VERSION ""

NS_ :

BS_:

BU_: SGW RFHM MPAD IPC GNMM EVCU2 ESL ECM DTCM DMSM BSM BCM AGSM ADCAM

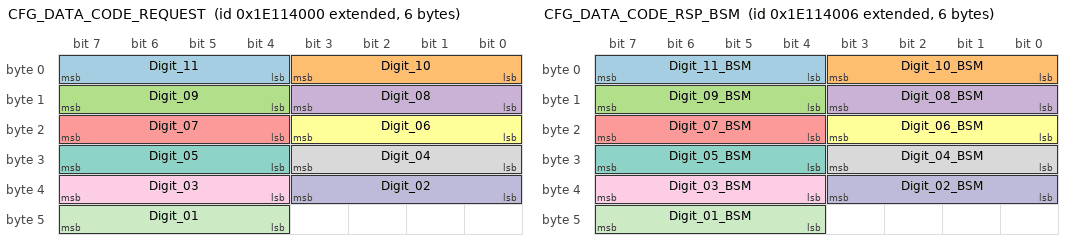
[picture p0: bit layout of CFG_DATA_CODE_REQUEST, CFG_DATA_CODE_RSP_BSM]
BO_ 2651930624 CFG_DATA_CODE_REQUEST: 6 BCM
 SG_ Digit_11 : 7|4@0+ (1,0) [0|15] "" ADCAM,MPAD,EVCU2,DMSM,GNMM,SGW,AGSM,ESL,BSM,IPC,RFHM,ECM,DTCM
 SG_ Digit_10 : 3|4@0+ (1,0) [0|15] "" ADCAM,MPAD,EVCU2,DMSM,GNMM,SGW,AGSM,ESL,BSM,IPC,RFHM,ECM,DTCM
 SG_ Digit_09 : 15|4@0+ (1,0) [0|15] "" ADCAM,MPAD,EVCU2,DMSM,GNMM,SGW,AGSM,ESL,BSM,IPC,RFHM,ECM,DTCM
 SG_ Digit_08 : 11|4@0+ (1,0) [0|15] "" ADCAM,MPAD,EVCU2,DMSM,GNMM,SGW,AGSM,ESL,BSM,IPC,RFHM,ECM,DTCM
 SG_ Digit_07 : 23|4@0+ (1,0) [0|15] "" ADCAM,MPAD,EVCU2,DMSM,GNMM,SGW,AGSM,ESL,BSM,IPC,RFHM,ECM,DTCM
 SG_ Digit_06 : 19|4@0+ (1,0) [0|15] "" ADCAM,MPAD,EVCU2,DMSM,GNMM,SGW,AGSM,ESL,BSM,IPC,RFHM,ECM,DTCM
 SG_ Digit_05 : 31|4@0+ (1,0) [0|15] "" ADCAM,MPAD,EVCU2,DMSM,GNMM,SGW,AGSM,ESL,BSM,IPC,RFHM,ECM,DTCM
 SG_ Digit_04 : 27|4@0+ (1,0) [0|15] "" ADCAM,MPAD,EVCU2,DMSM,GNMM,SGW,AGSM,ESL,BSM,IPC,RFHM,ECM,DTCM
 SG_ Digit_03 : 39|4@0+ (1,0) [0|15] "" ADCAM,MPAD,EVCU2,DMSM,GNMM,SGW,AGSM,ESL,BSM,IPC,RFHM,ECM,DTCM
 SG_ Digit_02 : 35|4@0+ (1,0) [0|15] "" ADCAM,MPAD,EVCU2,DMSM,GNMM,SGW,AGSM,ESL,BSM,IPC,RFHM,ECM,DTCM
 SG_ Digit_01 : 47|4@0+ (1,0) [0|15] "" ADCAM,MPAD,EVCU2,DMSM,GNMM,SGW,AGSM,ESL,BSM,IPC,RFHM,ECM,DTCM

BO_ 2651930630 CFG_DATA_CODE_RSP_BSM: 6 BSM
 SG_ Digit_11_BSM : 7|4@0+ (1,0) [0|15] "-"  BCM
 SG_ Digit_10_BSM : 3|4@0+ (1,0) [0|15] "-"  BCM
 SG_ Digit_09_BSM : 15|4@0+ (1,0) [0|15] "-"  BCM
 SG_ Digit_08_BSM : 11|4@0+ (1,0) [0|15] "-"  BCM
 SG_ Digit_07_BSM : 23|4@0+ (1,0) [0|15] "-"  BCM
 SG_ Digit_06_BSM : 19|4@0+ (1,0) [0|15] "-"  BCM
 SG_ Digit_05_BSM : 31|4@0+ (1,0) [0|15] "-"  BCM
 SG_ Digit_04_BSM : 27|4@0+ (1,0) [0|15] "-"  BCM
 SG_ Digit_03_BSM : 39|4@0+ (1,0) [0|15] "-"  BCM
 SG_ Digit_02_BSM : 35|4@0+ (1,0) [0|15] "-"  BCM
 SG_ Digit_01_BSM : 47|4@0+ (1,0) [0|15] "-"  BCM

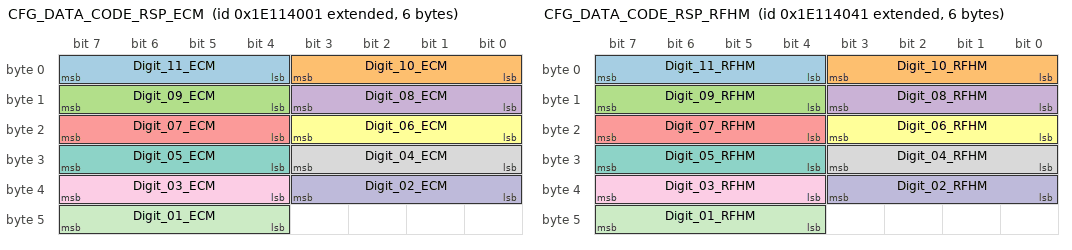
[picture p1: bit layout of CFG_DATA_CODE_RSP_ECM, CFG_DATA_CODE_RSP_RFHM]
BO_ 2651930625 CFG_DATA_CODE_RSP_ECM: 6 ECM
 SG_ Digit_11_ECM : 7|4@0+ (1,0) [0|15] "-"  BCM
 SG_ Digit_10_ECM : 3|4@0+ (1,0) [0|15] "-"  BCM
 SG_ Digit_09_ECM : 15|4@0+ (1,0) [0|15] "-"  BCM
 SG_ Digit_08_ECM : 11|4@0+ (1,0) [0|15] "-"  BCM
 SG_ Digit_07_ECM : 23|4@0+ (1,0) [0|15] "-"  BCM
 SG_ Digit_06_ECM : 19|4@0+ (1,0) [0|15] "-"  BCM
 SG_ Digit_05_ECM : 31|4@0+ (1,0) [0|15] "-"  BCM
 SG_ Digit_04_ECM : 27|4@0+ (1,0) [0|15] "-"  BCM
 SG_ Digit_03_ECM : 39|4@0+ (1,0) [0|15] "-"  BCM
 SG_ Digit_02_ECM : 35|4@0+ (1,0) [0|15] "-"  BCM
 SG_ Digit_01_ECM : 47|4@0+ (1,0) [0|15] "-"  BCM

BO_ 2651930689 CFG_DATA_CODE_RSP_RFHM: 6 RFHM
 SG_ Digit_11_RFHM : 7|4@0+ (1,0) [0|15] "-"  BCM
 SG_ Digit_10_RFHM : 3|4@0+ (1,0) [0|15] "-"  BCM
 SG_ Digit_09_RFHM : 15|4@0+ (1,0) [0|15] "-"  BCM
 SG_ Digit_08_RFHM : 11|4@0+ (1,0) [0|15] "-"  BCM
 SG_ Digit_07_RFHM : 23|4@0+ (1,0) [0|15] "-"  BCM
 SG_ Digit_06_RFHM : 19|4@0+ (1,0) [0|15] "-"  BCM
 SG_ Digit_05_RFHM : 31|4@0+ (1,0) [0|15] "-"  BCM
 SG_ Digit_04_RFHM : 27|4@0+ (1,0) [0|15] "-"  BCM
 SG_ Digit_03_RFHM : 39|4@0+ (1,0) [0|15] "-"  BCM
 SG_ Digit_02_RFHM : 35|4@0+ (1,0) [0|15] "-"  BCM
 SG_ Digit_01_RFHM : 47|4@0+ (1,0) [0|15] "-"  BCM

BO_ 2564440305 DIAGNOSTIC_REQUEST_BCM: 8 SGW
 SG_ N_PDU : 7|64@0+ (1,0) [0|0] "" BCM

BO_ 2564434161 DIAGNOSTIC_REQUEST_BSM: 8 SGW
 SG_ N_PDU : 7|64@0+ (1,0) [0|0] "" BSM

BO_ 2564428017 DIAGNOSTIC_REQUEST_ECM: 8 SGW
 SG_ N_PDU : 7|64@0+ (1,0) [0|0] "" ECM

BO_ 2564554481 DIAGNOSTIC_REQUEST_FUNCTIONAL: 8 SGW
 SG_ N_PDU : 7|64@0+ (1,0) [0|0] "" ADCAM,MPAD,DMSM,GNMM,AGSM,ESL,BCM,BSM,IPC,RFHM,ECM,DTCM

BO_ 2564502513 DIAGNOSTIC_REQUEST_FUNC_OBD: 8 SGW
 SG_ N_PDU : 7|64@0+ (1,0) [0|0] "" Vector__XXX

BO_ 2564448497 DIAGNOSTIC_REQUEST_IPC: 8 SGW
 SG_ N_PDU : 7|64@0+ (1,0) [0|0] "" IPC

BO_ 2564474865 DIAGNOSTIC_REQUEST_RFHM: 8 SGW
 SG_ N_PDU : 7|64@0+ (1,0) [0|0] "" RFHM

BO_ 2564485440 DIAGNOSTIC_RESPONSE_BCM: 8 BCM
 SG_ N_PDU : 7|64@0+ (1,0) [0|0] "" SGW

BO_ 2564485416 DIAGNOSTIC_RESPONSE_BSM: 8 BSM
 SG_ N_PDU : 7|64@0+ (1,0) [0|0] "" SGW

BO_ 2564485392 DIAGNOSTIC_RESPONSE_ECM: 8 ECM
 SG_ N_PDU : 7|64@0+ (1,0) [0|0] "" SGW

BO_ 2564485472 DIAGNOSTIC_RESPONSE_IPC: 8 IPC
 SG_ N_PDU : 7|64@0+ (1,0) [0|0] "" SGW

BO_ 2564485575 DIAGNOSTIC_RESPONSE_RFHM: 8 RFHM
 SG_ N_PDU : 7|64@0+ (1,0) [0|0] "" SGW

BO_ 2564485407 DIAGNOSTIC_RESPONSE_SHIFTER: 8 AGSM
 SG_ N_PDU : 7|64@0+ (1,0) [0|0] "" SGW

BO_ 2564485402 DIAGNOSTIC_RESPONSE_DTCM: 8 DTCM
 SG_ N_PDU : 7|64@0+ (1,0) [0|0] "" SGW

BO_ 2564431857 DIAGNOSTIC_REQUEST_SHIFTER: 8 SGW
 SG_ N_PDU : 7|64@0+ (1,0) [0|0] "" AGSM

BO_ 2564474097 DIAGNOSTIC_REQUEST_ESL: 8 SGW
 SG_ N_PDU : 7|64@0+ (1,0) [0|0] "" ESL

BO_ 2564430577 DIAGNOSTIC_REQUEST_DTCM: 8 SGW
 SG_ N_PDU : 7|64@0+ (1,0) [0|0] "" DTCM

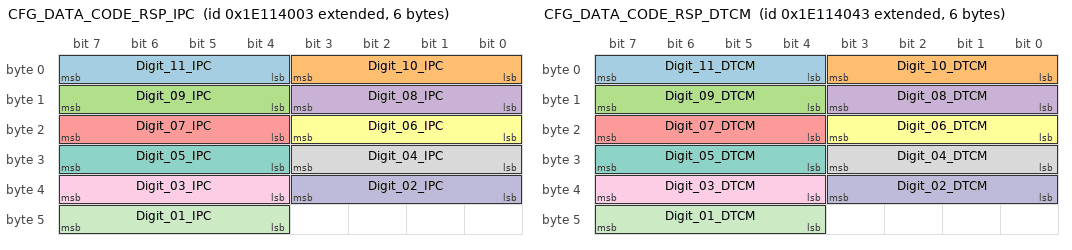
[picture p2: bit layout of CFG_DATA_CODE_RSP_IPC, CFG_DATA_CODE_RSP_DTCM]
BO_ 2651930627 CFG_DATA_CODE_RSP_IPC: 6 IPC
 SG_ Digit_11_IPC : 7|4@0+ (1,0) [0|15] "-"  BCM
 SG_ Digit_10_IPC : 3|4@0+ (1,0) [0|15] "-"  BCM
 SG_ Digit_09_IPC : 15|4@0+ (1,0) [0|15] "-"  BCM
 SG_ Digit_08_IPC : 11|4@0+ (1,0) [0|15] "-"  BCM
 SG_ Digit_07_IPC : 23|4@0+ (1,0) [0|15] "-"  BCM
 SG_ Digit_06_IPC : 19|4@0+ (1,0) [0|15] "-"  BCM
 SG_ Digit_05_IPC : 31|4@0+ (1,0) [0|15] "-"  BCM
 SG_ Digit_04_IPC : 27|4@0+ (1,0) [0|15] "-"  BCM
 SG_ Digit_03_IPC : 39|4@0+ (1,0) [0|15] "-"  BCM
 SG_ Digit_02_IPC : 35|4@0+ (1,0) [0|15] "-"  BCM
 SG_ Digit_01_IPC : 47|4@0+ (1,0) [0|15] "-"  BCM

BO_ 2651930691 CFG_DATA_CODE_RSP_DTCM: 6 DTCM
 SG_ Digit_11_DTCM : 7|4@0+ (1,0) [0|15] "-"  BCM
 SG_ Digit_10_DTCM : 3|4@0+ (1,0) [0|15] "-"  BCM
 SG_ Digit_09_DTCM : 15|4@0+ (1,0) [0|15] "-"  BCM
 SG_ Digit_08_DTCM : 11|4@0+ (1,0) [0|15] "-"  BCM
 SG_ Digit_07_DTCM : 23|4@0+ (1,0) [0|15] "-"  BCM
 SG_ Digit_06_DTCM : 19|4@0+ (1,0) [0|15] "-"  BCM
 SG_ Digit_05_DTCM : 31|4@0+ (1,0) [0|15] "-"  BCM
 SG_ Digit_04_DTCM : 27|4@0+ (1,0) [0|15] "-"  BCM
 SG_ Digit_03_DTCM : 39|4@0+ (1,0) [0|15] "-"  BCM
 SG_ Digit_02_DTCM : 35|4@0+ (1,0) [0|15] "-"  BCM
 SG_ Digit_01_DTCM : 47|4@0+ (1,0) [0|15] "-"  BCM

BO_ 2564485572 DIAGNOSTIC_RESPONSE_ESL: 8 ESL
 SG_ N_PDU : 7|64@0+ (1,0) [0|0] "" SGW

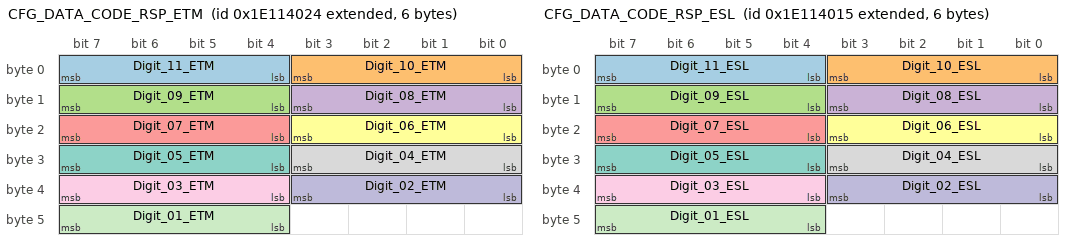
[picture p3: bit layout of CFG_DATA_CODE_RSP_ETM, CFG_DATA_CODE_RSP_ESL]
BO_ 2651930660 CFG_DATA_CODE_RSP_ETM: 6 SGW
 SG_ Digit_11_ETM : 7|4@0+ (1,0) [0|15] "-"  BCM
 SG_ Digit_10_ETM : 3|4@0+ (1,0) [0|15] "-"  BCM
 SG_ Digit_09_ETM : 15|4@0+ (1,0) [0|15] "-"  BCM
 SG_ Digit_08_ETM : 11|4@0+ (1,0) [0|15] "-"  BCM
 SG_ Digit_07_ETM : 23|4@0+ (1,0) [0|15] "-"  BCM
 SG_ Digit_06_ETM : 19|4@0+ (1,0) [0|15] "-"  BCM
 SG_ Digit_05_ETM : 31|4@0+ (1,0) [0|15] "-"  BCM
 SG_ Digit_04_ETM : 27|4@0+ (1,0) [0|15] "-"  BCM
 SG_ Digit_03_ETM : 39|4@0+ (1,0) [0|15] "-"  BCM
 SG_ Digit_02_ETM : 35|4@0+ (1,0) [0|15] "-"  BCM
 SG_ Digit_01_ETM : 47|4@0+ (1,0) [0|15] "-"  BCM

BO_ 2651930645 CFG_DATA_CODE_RSP_ESL: 6 ESL
 SG_ Digit_11_ESL : 7|4@0+ (1,0) [0|15] "-"  BCM
 SG_ Digit_10_ESL : 3|4@0+ (1,0) [0|15] "-"  BCM
 SG_ Digit_09_ESL : 15|4@0+ (1,0) [0|15] "-"  BCM
 SG_ Digit_08_ESL : 11|4@0+ (1,0) [0|15] "-"  BCM
 SG_ Digit_07_ESL : 23|4@0+ (1,0) [0|15] "-"  BCM
 SG_ Digit_06_ESL : 19|4@0+ (1,0) [0|15] "-"  BCM
 SG_ Digit_05_ESL : 31|4@0+ (1,0) [0|15] "-"  BCM
 SG_ Digit_04_ESL : 27|4@0+ (1,0) [0|15] "-"  BCM
 SG_ Digit_03_ESL : 39|4@0+ (1,0) [0|15] "-"  BCM
 SG_ Digit_02_ESL : 35|4@0+ (1,0) [0|15] "-"  BCM
 SG_ Digit_01_ESL : 47|4@0+ (1,0) [0|15] "-"  BCM

BO_ 1053 VIN: 32 BCM
 SG_ VIN_MSG : 75|2@0+ (1,0) [0|3] "" ADCAM,MPAD,EVCU2,DMSM,GNMM,SGW,AGSM,ESL,BSM,IPC,RFHM,ECM,DTCM
 SG_ VIN_DATA : 87|56@0+ (1,0) [0|72057594037927900] "" ADCAM,MPAD,EVCU2,DMSM,GNMM,SGW,AGSM,ESL,BSM,IPC,RFHM,ECM,DTCM

BO_ 254 TRM_MKP_KEY: 32 RFHM
 SG_ TotalFrameNumber : 83|4@0+ (1,0) [0|15] "-"  BCM
 SG_ FrameNumber : 87|4@0+ (1,0) [0|15] "-"  BCM
 SG_ DATA7 : 143|8@0+ (1,0) [0|255] "-"  BCM
 SG_ DATA6 : 135|8@0+ (1,0) [0|255] "-"  BCM
 SG_ DATA5 : 127|8@0+ (1,0) [0|255] "-"  BCM
 SG_ DATA4 : 119|8@0+ (1,0) [0|255] "-"  BCM
 SG_ DATA3 : 111|8@0+ (1,0) [0|255] "-"  BCM
 SG_ DATA2 : 103|8@0+ (1,0) [0|255] "-"  BCM
 SG_ DATA1 : 95|8@0+ (1,0) [0|255] "-"  BCM

BO_ 1059 TRM_CODE_RESPONSE: 32 RFHM
 SG_ TxpFound : 111|1@0+ (1,0) [0|1] "-"  BCM
 SG_ ProgrammedSts_TRM : 110|1@0+ (1,0) [0|1] "-"  BCM
 SG_ MiniCryptGCode_TRM_Rsp : 95|16@0+ (1,0) [0|65535] "-"  BCM
 SG_ ControlEncoding_TRM_Rsp : 87|8@0+ (1,0) [0|255] "-"  BCM
 SG_ CodeCheckSts_TRM : 109|2@0+ (1,0) [0|3] "-"  BCM
 SG_ TxpID3 : 15|7@0+ (1,0) [0|127] "-"  BCM

BO_ 1450 TRANSM_FD_4: 32 EVCU2
 SG_ OilTemperatureSts : 86|1@0+ (1,0) [0|1] "-"  SGW,IPC

BO_ 1428 TELEMATIC_FD_5: 32 SGW
 SG_ HU_CMP : 174|4@0+ (1,0) [0|0] "" BCM
 SG_ NAV_UNITS : 42|3@0+ (1,0) [0|7] "" IPC
 SG_ DIST_TO_TURN : 63|16@0+ (1,0) [0|65534] "" MPAD,IPC
 SG_ TURN_COMP : 33|1@0+ (1,0) [0|1] "" MPAD,IPC
 SG_ T_BY_T_ON : 32|1@0+ (1,0) [0|1] "" MPAD,IPC
 SG_ NAVPrsnt : 43|1@0+ (1,0) [0|1] "" IPC
 SG_ NAV_ARROW : 55|8@0+ (1,0) [1|255] "Arrow"  MPAD,IPC
 SG_ MessageCounter_Telematic5 : 179|4@0+ (1,0) [0|15] "-"  MPAD,BCM,IPC
 SG_ CRC_Telematic5 : 191|8@0+ (1,0) [0|255] "-"  MPAD,BCM,IPC

BO_ 156 TELEMATIC_FD_1: 32 SGW
 SG_ Year4_TLM : 127|4@0+ (1,0) [0|9] "-"  EVCU2,RFHM
 SG_ Year3_TLM : 115|4@0+ (1,0) [0|9] "-"  EVCU2,RFHM
 SG_ Year2_TLM : 119|4@0+ (1,0) [0|9] "-"  EVCU2,RFHM
 SG_ Year1_TLM : 107|4@0+ (1,0) [0|2] "-"  EVCU2,RFHM
 SG_ Month2_TLM : 111|4@0+ (1,0) [0|9] "-"  EVCU2,RFHM
 SG_ Month1_TLM : 99|4@0+ (1,0) [0|1] "-"  EVCU2,RFHM
 SG_ Minute2_TLM : 103|4@0+ (1,0) [0|9] "-"  EVCU2,IPC,RFHM
 SG_ Minute1_TLM : 91|4@0+ (1,0) [0|5] "-"  EVCU2,IPC,RFHM
 SG_ Hour2_TLM : 95|4@0+ (1,0) [0|9] "-"  EVCU2,IPC,RFHM
 SG_ Hour1_TLM : 83|4@0+ (1,0) [0|2] "-"  EVCU2,IPC,RFHM
 SG_ Day2_TLM : 87|4@0+ (1,0) [0|9] "-"  EVCU2,RFHM
 SG_ Day1_TLM : 75|4@0+ (1,0) [0|3] "-"  EVCU2,RFHM
 SG_ GPS_UTC_Second : 151|16@0+ (0.01,0) [0|59.99] "s"  EVCU2,DMSM
 SG_ GPS_UTC_Minute : 47|8@0+ (1,0) [0|59] "min"  EVCU2,DMSM
 SG_ GPS_UTC_Hour : 55|8@0+ (1,0) [0|23] "h"  EVCU2,DMSM
 SG_ GPS_Date_Year : 167|16@0+ (1,0) [0|65534] "Years"  EVCU2,DMSM,RFHM
 SG_ GPS_Date_Month : 71|8@0+ (1,0) [1|12] "Months"  EVCU2,DMSM,RFHM
 SG_ GPS_Date_Day : 63|8@0+ (1,0) [1|31] "Days"  EVCU2,DMSM,RFHM
 SG_ STFARrAlertPress : 15|8@0+ (1,0) [0|254] "psi"  RFHM
 SG_ STFAFtAlertPress : 7|8@0+ (1,0) [0|254] "psi"  RFHM
 SG_ TSI_Offset_Mph_Req : 135|4@0+ (1,0) [0|15] "-"  IPC
 SG_ TSI_Offset_Kph_Req : 131|4@0+ (1,0) [0|15] "-"  IPC
 SG_ ParkSenseSignalView_Req : 34|1@0+ (1,0) [0|1] "" IPC
 SG_ TurnSignalView_Req : 36|2@0+ (1,0) [0|3] "" IPC
 SG_ Fuel_Saver_Display_Req : 25|1@0+ (1,0) [0|1] "" IPC
 SG_ EPB_Service_Mode_Req : 37|1@0+ (1,0) [0|1] "" IPC

BO_ 1378 STEER_LOCK_FD_1: 32 ESL
 SG_ ESLSts : 87|3@0+ (1,0) [0|7] "-"  BCM

BO_ 1876 RFHUB_FD_3: 32 RFHM
 SG_ TyrePressureSystemFailSts : 88|1@0+ (1,0) [0|1] "-"  MPAD,SGW,BCM,IPC
 SG_ TyrePressureSysProgrammedSts : 89|1@0+ (1,0) [0|1] "-"  IPC
 SG_ TPMActivitySts : 87|1@0+ (1,0) [0|1] "-"  BCM,IPC
 SG_ InflationState_RHR_Tyre : 95|3@0+ (1,0) [0|4] "-"  MPAD,SGW,BCM,IPC
 SG_ InflationState_RHF_Tyre : 86|3@0+ (1,0) [0|4] "-"  MPAD,SGW,BCM,IPC
 SG_ InflationState_LHR_Tyre : 92|3@0+ (1,0) [0|4] "-"  MPAD,SGW,BCM,IPC
 SG_ InflationState_LHF_Tyre : 83|3@0+ (1,0) [0|4] "-"  MPAD,SGW,BCM,IPC
 SG_ PressureValue_RHR_Tyre : 127|8@0+ (0.03529,0) [0|8.96366] "bar"  MPAD,SGW,BCM,IPC
 SG_ PressureValue_RHF_Tyre : 111|8@0+ (0.03529,0) [0|8.96366] "bar"  MPAD,SGW,BCM,IPC
 SG_ PressureValue_LHR_Tyre : 135|8@0+ (0.03529,0) [0|8.96366] "bar"  MPAD,SGW,BCM,IPC
 SG_ PressureValue_LHF_Tyre : 119|8@0+ (0.03529,0) [0|8.96366] "bar"  MPAD,SGW,BCM,IPC
 SG_ MessageCounter_RFHUB3 : 179|4@0+ (1,0) [0|15] "-"  MPAD,EVCU2,SGW,IPC
 SG_ CRC_RFHUB3 : 191|8@0+ (1,0) [0|255] "-"  MPAD,EVCU2,SGW,IPC

BO_ 1449 RFHUB_FD_2: 32 RFHM
 SG_ MsgNotInPark : 91|2@0+ (1,0) [0|3] "-"  IPC
 SG_ MsgFOBNotFnd : 93|2@0+ (1,0) [0|2] "-"  IPC
 SG_ MsgFOBLeftVeh : 95|2@0+ (1,0) [0|2] "-"  BCM,IPC
 SG_ KeyProgramSts : 83|4@0+ (1,0) [0|15] "-"  IPC
 SG_ RFMemRq : 96|1@0+ (1,0) [0|1] "-"  BCM
 SG_ FOBSearchActive : 85|1@0+ (1,0) [0|1] "" Vector__XXX
 SG_ MsgPushBtnKey : 2|2@0+ (1,0) [0|2] "-"  IPC
 SG_ TPMHornChirp : 6|2@0+ (1,0) [0|3] "-"  BCM
 SG_ TPMHazardFlash : 7|1@0+ (1,0) [0|1] "-"  BCM,IPC
 SG_ STFASysEnableFault : 3|1@0+ (1,0) [0|1] "-"  BCM
 SG_ RrTrPlacardPress : 31|16@0+ (0.0145,0) [0|950.2575] "psi"  BCM,IPC
 SG_ KeyFob_Present : 4|1@0+ (1,0) [0|1] "-"  BCM
 SG_ FtTrPlacardPress : 15|16@0+ (0.0145,0) [0|950.2575] "psi"  BCM,IPC
 SG_ MsgKeyNotFnd : 63|2@0+ (1,0) [0|3] "-"  IPC
 SG_ MemRq_FobNum3 : 110|7@0+ (1,0) [0|127] "" BCM

BO_ 519 RFHUB_FD_1: 32 RFHM
 SG_ RFReq : 119|3@0+ (1,0) [0|6] "-"  SGW,BCM,IPC
 SG_ IgnPosSts : 85|3@0+ (1,0) [0|6] "-"  SGW,BCM
 SG_ FobSearchResult : 103|8@0+ (1,0) [0|255] "-"  BCM
 SG_ DriverEngineOffRequest : 95|1@0+ (1,0) [0|1] "-"  EVCU2,BCM
 SG_ CustKeyInIgnSts : 87|2@0+ (1,0) [0|2] "-"  SGW,BCM
 SG_ MessageCounter_RFHUB1 : 179|4@0+ (1,0) [0|15] "-"  EVCU2
 SG_ CRC_RFHUB1 : 191|8@0+ (1,0) [0|255] "-"  EVCU2
 SG_ RFFuncReq : 92|5@0+ (1,0) [0|30] "" SGW,BCM,IPC
 SG_ ValetMode_SPAAK : 180|1@0+ (1,0) [0|1] "" SGW
 SG_ RFFobNum3 : 134|7@0+ (1,0) [0|127] "-"  SGW,BCM
 SG_ KeyAuth_Status : 94|2@0+ (1,0) [0|3] "-"  IPC

CM_ "Project_KM_ProjectStandard_FD-CAN3 [CS00155_FD]";
CM_ SG_ 2564440305 N_PDU "This signal is used for diagnostic purposes";
CM_ SG_ 2564434161 N_PDU "This signal is used for diagnostic purposes";
CM_ SG_ 2564428017 N_PDU "This signal is used for diagnostic purposes";
CM_ SG_ 2564554481 N_PDU "This signal is used for diagnostic purposes";
CM_ SG_ 2564502513 N_PDU "This signal is used for diagnostic purposes";
CM_ SG_ 2564448497 N_PDU "This signal is used for diagnostic purposes";
CM_ SG_ 2564474865 N_PDU "This signal is used for diagnostic purposes";
CM_ SG_ 2564485440 N_PDU "This signal is used for diagnostic purposes";
CM_ SG_ 2564485416 N_PDU "This signal is used for diagnostic purposes";
CM_ SG_ 2564485392 N_PDU "This signal is used for diagnostic purposes";
CM_ SG_ 2564485472 N_PDU "This signal is used for diagnostic purposes";
CM_ SG_ 2564485575 N_PDU "This signal is used for diagnostic purposes";
CM_ SG_ 2564485407 N_PDU "This signal is used for diagnostic purposes";
CM_ SG_ 2564485402 N_PDU "This signal is used for diagnostic purposes";
CM_ SG_ 2564431857 N_PDU "This signal is used for diagnostic purposes";
CM_ SG_ 2564474097 N_PDU "This signal is used for diagnostic purposes";
CM_ SG_ 2564430577 N_PDU "This signal is used for diagnostic purposes";
CM_ SG_ 2564485572 N_PDU "This signal is used for diagnostic purposes";
CM_ SG_ 1053 VIN_MSG "VIN Message Information";
CM_ SG_ 1053 VIN_DATA "VIN Digits (8 bit ascii encoded)";
CM_ SG_ 254 DATA1 "-";
CM_ SG_ 254 DATA2 "-";
CM_ SG_ 254 DATA3 "-";
CM_ SG_ 254 DATA4 "-";
CM_ SG_ 254 DATA5 "-";
CM_ SG_ 254 DATA6 "-";
CM_ SG_ 254 DATA7 "-";
CM_ SG_ 254 FrameNumber "-";
CM_ SG_ 254 TotalFrameNumber "-";
CM_ SG_ 1059 ProgrammedSts_TRM "This signal  is used to indicate if the TRM is programmed.";
CM_ SG_ 1059 TxpFound "This signal is used to give information about the presence of a transponder";
CM_ SG_ 1059 MiniCryptGCode_TRM_Rsp "-";
CM_ SG_ 1059 TxpID3 "Key ID's";
CM_ SG_ 1059 ControlEncoding_TRM_Rsp "-";
CM_ SG_ 1059 CodeCheckSts_TRM "This signal is used to indicate the result of the code check.";
CM_ SG_ 1450 OilTemperatureSts "-";
CM_ SG_ 1428 TURN_COMP "Turn complete";
CM_ SG_ 1428 T_BY_T_ON "Turn by turn on";
CM_ SG_ 1428 NAVPrsnt "A navigation system module is present";
CM_ SG_ 1428 NAV_UNITS "Unit of measure";
CM_ SG_ 1428 NAV_ARROW "Navigation arrow type";
CM_ SG_ 1428 HU_CMP "Radio compass direction";
CM_ SG_ 1428 DIST_TO_TURN "Numeric distance to next turn";
CM_ SG_ 1428 MessageCounter_Telematic5 "This signal is a counter used for safety checks strategies. This counter is incremented of 1 (one) unit at each frame transmission.";
CM_ SG_ 1428 CRC_Telematic5 "CRC according to SAE J1850 standard at each frame transmission.";
CM_ SG_ 156 TurnSignalView_Req "Turn Signal Activated Blind Spot Camera View with and without Trailer Options";
CM_ SG_ 156 TSI_Offset_Mph_Req "TSI_Offset_Mph_Req";
CM_ SG_ 156 TSI_Offset_Kph_Req "TSI_Offset_Kph_Req";
CM_ SG_ 156 STFARrAlertPress "Selectable Tire Fill Alert Rear Alert Pressure";
CM_ SG_ 156 STFAFtAlertPress "Selectable Tire Fill Alert Front Alert Pressure";
CM_ SG_ 156 ParkSenseSignalView_Req "ParkSense Based Camera Activation settings";
CM_ SG_ 156 GPS_UTC_Second "GPS UTC second";
CM_ SG_ 156 GPS_UTC_Minute "GPS UTC minute";
CM_ SG_ 156 GPS_UTC_Hour "GPS UTC hour";
CM_ SG_ 156 GPS_Date_Year "GPS date year";
CM_ SG_ 156 GPS_Date_Month "GPS date month";
CM_ SG_ 156 GPS_Date_Day "GPS date day";
CM_ SG_ 156 Fuel_Saver_Display_Req "Fuel saver display indicator status (1=enabled)";
CM_ SG_ 156 EPB_Service_Mode_Req "EPB service mode; Service mode = [1]";
CM_ SG_ 1378 ESLSts "-";
CM_ SG_ 1876 PressureValue_LHF_Tyre "It is the value of indicated tyre wheel [bar]";
CM_ SG_ 1876 MessageCounter_RFHUB3 "This signal is a counter used for safety checks strategies. This counter is incremented of 1 (one) unit at each frame transmission.";
CM_ SG_ 1876 InflationState_RHR_Tyre "It signal indicated the state for the pressure of the wheel identified";
CM_ SG_ 1876 InflationState_RHF_Tyre "It signal indicated the state for the pressure of the wheel identified";
CM_ SG_ 1876 InflationState_LHR_Tyre "It signal indicated the state for the pressure of the wheel identified";
CM_ SG_ 1876 InflationState_LHF_Tyre "It signal indicated the state for the pressure of the wheel identified";
CM_ SG_ 1876 CRC_RFHUB3 "CRC according to SAE J1850 standard at each frame transmission.";
CM_ SG_ 1876 TyrePressureSysProgrammedSts "It indicates the TPMS ECU programming status.";
CM_ SG_ 1876 TPMActivitySts "It indicates whether the TPMS ECU is enabled or disabled.";
CM_ SG_ 1876 TyrePressureSystemFailSts "It indicates that the TPM System is in Fault or not";
CM_ SG_ 1876 PressureValue_RHR_Tyre "It is the value of indicated tyre wheel [bar]";
CM_ SG_ 1876 PressureValue_RHF_Tyre "It is the value of indicated tyre wheel [bar]";
CM_ SG_ 1876 PressureValue_LHR_Tyre "It is the value of indicated tyre wheel [bar]";
CM_ SG_ 1449 MemRq_FobNum3 "FOB/SPAAK device number making the request";
CM_ SG_ 1449 KeyProgramSts "-";
CM_ SG_ 1449 MsgKeyNotFnd "Keyfob or Digital Key Presence Status";
CM_ SG_ 1449 MsgPushBtnKey "MsgPushBtnKey.";
CM_ SG_ 1449 MsgNotInPark "-";
CM_ SG_ 1449 KeyFob_Present "Active entry polling feature reports whether key fob is in detection zone or not.";
CM_ SG_ 1449 FtTrPlacardPress "FtTrPlacardPress";
CM_ SG_ 1449 FOBSearchActive "Signal informing that the RFHM is performing a FOB search.";
CM_ SG_ 1449 MsgFOBNotFnd "FOB Not Detected.";
CM_ SG_ 1449 MsgFOBLeftVeh "FOB left vehicle";
CM_ SG_ 1449 TPMHornChirp "TPM horn chirp";
CM_ SG_ 1449 TPMHazardFlash "TPM hazard flash;  true = [1]";
CM_ SG_ 1449 STFASysEnableFault "STFA system enable fault; Absent = [0], Present = [1]";
CM_ SG_ 1449 RrTrPlacardPress "RrTrPlacardPress";
CM_ SG_ 1449 RFMemRq "RF memory request";
CM_ SG_ 519 ValetMode_SPAAK "Valet Mode Information";
CM_ SG_ 519 RFReq "-";
CM_ SG_ 519 RFFuncReq "-";
CM_ SG_ 519 RFFobNum3 "Key ID information";
CM_ SG_ 519 MessageCounter_RFHUB1 "This signal is a counter used for safety checks strategies. This counter is incremented of 1 (one) unit at each frame transmission.";
CM_ SG_ 519 KeyAuth_Status "Key Authentication Status";
CM_ SG_ 519 IgnPosSts "-";
CM_ SG_ 519 FobSearchResult "FOB search result";
CM_ SG_ 519 DriverEngineOffRequest "The signal is used to inform that an engine shut off is requried by the driver";
CM_ SG_ 519 CustKeyInIgnSts "-";
CM_ SG_ 519 CRC_RFHUB1 "CRC according to SAE J1850 standard at each frame transmission.";
BA_DEF_ BU_ "NwmNodeType" ENUM "+15_NotWakeable","+30_Wakeable","+30_NotWakeable","kMaster","kSlave15","kSlave30","none";
BA_DEF_ BU_ "NmNodeType" ENUM "+15_NotWakeable","+30_Wakeable","+30_NotWakeable","kMaster","kSlave15","kSlave30","none";
BA_DEF_ BU_ "NmAsrCanMsgReducedTime" INT 1 65535;
BA_DEF_ BU_ "NmAsrNodeIdentifier" HEX 0 255;
BA_DEF_ BU_ "NmAsrNode" ENUM "No","Yes";
BA_DEF_ BU_ "NmNode" ENUM "No","Yes";
BA_DEF_ BU_ "NmStationAddress" HEX 0 255;
BA_DEF_ BU_ "Description" STRING ;
BA_DEF_ "VersionYear" INT 0 99;
BA_DEF_ "VersionWeek" INT 0 53;
BA_DEF_ "Version" HEX 0 255;
BA_DEF_ "NmAsrCanMsgCycleTime" INT 1 65535;
BA_DEF_ "NmAsrBaseAddress" HEX 235487232 2147483647;
BA_DEF_ "NmAsrMessageCount" INT 1 256;
BA_DEF_ "NmAsrRepeatMessageTime" INT 1 65535;
BA_DEF_ "NmAsrWaitBusSleepTime" INT 1 65535;
BA_DEF_ "NmAsrTimeoutTime" INT 1 65535;
BA_DEF_ "DBName" STRING ;
BA_DEF_ "Baudrate" INT 0 1000000;
BA_DEF_ "BusType" STRING ;
BA_DEF_ "NmType" STRING ;
BA_DEF_ "Manufacturer" STRING ;
BA_DEF_ BO_ "CANFD_BRS" ENUM "0","1";
BA_DEF_ BO_ "VFrameFormat" ENUM "StandardCAN","ExtendedCAN","reserved","reserved","reserved","reserved","reserved","reserved","reserved","reserved","reserved","reserved","reserved","reserved","StandardCAN_FD","ExtendedCAN_FD";
BA_DEF_ BO_ "DiagConnection" HEX 0 65535;
BA_DEF_ BO_ "DiagState" ENUM "No","Yes";
BA_DEF_ BO_ "NmAsrMessage" ENUM "No","Yes";
BA_DEF_ BO_ "GenMsgDelayTime" INT 0 65535;
BA_DEF_ BO_ "GenMsgCycleTime" INT 0 65535;
BA_DEF_ BO_ "GenMsgCycleTimeFast" INT 0 65535;
BA_DEF_ BO_ "GenMsgStartDelayTime" INT 0 65535;
BA_DEF_ BO_ "GenMsgILSupport" ENUM "No","Yes";
BA_DEF_ BO_ "GenMsgNrOfRepetition" INT 0 255;
BA_DEF_ BO_ "GenMsgSendType" ENUM "Cyclic","NotUsed","NotUsed","NotUsed","NotUsed","NotUsed","NotUsed","NotUsed","NoMsgSendType";
BA_DEF_ BO_ "NmMessage" ENUM "No","Yes";
BA_DEF_ BO_ "DiagResponse" ENUM "No","Yes";
BA_DEF_ BO_ "Type" ENUM "P","C","PE","COC","PE_Cntrl","E","E_Cntrl","OC","S","BAF","DC","EM","MM","ISO-TP","-";
BA_DEF_ BO_ "DiagRequest" ENUM "No","Yes";
BA_DEF_ SG_ "GenSigTimeoutTime_SGW" INT 0 65535;
BA_DEF_ SG_ "GenSigTimeoutTime_RFHM" INT 0 65535;
BA_DEF_ SG_ "GenSigTimeoutTime_MPAD" INT 0 65535;
BA_DEF_ SG_ "GenSigTimeoutTime_IPC" INT 0 65535;
BA_DEF_ SG_ "GenSigTimeoutTime_GNMM" INT 0 65535;
BA_DEF_ SG_ "GenSigTimeoutTime_EVCU2" INT 0 65535;
BA_DEF_ SG_ "GenSigTimeoutTime_ESL" INT 0 65535;
BA_DEF_ SG_ "GenSigTimeoutTime_ECM" INT 0 65535;
BA_DEF_ SG_ "GenSigTimeoutTime_DTCM" INT 0 65535;
BA_DEF_ SG_ "GenSigTimeoutTime_DMSM" INT 0 65535;
BA_DEF_ SG_ "GenSigTimeoutTime_BSM" INT 0 65535;
BA_DEF_ SG_ "GenSigTimeoutTime_BCM" INT 0 65535;
BA_DEF_ SG_ "GenSigTimeoutTime_AGSM" INT 0 65535;
BA_DEF_ SG_ "GenSigTimeoutTime_ADCAM" INT 0 65535;
BA_DEF_ SG_ "SystemSignalLongSymbol" STRING ;
BA_DEF_ SG_ "GenSigSendType" ENUM "NotUsed","OnWrite","OnWriteWithRepetition","OnChange","OnChangeWithRepetition","IfActive","IfActiveWithRepetition","NoSigSendType";
BA_DEF_ SG_ "GenSigInactiveValue" INT 0 2147483647;
BA_DEF_ SG_ "GenSigStartValue" INT 0 2147483647;
BA_DEF_DEF_ "NwmNodeType" "none";
BA_DEF_DEF_ "NmNodeType" "none";
BA_DEF_DEF_ "NmAsrCanMsgReducedTime" 100;
BA_DEF_DEF_ "NmAsrNodeIdentifier" 0;
BA_DEF_DEF_ "NmAsrNode" "Yes";
BA_DEF_DEF_ "NmNode" "Yes";
BA_DEF_DEF_ "NmStationAddress" 0;
BA_DEF_DEF_ "Description" "";
BA_DEF_DEF_ "VersionYear" 23;
BA_DEF_DEF_ "VersionWeek" 46;
BA_DEF_DEF_ "Version" 160;
BA_DEF_DEF_ "NmAsrCanMsgCycleTime" 200;
BA_DEF_DEF_ "NmAsrBaseAddress" 506724352;
BA_DEF_DEF_ "NmAsrMessageCount" 256;
BA_DEF_DEF_ "NmAsrRepeatMessageTime" 800;
BA_DEF_DEF_ "NmAsrWaitBusSleepTime" 750;
BA_DEF_DEF_ "NmAsrTimeoutTime" 1000;
BA_DEF_DEF_ "DBName" "CAN";
BA_DEF_DEF_ "Baudrate" 500000;
BA_DEF_DEF_ "BusType" "CAN";
BA_DEF_DEF_ "NmType" "";
BA_DEF_DEF_ "Manufacturer" "Fiat";
BA_DEF_DEF_ "CANFD_BRS" "0";
BA_DEF_DEF_ "VFrameFormat" "StandardCAN_FD";
BA_DEF_DEF_ "DiagConnection" 0;
BA_DEF_DEF_ "DiagState" "No";
BA_DEF_DEF_ "NmAsrMessage" "No";
BA_DEF_DEF_ "GenMsgDelayTime" 0;
BA_DEF_DEF_ "GenMsgCycleTime" 0;
BA_DEF_DEF_ "GenMsgCycleTimeFast" 0;
BA_DEF_DEF_ "GenMsgStartDelayTime" 0;
BA_DEF_DEF_ "GenMsgILSupport" "No";
BA_DEF_DEF_ "GenMsgNrOfRepetition" 0;
BA_DEF_DEF_ "GenMsgSendType" "NoMsgSendType";
BA_DEF_DEF_ "NmMessage" "No";
BA_DEF_DEF_ "DiagResponse" "No";
BA_DEF_DEF_ "Type" "-";
BA_DEF_DEF_ "DiagRequest" "No";
BA_DEF_DEF_ "GenSigTimeoutTime_SGW" 2500;
BA_DEF_DEF_ "GenSigTimeoutTime_RFHM" 2500;
BA_DEF_DEF_ "GenSigTimeoutTime_MPAD" 2500;
BA_DEF_DEF_ "GenSigTimeoutTime_IPC" 2500;
BA_DEF_DEF_ "GenSigTimeoutTime_GNMM" 2500;
BA_DEF_DEF_ "GenSigTimeoutTime_EVCU2" 2500;
BA_DEF_DEF_ "GenSigTimeoutTime_ESL" 2500;
BA_DEF_DEF_ "GenSigTimeoutTime_ECM" 2500;
BA_DEF_DEF_ "GenSigTimeoutTime_DTCM" 2500;
BA_DEF_DEF_ "GenSigTimeoutTime_DMSM" 2500;
BA_DEF_DEF_ "GenSigTimeoutTime_BSM" 2500;
BA_DEF_DEF_ "GenSigTimeoutTime_BCM" 2500;
BA_DEF_DEF_ "GenSigTimeoutTime_AGSM" 2500;
BA_DEF_DEF_ "GenSigTimeoutTime_ADCAM" 2500;
BA_DEF_DEF_ "SystemSignalLongSymbol" "";
BA_DEF_DEF_ "GenSigSendType" "NoSigSendType";
BA_DEF_DEF_ "GenSigInactiveValue" 0;
BA_DEF_DEF_ "GenSigStartValue" 0;
BA_ "NmAsrCanMsgCycleTime" 1000;
BA_ "NmAsrBaseAddress" 507002880;
BA_ "NmAsrRepeatMessageTime" 5000;
BA_ "NmAsrWaitBusSleepTime" 1000;
BA_ "NmAsrTimeoutTime" 8000;
BA_ "DBName" "FDCAN3";
BA_ "BusType" "CAN FD";
BA_ "NmType" "NmAsr";
BA_ "NwmNodeType" BU_ SGW 1;
BA_ "NmNodeType" BU_ SGW 1;
BA_ "NmAsrCanMsgReducedTime" BU_ SGW 800;
BA_ "NmAsrNodeIdentifier" BU_ SGW 112;
BA_ "NmStationAddress" BU_ SGW 112;
BA_ "Description" BU_ SGW "Security Gateway Module";
BA_ "NwmNodeType" BU_ RFHM 1;
BA_ "NmNodeType" BU_ RFHM 1;
BA_ "NmAsrCanMsgReducedTime" BU_ RFHM 675;
BA_ "NmAsrNodeIdentifier" BU_ RFHM 65;
BA_ "NmStationAddress" BU_ RFHM 65;
BA_ "Description" BU_ RFHM "Radio Frequency Hub Module";
BA_ "NwmNodeType" BU_ MPAD 1;
BA_ "NmNodeType" BU_ MPAD 1;
BA_ "NmAsrCanMsgReducedTime" BU_ MPAD 900;
BA_ "NmAsrNodeIdentifier" BU_ MPAD 173;
BA_ "NmStationAddress" BU_ MPAD 173;
BA_ "Description" BU_ MPAD "Mid Platform Automated Driving";
BA_ "NwmNodeType" BU_ IPC 1;
BA_ "NmNodeType" BU_ IPC 1;
BA_ "NmAsrCanMsgReducedTime" BU_ IPC 650;
BA_ "NmAsrNodeIdentifier" BU_ IPC 3;
BA_ "NmStationAddress" BU_ IPC 3;
BA_ "Description" BU_ IPC "Instrument Panel Cluster";
BA_ "NwmNodeType" BU_ GNMM 1;
BA_ "NmNodeType" BU_ GNMM 1;
BA_ "NmAsrCanMsgReducedTime" BU_ GNMM 850;
BA_ "NmAsrNodeIdentifier" BU_ GNMM 144;
BA_ "NmStationAddress" BU_ GNMM 144;
BA_ "Description" BU_ GNMM "Global Navigation and Motion Module";
BA_ "NwmNodeType" BU_ EVCU2 1;
BA_ "NmNodeType" BU_ EVCU2 1;
BA_ "NmAsrCanMsgReducedTime" BU_ EVCU2 950;
BA_ "NmAsrNodeIdentifier" BU_ EVCU2 64;
BA_ "NmStationAddress" BU_ EVCU2 64;
BA_ "Description" BU_ EVCU2 "Electric Vehicle Control Unit 2";
BA_ "NwmNodeType" BU_ ESL 1;
BA_ "NmNodeType" BU_ ESL 1;
BA_ "NmAsrCanMsgReducedTime" BU_ ESL 625;
BA_ "NmAsrNodeIdentifier" BU_ ESL 21;
BA_ "NmStationAddress" BU_ ESL 21;
BA_ "Description" BU_ ESL "Electric Steering Lock";
BA_ "NwmNodeType" BU_ ECM 1;
BA_ "NmNodeType" BU_ ECM 1;
BA_ "NmAsrCanMsgReducedTime" BU_ ECM 575;
BA_ "NmAsrNodeIdentifier" BU_ ECM 1;
BA_ "NmStationAddress" BU_ ECM 1;
BA_ "Description" BU_ ECM "Engine Control Module";
BA_ "NwmNodeType" BU_ DTCM 2;
BA_ "NmNodeType" BU_ DTCM 2;
BA_ "NmAsrCanMsgReducedTime" BU_ DTCM 550;
BA_ "NmAsrNodeIdentifier" BU_ DTCM 67;
BA_ "NmStationAddress" BU_ DTCM 67;
BA_ "Description" BU_ DTCM "Drive Train Control Module";
BA_ "NwmNodeType" BU_ DMSM 0;
BA_ "NmNodeType" BU_ DMSM 0;
BA_ "NmAsrNodeIdentifier" BU_ DMSM 153;
BA_ "NmAsrNode" BU_ DMSM 0;
BA_ "NmNode" BU_ DMSM 0;
BA_ "NmStationAddress" BU_ DMSM 153;
BA_ "Description" BU_ DMSM "Driver Monitoring System Module";
BA_ "NwmNodeType" BU_ BSM 1;
BA_ "NmNodeType" BU_ BSM 1;
BA_ "NmAsrCanMsgReducedTime" BU_ BSM 525;
BA_ "NmAsrNodeIdentifier" BU_ BSM 6;
BA_ "NmStationAddress" BU_ BSM 6;
BA_ "Description" BU_ BSM "Braking System Module";
BA_ "NwmNodeType" BU_ BCM 1;
BA_ "NmNodeType" BU_ BCM 1;
BA_ "NmAsrCanMsgReducedTime" BU_ BCM 500;
BA_ "Description" BU_ BCM "Body Control Module";
BA_ "NwmNodeType" BU_ AGSM 1;
BA_ "NmNodeType" BU_ AGSM 1;
BA_ "NmAsrCanMsgReducedTime" BU_ AGSM 700;
BA_ "NmAsrNodeIdentifier" BU_ AGSM 22;
BA_ "NmStationAddress" BU_ AGSM 22;
BA_ "Description" BU_ AGSM "Automatic Gearbox Shifter Module";
BA_ "NwmNodeType" BU_ ADCAM 1;
BA_ "NmNodeType" BU_ ADCAM 1;
BA_ "NmAsrCanMsgReducedTime" BU_ ADCAM 875;
BA_ "NmAsrNodeIdentifier" BU_ ADCAM 161;
BA_ "NmStationAddress" BU_ ADCAM 161;
BA_ "Description" BU_ ADCAM "ADas CAmera Module";
BA_ "CANFD_BRS" BO_ 2651930624 1;
BA_ "VFrameFormat" BO_ 2651930624 15;
BA_ "GenMsgDelayTime" BO_ 2651930624 10;
BA_ "GenMsgILSupport" BO_ 2651930624 1;
BA_ "Type" BO_ 2651930624 8;
BA_ "CANFD_BRS" BO_ 2651930630 1;
BA_ "VFrameFormat" BO_ 2651930630 15;
BA_ "GenMsgILSupport" BO_ 2651930630 1;
BA_ "Type" BO_ 2651930630 11;
BA_ "CANFD_BRS" BO_ 2651930625 1;
BA_ "VFrameFormat" BO_ 2651930625 15;
BA_ "GenMsgILSupport" BO_ 2651930625 1;
BA_ "Type" BO_ 2651930625 11;
BA_ "CANFD_BRS" BO_ 2651930689 1;
BA_ "VFrameFormat" BO_ 2651930689 15;
BA_ "GenMsgILSupport" BO_ 2651930689 1;
BA_ "Type" BO_ 2651930689 11;
BA_ "VFrameFormat" BO_ 2564440305 1;
BA_ "DiagConnection" BO_ 2564440305 61760;
BA_ "Type" BO_ 2564440305 8;
BA_ "DiagRequest" BO_ 2564440305 1;
BA_ "VFrameFormat" BO_ 2564434161 1;
BA_ "DiagConnection" BO_ 2564434161 61736;
BA_ "Type" BO_ 2564434161 8;
BA_ "DiagRequest" BO_ 2564434161 1;
BA_ "VFrameFormat" BO_ 2564428017 1;
BA_ "DiagConnection" BO_ 2564428017 61712;
BA_ "Type" BO_ 2564428017 8;
BA_ "DiagRequest" BO_ 2564428017 1;
BA_ "VFrameFormat" BO_ 2564554481 1;
BA_ "DiagConnection" BO_ 2564554481 61950;
BA_ "DiagState" BO_ 2564554481 1;
BA_ "Type" BO_ 2564554481 8;
BA_ "VFrameFormat" BO_ 2564502513 1;
BA_ "DiagConnection" BO_ 2564502513 61747;
BA_ "DiagState" BO_ 2564502513 1;
BA_ "Type" BO_ 2564502513 8;
BA_ "VFrameFormat" BO_ 2564448497 1;
BA_ "DiagConnection" BO_ 2564448497 61792;
BA_ "Type" BO_ 2564448497 8;
BA_ "DiagRequest" BO_ 2564448497 1;
BA_ "VFrameFormat" BO_ 2564474865 1;
BA_ "DiagConnection" BO_ 2564474865 61895;
BA_ "Type" BO_ 2564474865 8;
BA_ "DiagRequest" BO_ 2564474865 1;
BA_ "VFrameFormat" BO_ 2564485440 1;
BA_ "DiagConnection" BO_ 2564485440 61760;
BA_ "DiagResponse" BO_ 2564485440 1;
BA_ "Type" BO_ 2564485440 8;
BA_ "VFrameFormat" BO_ 2564485416 1;
BA_ "DiagConnection" BO_ 2564485416 61736;
BA_ "DiagResponse" BO_ 2564485416 1;
BA_ "Type" BO_ 2564485416 8;
BA_ "VFrameFormat" BO_ 2564485392 1;
BA_ "DiagConnection" BO_ 2564485392 61712;
BA_ "DiagResponse" BO_ 2564485392 1;
BA_ "Type" BO_ 2564485392 8;
BA_ "VFrameFormat" BO_ 2564485472 1;
BA_ "DiagConnection" BO_ 2564485472 61792;
BA_ "DiagResponse" BO_ 2564485472 1;
BA_ "Type" BO_ 2564485472 8;
BA_ "VFrameFormat" BO_ 2564485575 1;
BA_ "DiagConnection" BO_ 2564485575 61895;
BA_ "DiagResponse" BO_ 2564485575 1;
BA_ "Type" BO_ 2564485575 8;
BA_ "VFrameFormat" BO_ 2564485407 1;
BA_ "DiagConnection" BO_ 2564485407 61727;
BA_ "DiagResponse" BO_ 2564485407 1;
BA_ "Type" BO_ 2564485407 8;
BA_ "VFrameFormat" BO_ 2564485402 1;
BA_ "DiagConnection" BO_ 2564485402 61722;
BA_ "DiagResponse" BO_ 2564485402 1;
BA_ "Type" BO_ 2564485402 8;
BA_ "VFrameFormat" BO_ 2564431857 1;
BA_ "DiagConnection" BO_ 2564431857 61727;
BA_ "Type" BO_ 2564431857 8;
BA_ "DiagRequest" BO_ 2564431857 1;
BA_ "VFrameFormat" BO_ 2564474097 1;
BA_ "DiagConnection" BO_ 2564474097 61892;
BA_ "Type" BO_ 2564474097 8;
BA_ "DiagRequest" BO_ 2564474097 1;
BA_ "VFrameFormat" BO_ 2564430577 1;
BA_ "DiagConnection" BO_ 2564430577 61722;
BA_ "Type" BO_ 2564430577 8;
BA_ "DiagRequest" BO_ 2564430577 1;
BA_ "CANFD_BRS" BO_ 2651930627 1;
BA_ "VFrameFormat" BO_ 2651930627 15;
BA_ "GenMsgILSupport" BO_ 2651930627 1;
BA_ "Type" BO_ 2651930627 11;
BA_ "CANFD_BRS" BO_ 2651930691 1;
BA_ "VFrameFormat" BO_ 2651930691 15;
BA_ "GenMsgILSupport" BO_ 2651930691 1;
BA_ "Type" BO_ 2651930691 11;
BA_ "VFrameFormat" BO_ 2564485572 1;
BA_ "DiagConnection" BO_ 2564485572 61892;
BA_ "DiagResponse" BO_ 2564485572 1;
BA_ "Type" BO_ 2564485572 8;
BA_ "GenMsgILSupport" BO_ 2651930660 1;
BA_ "Type" BO_ 2651930660 11;
BA_ "CANFD_BRS" BO_ 2651930660 1;
BA_ "VFrameFormat" BO_ 2651930660 15;
BA_ "CANFD_BRS" BO_ 2651930645 1;
BA_ "VFrameFormat" BO_ 2651930645 15;
BA_ "GenMsgILSupport" BO_ 2651930645 1;
BA_ "Type" BO_ 2651930645 11;
BA_ "CANFD_BRS" BO_ 1053 1;
BA_ "GenMsgCycleTime" BO_ 1053 100;
BA_ "GenMsgStartDelayTime" BO_ 1053 95;
BA_ "GenMsgILSupport" BO_ 1053 1;
BA_ "GenMsgSendType" BO_ 1053 0;
BA_ "Type" BO_ 1053 1;
BA_ "CANFD_BRS" BO_ 254 1;
BA_ "GenMsgILSupport" BO_ 254 1;
BA_ "Type" BO_ 254 12;
BA_ "CANFD_BRS" BO_ 1059 1;
BA_ "GenMsgILSupport" BO_ 1059 1;
BA_ "Type" BO_ 1059 8;
BA_ "CANFD_BRS" BO_ 1450 1;
BA_ "GenMsgDelayTime" BO_ 1450 20;
BA_ "GenMsgCycleTime" BO_ 1450 1000;
BA_ "GenMsgCycleTimeFast" BO_ 1450 20;
BA_ "GenMsgILSupport" BO_ 1450 1;
BA_ "GenMsgNrOfRepetition" BO_ 1450 2;
BA_ "GenMsgSendType" BO_ 1450 0;
BA_ "Type" BO_ 1450 3;
BA_ "CANFD_BRS" BO_ 1428 1;
BA_ "GenMsgDelayTime" BO_ 1428 20;
BA_ "GenMsgCycleTime" BO_ 1428 1000;
BA_ "GenMsgCycleTimeFast" BO_ 1428 20;
BA_ "GenMsgILSupport" BO_ 1428 1;
BA_ "GenMsgNrOfRepetition" BO_ 1428 2;
BA_ "GenMsgSendType" BO_ 1428 0;
BA_ "Type" BO_ 1428 3;
BA_ "CANFD_BRS" BO_ 156 1;
BA_ "GenMsgILSupport" BO_ 156 1;
BA_ "Type" BO_ 156 8;
BA_ "CANFD_BRS" BO_ 1378 1;
BA_ "GenMsgCycleTime" BO_ 1378 250;
BA_ "GenMsgILSupport" BO_ 1378 1;
BA_ "GenMsgSendType" BO_ 1378 0;
BA_ "Type" BO_ 1378 1;
BA_ "CANFD_BRS" BO_ 1876 1;
BA_ "GenMsgDelayTime" BO_ 1876 20;
BA_ "GenMsgCycleTime" BO_ 1876 2000;
BA_ "GenMsgCycleTimeFast" BO_ 1876 20;
BA_ "GenMsgILSupport" BO_ 1876 1;
BA_ "GenMsgNrOfRepetition" BO_ 1876 2;
BA_ "GenMsgSendType" BO_ 1876 0;
BA_ "Type" BO_ 1876 3;
BA_ "Type" BO_ 1449 3;
BA_ "CANFD_BRS" BO_ 1449 1;
BA_ "GenMsgDelayTime" BO_ 1449 20;
BA_ "GenMsgCycleTime" BO_ 1449 1000;
BA_ "GenMsgCycleTimeFast" BO_ 1449 20;
BA_ "GenMsgILSupport" BO_ 1449 1;
BA_ "GenMsgNrOfRepetition" BO_ 1449 2;
BA_ "GenMsgSendType" BO_ 1449 0;
BA_ "CANFD_BRS" BO_ 519 1;
BA_ "GenMsgCycleTime" BO_ 519 20;
BA_ "GenMsgILSupport" BO_ 519 1;
BA_ "GenMsgSendType" BO_ 519 0;
BA_ "Type" BO_ 519 1;
BA_ "GenSigTimeoutTime_SGW" SG_ 2564485575 N_PDU 0;
BA_ "GenSigTimeoutTime_RFHM" SG_ 2564485575 N_PDU 0;
BA_ "GenSigTimeoutTime_MPAD" SG_ 2564485575 N_PDU 0;
BA_ "GenSigTimeoutTime_IPC" SG_ 2564485575 N_PDU 0;
BA_ "GenSigTimeoutTime_GNMM" SG_ 2564485575 N_PDU 0;
BA_ "GenSigTimeoutTime_EVCU2" SG_ 2564485575 N_PDU 0;
BA_ "GenSigTimeoutTime_ESL" SG_ 2564485575 N_PDU 0;
BA_ "GenSigTimeoutTime_ECM" SG_ 2564485575 N_PDU 0;
BA_ "GenSigTimeoutTime_DTCM" SG_ 2564485575 N_PDU 0;
BA_ "GenSigTimeoutTime_DMSM" SG_ 2564485575 N_PDU 0;
BA_ "GenSigTimeoutTime_BSM" SG_ 2564485575 N_PDU 0;
BA_ "GenSigTimeoutTime_BCM" SG_ 2564485575 N_PDU 0;
BA_ "GenSigTimeoutTime_AGSM" SG_ 2564485575 N_PDU 0;
BA_ "GenSigTimeoutTime_ADCAM" SG_ 2564485575 N_PDU 0;
BA_ "GenSigTimeoutTime_SGW" SG_ 2564485407 N_PDU 0;
BA_ "GenSigTimeoutTime_RFHM" SG_ 2564485407 N_PDU 0;
BA_ "GenSigTimeoutTime_MPAD" SG_ 2564485407 N_PDU 0;
BA_ "GenSigTimeoutTime_IPC" SG_ 2564485407 N_PDU 0;
BA_ "GenSigTimeoutTime_GNMM" SG_ 2564485407 N_PDU 0;
BA_ "GenSigTimeoutTime_EVCU2" SG_ 2564485407 N_PDU 0;
BA_ "GenSigTimeoutTime_ESL" SG_ 2564485407 N_PDU 0;
BA_ "GenSigTimeoutTime_ECM" SG_ 2564485407 N_PDU 0;
BA_ "GenSigTimeoutTime_DTCM" SG_ 2564485407 N_PDU 0;
BA_ "GenSigTimeoutTime_DMSM" SG_ 2564485407 N_PDU 0;
BA_ "GenSigTimeoutTime_BSM" SG_ 2564485407 N_PDU 0;
BA_ "GenSigTimeoutTime_BCM" SG_ 2564485407 N_PDU 0;
BA_ "GenSigTimeoutTime_AGSM" SG_ 2564485407 N_PDU 0;
BA_ "GenSigTimeoutTime_ADCAM" SG_ 2564485407 N_PDU 0;
BA_ "GenSigTimeoutTime_SGW" SG_ 2564485472 N_PDU 0;
BA_ "GenSigTimeoutTime_RFHM" SG_ 2564485472 N_PDU 0;
BA_ "GenSigTimeoutTime_MPAD" SG_ 2564485472 N_PDU 0;
BA_ "GenSigTimeoutTime_IPC" SG_ 2564485472 N_PDU 0;
BA_ "GenSigTimeoutTime_GNMM" SG_ 2564485472 N_PDU 0;
BA_ "GenSigTimeoutTime_EVCU2" SG_ 2564485472 N_PDU 0;
BA_ "GenSigTimeoutTime_ESL" SG_ 2564485472 N_PDU 0;
BA_ "GenSigTimeoutTime_ECM" SG_ 2564485472 N_PDU 0;
BA_ "GenSigTimeoutTime_DTCM" SG_ 2564485472 N_PDU 0;
BA_ "GenSigTimeoutTime_DMSM" SG_ 2564485472 N_PDU 0;
BA_ "GenSigTimeoutTime_BSM" SG_ 2564485472 N_PDU 0;
BA_ "GenSigTimeoutTime_BCM" SG_ 2564485472 N_PDU 0;
BA_ "GenSigTimeoutTime_AGSM" SG_ 2564485472 N_PDU 0;
BA_ "GenSigTimeoutTime_ADCAM" SG_ 2564485472 N_PDU 0;
BA_ "GenSigTimeoutTime_SGW" SG_ 2564485416 N_PDU 0;
BA_ "GenSigTimeoutTime_RFHM" SG_ 2564485416 N_PDU 0;
BA_ "GenSigTimeoutTime_MPAD" SG_ 2564485416 N_PDU 0;
BA_ "GenSigTimeoutTime_IPC" SG_ 2564485416 N_PDU 0;
BA_ "GenSigTimeoutTime_GNMM" SG_ 2564485416 N_PDU 0;
BA_ "GenSigTimeoutTime_EVCU2" SG_ 2564485416 N_PDU 0;
BA_ "GenSigTimeoutTime_ESL" SG_ 2564485416 N_PDU 0;
BA_ "GenSigTimeoutTime_ECM" SG_ 2564485416 N_PDU 0;
BA_ "GenSigTimeoutTime_DTCM" SG_ 2564485416 N_PDU 0;
BA_ "GenSigTimeoutTime_DMSM" SG_ 2564485416 N_PDU 0;
BA_ "GenSigTimeoutTime_BSM" SG_ 2564485416 N_PDU 0;
BA_ "GenSigTimeoutTime_BCM" SG_ 2564485416 N_PDU 0;
BA_ "GenSigTimeoutTime_AGSM" SG_ 2564485416 N_PDU 0;
BA_ "GenSigTimeoutTime_ADCAM" SG_ 2564485416 N_PDU 0;
BA_ "GenSigTimeoutTime_SGW" SG_ 2564485440 N_PDU 0;
BA_ "GenSigTimeoutTime_RFHM" SG_ 2564485440 N_PDU 0;
BA_ "GenSigTimeoutTime_MPAD" SG_ 2564485440 N_PDU 0;
BA_ "GenSigTimeoutTime_IPC" SG_ 2564485440 N_PDU 0;
BA_ "GenSigTimeoutTime_GNMM" SG_ 2564485440 N_PDU 0;
BA_ "GenSigTimeoutTime_EVCU2" SG_ 2564485440 N_PDU 0;
BA_ "GenSigTimeoutTime_ESL" SG_ 2564485440 N_PDU 0;
BA_ "GenSigTimeoutTime_ECM" SG_ 2564485440 N_PDU 0;
BA_ "GenSigTimeoutTime_DTCM" SG_ 2564485440 N_PDU 0;
BA_ "GenSigTimeoutTime_DMSM" SG_ 2564485440 N_PDU 0;
BA_ "GenSigTimeoutTime_BSM" SG_ 2564485440 N_PDU 0;
BA_ "GenSigTimeoutTime_BCM" SG_ 2564485440 N_PDU 0;
BA_ "GenSigTimeoutTime_AGSM" SG_ 2564485440 N_PDU 0;
BA_ "GenSigTimeoutTime_ADCAM" SG_ 2564485440 N_PDU 0;
BA_ "GenSigTimeoutTime_SGW" SG_ 2564554481 N_PDU 0;
BA_ "GenSigTimeoutTime_RFHM" SG_ 2564554481 N_PDU 0;
BA_ "GenSigTimeoutTime_MPAD" SG_ 2564554481 N_PDU 0;
BA_ "GenSigTimeoutTime_IPC" SG_ 2564554481 N_PDU 0;
BA_ "GenSigTimeoutTime_GNMM" SG_ 2564554481 N_PDU 0;
BA_ "GenSigTimeoutTime_EVCU2" SG_ 2564554481 N_PDU 0;
BA_ "GenSigTimeoutTime_ESL" SG_ 2564554481 N_PDU 0;
BA_ "GenSigTimeoutTime_ECM" SG_ 2564554481 N_PDU 0;
BA_ "GenSigTimeoutTime_DTCM" SG_ 2564554481 N_PDU 0;
BA_ "GenSigTimeoutTime_DMSM" SG_ 2564554481 N_PDU 0;
BA_ "GenSigTimeoutTime_BSM" SG_ 2564554481 N_PDU 0;
BA_ "GenSigTimeoutTime_BCM" SG_ 2564554481 N_PDU 0;
BA_ "GenSigTimeoutTime_AGSM" SG_ 2564554481 N_PDU 0;
BA_ "GenSigTimeoutTime_ADCAM" SG_ 2564554481 N_PDU 0;
BA_ "GenSigTimeoutTime_SGW" SG_ 2564502513 N_PDU 0;
BA_ "GenSigTimeoutTime_RFHM" SG_ 2564502513 N_PDU 0;
BA_ "GenSigTimeoutTime_MPAD" SG_ 2564502513 N_PDU 0;
BA_ "GenSigTimeoutTime_IPC" SG_ 2564502513 N_PDU 0;
BA_ "GenSigTimeoutTime_GNMM" SG_ 2564502513 N_PDU 0;
BA_ "GenSigTimeoutTime_EVCU2" SG_ 2564502513 N_PDU 0;
BA_ "GenSigTimeoutTime_ESL" SG_ 2564502513 N_PDU 0;
BA_ "GenSigTimeoutTime_ECM" SG_ 2564502513 N_PDU 0;
BA_ "GenSigTimeoutTime_DTCM" SG_ 2564502513 N_PDU 0;
BA_ "GenSigTimeoutTime_DMSM" SG_ 2564502513 N_PDU 0;
BA_ "GenSigTimeoutTime_BSM" SG_ 2564502513 N_PDU 0;
BA_ "GenSigTimeoutTime_BCM" SG_ 2564502513 N_PDU 0;
BA_ "GenSigTimeoutTime_AGSM" SG_ 2564502513 N_PDU 0;
BA_ "GenSigTimeoutTime_ADCAM" SG_ 2564502513 N_PDU 0;
BA_ "GenSigTimeoutTime_SGW" SG_ 2564431857 N_PDU 0;
BA_ "GenSigTimeoutTime_RFHM" SG_ 2564431857 N_PDU 0;
BA_ "GenSigTimeoutTime_MPAD" SG_ 2564431857 N_PDU 0;
BA_ "GenSigTimeoutTime_IPC" SG_ 2564431857 N_PDU 0;
BA_ "GenSigTimeoutTime_GNMM" SG_ 2564431857 N_PDU 0;
BA_ "GenSigTimeoutTime_EVCU2" SG_ 2564431857 N_PDU 0;
BA_ "GenSigTimeoutTime_ESL" SG_ 2564431857 N_PDU 0;
BA_ "GenSigTimeoutTime_ECM" SG_ 2564431857 N_PDU 0;
BA_ "GenSigTimeoutTime_DTCM" SG_ 2564431857 N_PDU 0;
BA_ "GenSigTimeoutTime_DMSM" SG_ 2564431857 N_PDU 0;
BA_ "GenSigTimeoutTime_BSM" SG_ 2564431857 N_PDU 0;
BA_ "GenSigTimeoutTime_BCM" SG_ 2564431857 N_PDU 0;
BA_ "GenSigTimeoutTime_AGSM" SG_ 2564431857 N_PDU 0;
BA_ "GenSigTimeoutTime_ADCAM" SG_ 2564431857 N_PDU 0;
BA_ "GenSigTimeoutTime_SGW" SG_ 2564474865 N_PDU 0;
BA_ "GenSigTimeoutTime_RFHM" SG_ 2564474865 N_PDU 0;
BA_ "GenSigTimeoutTime_MPAD" SG_ 2564474865 N_PDU 0;
BA_ "GenSigTimeoutTime_IPC" SG_ 2564474865 N_PDU 0;
BA_ "GenSigTimeoutTime_GNMM" SG_ 2564474865 N_PDU 0;
BA_ "GenSigTimeoutTime_EVCU2" SG_ 2564474865 N_PDU 0;
BA_ "GenSigTimeoutTime_ESL" SG_ 2564474865 N_PDU 0;
BA_ "GenSigTimeoutTime_ECM" SG_ 2564474865 N_PDU 0;
BA_ "GenSigTimeoutTime_DTCM" SG_ 2564474865 N_PDU 0;
BA_ "GenSigTimeoutTime_DMSM" SG_ 2564474865 N_PDU 0;
BA_ "GenSigTimeoutTime_BSM" SG_ 2564474865 N_PDU 0;
BA_ "GenSigTimeoutTime_BCM" SG_ 2564474865 N_PDU 0;
BA_ "GenSigTimeoutTime_AGSM" SG_ 2564474865 N_PDU 0;
BA_ "GenSigTimeoutTime_ADCAM" SG_ 2564474865 N_PDU 0;
BA_ "GenSigTimeoutTime_SGW" SG_ 2564448497 N_PDU 0;
BA_ "GenSigTimeoutTime_RFHM" SG_ 2564448497 N_PDU 0;
BA_ "GenSigTimeoutTime_MPAD" SG_ 2564448497 N_PDU 0;
BA_ "GenSigTimeoutTime_IPC" SG_ 2564448497 N_PDU 0;
BA_ "GenSigTimeoutTime_GNMM" SG_ 2564448497 N_PDU 0;
BA_ "GenSigTimeoutTime_EVCU2" SG_ 2564448497 N_PDU 0;
BA_ "GenSigTimeoutTime_ESL" SG_ 2564448497 N_PDU 0;
BA_ "GenSigTimeoutTime_ECM" SG_ 2564448497 N_PDU 0;
BA_ "GenSigTimeoutTime_DTCM" SG_ 2564448497 N_PDU 0;
BA_ "GenSigTimeoutTime_DMSM" SG_ 2564448497 N_PDU 0;
BA_ "GenSigTimeoutTime_BSM" SG_ 2564448497 N_PDU 0;
BA_ "GenSigTimeoutTime_BCM" SG_ 2564448497 N_PDU 0;
BA_ "GenSigTimeoutTime_AGSM" SG_ 2564448497 N_PDU 0;
BA_ "GenSigTimeoutTime_ADCAM" SG_ 2564448497 N_PDU 0;
BA_ "GenSigTimeoutTime_GNMM" SG_ 2651930689 Digit_01_RFHM 0;
BA_ "GenSigTimeoutTime_EVCU2" SG_ 2651930689 Digit_01_RFHM 0;
BA_ "GenSigTimeoutTime_ESL" SG_ 2651930689 Digit_01_RFHM 0;
BA_ "GenSigTimeoutTime_ECM" SG_ 2651930689 Digit_01_RFHM 0;
BA_ "GenSigTimeoutTime_DTCM" SG_ 2651930689 Digit_01_RFHM 0;
BA_ "GenSigTimeoutTime_DMSM" SG_ 2651930689 Digit_01_RFHM 0;
BA_ "GenSigTimeoutTime_BSM" SG_ 2651930689 Digit_01_RFHM 0;
BA_ "GenSigTimeoutTime_AGSM" SG_ 2651930689 Digit_01_RFHM 0;
BA_ "GenSigTimeoutTime_ADCAM" SG_ 2651930689 Digit_01_RFHM 0;
BA_ "GenSigSendType" SG_ 2651930689 Digit_01_RFHM 1;
BA_ "GenSigTimeoutTime_SGW" SG_ 2651930691 Digit_01_DTCM 0;
BA_ "GenSigTimeoutTime_RFHM" SG_ 2651930691 Digit_01_DTCM 0;
BA_ "GenSigTimeoutTime_MPAD" SG_ 2651930691 Digit_01_DTCM 0;
BA_ "GenSigTimeoutTime_IPC" SG_ 2651930691 Digit_01_DTCM 0;
BA_ "GenSigTimeoutTime_GNMM" SG_ 2651930691 Digit_01_DTCM 0;
BA_ "GenSigTimeoutTime_EVCU2" SG_ 2651930691 Digit_01_DTCM 0;
BA_ "GenSigTimeoutTime_ESL" SG_ 2651930691 Digit_01_DTCM 0;
BA_ "GenSigTimeoutTime_ECM" SG_ 2651930691 Digit_01_DTCM 0;
BA_ "GenSigTimeoutTime_DTCM" SG_ 2651930691 Digit_01_DTCM 0;
BA_ "GenSigTimeoutTime_DMSM" SG_ 2651930691 Digit_01_DTCM 0;
BA_ "GenSigTimeoutTime_BSM" SG_ 2651930691 Digit_01_DTCM 0;
BA_ "GenSigTimeoutTime_AGSM" SG_ 2651930691 Digit_01_DTCM 0;
BA_ "GenSigTimeoutTime_ADCAM" SG_ 2651930691 Digit_01_DTCM 0;
BA_ "GenSigSendType" SG_ 2651930691 Digit_01_DTCM 1;
BA_ "GenSigTimeoutTime_SGW" SG_ 2651930691 Digit_02_DTCM 0;
BA_ "GenSigTimeoutTime_RFHM" SG_ 2651930691 Digit_02_DTCM 0;
BA_ "GenSigTimeoutTime_MPAD" SG_ 2651930691 Digit_02_DTCM 0;
BA_ "GenSigTimeoutTime_IPC" SG_ 2651930691 Digit_02_DTCM 0;
BA_ "GenSigTimeoutTime_GNMM" SG_ 2651930691 Digit_02_DTCM 0;
BA_ "GenSigTimeoutTime_EVCU2" SG_ 2651930691 Digit_02_DTCM 0;
BA_ "GenSigTimeoutTime_ESL" SG_ 2651930691 Digit_02_DTCM 0;
BA_ "GenSigTimeoutTime_ECM" SG_ 2651930691 Digit_02_DTCM 0;
BA_ "GenSigTimeoutTime_DTCM" SG_ 2651930691 Digit_02_DTCM 0;
BA_ "GenSigTimeoutTime_DMSM" SG_ 2651930691 Digit_02_DTCM 0;
BA_ "GenSigTimeoutTime_BSM" SG_ 2651930691 Digit_02_DTCM 0;
BA_ "GenSigTimeoutTime_AGSM" SG_ 2651930691 Digit_02_DTCM 0;
BA_ "GenSigTimeoutTime_ADCAM" SG_ 2651930691 Digit_02_DTCM 0;
BA_ "GenSigTimeoutTime_SGW" SG_ 2651930691 Digit_03_DTCM 0;
BA_ "GenSigTimeoutTime_RFHM" SG_ 2651930691 Digit_03_DTCM 0;
BA_ "GenSigTimeoutTime_MPAD" SG_ 2651930691 Digit_03_DTCM 0;
BA_ "GenSigTimeoutTime_IPC" SG_ 2651930691 Digit_03_DTCM 0;
BA_ "GenSigTimeoutTime_GNMM" SG_ 2651930691 Digit_03_DTCM 0;
BA_ "GenSigTimeoutTime_EVCU2" SG_ 2651930691 Digit_03_DTCM 0;
BA_ "GenSigTimeoutTime_ESL" SG_ 2651930691 Digit_03_DTCM 0;
BA_ "GenSigTimeoutTime_SGW" SG_ 156 Month2_TLM 0;
BA_ "GenSigTimeoutTime_MPAD" SG_ 156 Month2_TLM 0;
BA_ "GenSigTimeoutTime_IPC" SG_ 156 Month2_TLM 0;
BA_ "GenSigTimeoutTime_GNMM" SG_ 156 Month2_TLM 0;
BA_ "GenSigTimeoutTime_ESL" SG_ 156 Month2_TLM 0;
BA_ "GenSigTimeoutTime_ECM" SG_ 156 Month2_TLM 0;
BA_ "GenSigTimeoutTime_DTCM" SG_ 156 Month2_TLM 0;
BA_ "GenSigTimeoutTime_DMSM" SG_ 156 Month2_TLM 0;
BA_ "GenSigTimeoutTime_BSM" SG_ 156 Month2_TLM 0;
BA_ "GenSigTimeoutTime_BCM" SG_ 156 Month2_TLM 0;
BA_ "GenSigTimeoutTime_AGSM" SG_ 156 Month2_TLM 0;
BA_ "GenSigTimeoutTime_ADCAM" SG_ 156 Month2_TLM 0;
BA_ "GenSigTimeoutTime_SGW" SG_ 156 Hour1_TLM 0;
BA_ "GenSigTimeoutTime_MPAD" SG_ 156 Hour1_TLM 0;
BA_ "GenSigTimeoutTime_GNMM" SG_ 156 Hour1_TLM 0;
BA_ "GenSigTimeoutTime_ESL" SG_ 1876 TyrePressureSysProgrammedSts 0;
BA_ "GenSigTimeoutTime_SGW" SG_ 1449 RFMemRq 0;
BA_ "GenSigTimeoutTime_RFHM" SG_ 1449 RFMemRq 0;
BA_ "GenSigTimeoutTime_MPAD" SG_ 1449 RFMemRq 0;
BA_ "GenSigTimeoutTime_IPC" SG_ 1449 RFMemRq 0;
BA_ "GenSigTimeoutTime_GNMM" SG_ 1449 RFMemRq 0;
BA_ "GenSigTimeoutTime_EVCU2" SG_ 1449 RFMemRq 0;
BA_ "GenSigTimeoutTime_ESL" SG_ 1449 RFMemRq 0;
BA_ "GenSigTimeoutTime_ECM" SG_ 1449 RFMemRq 0;
BA_ "GenSigTimeoutTime_DTCM" SG_ 1449 RFMemRq 0;
BA_ "GenSigTimeoutTime_DMSM" SG_ 1449 RFMemRq 0;
BA_ "GenSigTimeoutTime_BSM" SG_ 1449 RFMemRq 0;
BA_ "GenSigTimeoutTime_AGSM" SG_ 1449 RFMemRq 0;
BA_ "GenSigTimeoutTime_ADCAM" SG_ 1449 RFMemRq 0;
BA_ "GenSigSendType" SG_ 1449 RFMemRq 3;
BA_ "GenSigTimeoutTime_ECM" SG_ 1876 TyrePressureSysProgrammedSts 0;
BA_ "GenSigTimeoutTime_DTCM" SG_ 1876 TyrePressureSysProgrammedSts 0;
BA_ "GenSigTimeoutTime_DMSM" SG_ 1876 TyrePressureSysProgrammedSts 0;
BA_ "GenSigTimeoutTime_BSM" SG_ 1876 TyrePressureSysProgrammedSts 0;
BA_ "GenSigTimeoutTime_BCM" SG_ 1876 TyrePressureSysProgrammedSts 0;
BA_ "GenSigTimeoutTime_AGSM" SG_ 1876 TyrePressureSysProgrammedSts 0;
BA_ "GenSigTimeoutTime_ADCAM" SG_ 1876 TyrePressureSysProgrammedSts 0;
BA_ "GenSigSendType" SG_ 1876 TyrePressureSysProgrammedSts 4;
BA_ "GenSigTimeoutTime_SGW" SG_ 1876 TPMActivitySts 0;
BA_ "GenSigTimeoutTime_RFHM" SG_ 1876 TPMActivitySts 0;
BA_ "GenSigTimeoutTime_MPAD" SG_ 1876 TPMActivitySts 0;
BA_ "GenSigTimeoutTime_GNMM" SG_ 1876 TPMActivitySts 0;
BA_ "GenSigTimeoutTime_EVCU2" SG_ 1876 TPMActivitySts 0;
BA_ "GenSigTimeoutTime_ESL" SG_ 1876 TPMActivitySts 0;
BA_ "GenSigTimeoutTime_ECM" SG_ 1876 TPMActivitySts 0;
BA_ "GenSigTimeoutTime_DTCM" SG_ 1876 TPMActivitySts 0;
BA_ "GenSigTimeoutTime_DMSM" SG_ 1876 TPMActivitySts 0;
BA_ "GenSigTimeoutTime_BSM" SG_ 1876 TPMActivitySts 0;
BA_ "GenSigTimeoutTime_AGSM" SG_ 1876 TPMActivitySts 0;
BA_ "GenSigTimeoutTime_ADCAM" SG_ 1876 TPMActivitySts 0;
BA_ "GenSigTimeoutTime_RFHM" SG_ 1876 InflationState_LHF_Tyre 0;
BA_ "GenSigTimeoutTime_GNMM" SG_ 1876 InflationState_LHF_Tyre 0;
BA_ "GenSigTimeoutTime_EVCU2" SG_ 1876 InflationState_LHF_Tyre 0;
BA_ "GenSigTimeoutTime_ESL" SG_ 1876 InflationState_LHF_Tyre 0;
BA_ "GenSigTimeoutTime_ECM" SG_ 1876 InflationState_LHF_Tyre 0;
BA_ "GenSigTimeoutTime_DTCM" SG_ 1876 InflationState_LHF_Tyre 0;
BA_ "GenSigTimeoutTime_DMSM" SG_ 1876 InflationState_LHF_Tyre 0;
BA_ "GenSigTimeoutTime_BSM" SG_ 1876 InflationState_LHF_Tyre 0;
BA_ "GenSigTimeoutTime_AGSM" SG_ 1876 InflationState_LHF_Tyre 0;
BA_ "GenSigTimeoutTime_ADCAM" SG_ 1876 InflationState_LHF_Tyre 0;
BA_ "GenSigSendType" SG_ 1876 InflationState_LHF_Tyre 4;
BA_ "GenSigTimeoutTime_RFHM" SG_ 1876 InflationState_LHR_Tyre 0;
BA_ "GenSigTimeoutTime_GNMM" SG_ 1876 InflationState_LHR_Tyre 0;
BA_ "GenSigTimeoutTime_EVCU2" SG_ 1876 InflationState_LHR_Tyre 0;
BA_ "GenSigTimeoutTime_ESL" SG_ 1876 InflationState_LHR_Tyre 0;
BA_ "GenSigTimeoutTime_ECM" SG_ 1876 InflationState_LHR_Tyre 0;
BA_ "GenSigTimeoutTime_DTCM" SG_ 1876 InflationState_LHR_Tyre 0;
BA_ "GenSigTimeoutTime_DMSM" SG_ 1876 InflationState_LHR_Tyre 0;
BA_ "GenSigTimeoutTime_BSM" SG_ 1876 InflationState_LHR_Tyre 0;
BA_ "GenSigTimeoutTime_AGSM" SG_ 1876 InflationState_LHR_Tyre 0;
BA_ "GenSigTimeoutTime_ADCAM" SG_ 1876 InflationState_LHR_Tyre 0;
BA_ "GenSigSendType" SG_ 1876 InflationState_LHR_Tyre 4;
BA_ "GenSigTimeoutTime_RFHM" SG_ 1876 InflationState_RHF_Tyre 0;
BA_ "GenSigTimeoutTime_GNMM" SG_ 1876 InflationState_RHF_Tyre 0;
BA_ "GenSigTimeoutTime_EVCU2" SG_ 1876 InflationState_RHF_Tyre 0;
BA_ "GenSigTimeoutTime_ESL" SG_ 1876 InflationState_RHF_Tyre 0;
BA_ "GenSigTimeoutTime_ECM" SG_ 1876 InflationState_RHF_Tyre 0;
BA_ "GenSigTimeoutTime_DTCM" SG_ 1876 InflationState_RHF_Tyre 0;
BA_ "GenSigTimeoutTime_DMSM" SG_ 1876 InflationState_RHF_Tyre 0;
BA_ "GenSigTimeoutTime_BSM" SG_ 1876 InflationState_RHF_Tyre 0;
BA_ "GenSigTimeoutTime_AGSM" SG_ 1876 InflationState_RHF_Tyre 0;
BA_ "GenSigTimeoutTime_ADCAM" SG_ 1876 InflationState_RHF_Tyre 0;
BA_ "GenSigSendType" SG_ 1876 InflationState_RHF_Tyre 4;
BA_ "GenSigTimeoutTime_RFHM" SG_ 1876 InflationState_RHR_Tyre 0;
BA_ "GenSigTimeoutTime_GNMM" SG_ 1876 InflationState_RHR_Tyre 0;
BA_ "GenSigTimeoutTime_EVCU2" SG_ 1876 InflationState_RHR_Tyre 0;
BA_ "GenSigTimeoutTime_ESL" SG_ 1876 InflationState_RHR_Tyre 0;
BA_ "GenSigTimeoutTime_ECM" SG_ 1876 InflationState_RHR_Tyre 0;
BA_ "GenSigTimeoutTime_DTCM" SG_ 1876 InflationState_RHR_Tyre 0;
BA_ "GenSigTimeoutTime_DMSM" SG_ 1876 InflationState_RHR_Tyre 0;
BA_ "GenSigTimeoutTime_BSM" SG_ 1876 InflationState_RHR_Tyre 0;
BA_ "GenSigTimeoutTime_AGSM" SG_ 1876 InflationState_RHR_Tyre 0;
BA_ "GenSigTimeoutTime_ADCAM" SG_ 1876 InflationState_RHR_Tyre 0;
BA_ "GenSigSendType" SG_ 1876 InflationState_RHR_Tyre 4;
BA_ "GenSigTimeoutTime_DTCM" SG_ 1449 MsgNotInPark 0;
BA_ "GenSigTimeoutTime_DMSM" SG_ 1449 MsgNotInPark 0;
BA_ "GenSigTimeoutTime_BSM" SG_ 1449 MsgNotInPark 0;
BA_ "GenSigTimeoutTime_BCM" SG_ 1449 MsgNotInPark 0;
BA_ "GenSigTimeoutTime_AGSM" SG_ 1449 MsgNotInPark 0;
BA_ "GenSigTimeoutTime_ADCAM" SG_ 1449 MsgNotInPark 0;
BA_ "GenSigSendType" SG_ 1449 MsgNotInPark 3;
BA_ "GenSigTimeoutTime_SGW" SG_ 1449 MsgNotInPark 0;
BA_ "GenSigTimeoutTime_RFHM" SG_ 1449 MsgNotInPark 0;
BA_ "GenSigTimeoutTime_MPAD" SG_ 1449 MsgNotInPark 0;
BA_ "GenSigTimeoutTime_GNMM" SG_ 1449 MsgNotInPark 0;
BA_ "GenSigTimeoutTime_EVCU2" SG_ 1449 MsgNotInPark 0;
BA_ "GenSigTimeoutTime_ESL" SG_ 1449 MsgNotInPark 0;
BA_ "GenSigTimeoutTime_ECM" SG_ 1449 MsgNotInPark 0;
BA_ "GenSigTimeoutTime_SGW" SG_ 1449 MsgFOBNotFnd 0;
BA_ "GenSigTimeoutTime_RFHM" SG_ 1449 MsgFOBNotFnd 0;
BA_ "GenSigTimeoutTime_MPAD" SG_ 1449 MsgFOBNotFnd 0;
BA_ "GenSigTimeoutTime_GNMM" SG_ 1449 MsgFOBNotFnd 0;
BA_ "GenSigTimeoutTime_EVCU2" SG_ 1449 MsgFOBNotFnd 0;
BA_ "GenSigTimeoutTime_ESL" SG_ 1449 MsgFOBNotFnd 0;
BA_ "GenSigTimeoutTime_ECM" SG_ 1449 MsgFOBNotFnd 0;
BA_ "GenSigTimeoutTime_DTCM" SG_ 1449 MsgFOBNotFnd 0;
BA_ "GenSigTimeoutTime_DMSM" SG_ 1449 MsgFOBNotFnd 0;
BA_ "GenSigTimeoutTime_BSM" SG_ 1449 MsgFOBNotFnd 0;
BA_ "GenSigTimeoutTime_BCM" SG_ 1449 MsgFOBNotFnd 0;
BA_ "GenSigTimeoutTime_AGSM" SG_ 1449 MsgFOBNotFnd 0;
BA_ "GenSigTimeoutTime_ADCAM" SG_ 1449 MsgFOBNotFnd 0;
BA_ "GenSigSendType" SG_ 1449 MsgFOBNotFnd 3;
BA_ "GenSigTimeoutTime_SGW" SG_ 519 KeyAuth_Status 0;
BA_ "GenSigTimeoutTime_RFHM" SG_ 519 KeyAuth_Status 0;
BA_ "GenSigTimeoutTime_MPAD" SG_ 519 KeyAuth_Status 0;
BA_ "GenSigTimeoutTime_GNMM" SG_ 519 KeyAuth_Status 0;
BA_ "GenSigTimeoutTime_EVCU2" SG_ 519 KeyAuth_Status 0;
BA_ "GenSigTimeoutTime_ESL" SG_ 519 KeyAuth_Status 0;
BA_ "GenSigTimeoutTime_ECM" SG_ 519 KeyAuth_Status 0;
BA_ "GenSigTimeoutTime_DTCM" SG_ 519 KeyAuth_Status 0;
BA_ "GenSigTimeoutTime_DMSM" SG_ 519 KeyAuth_Status 0;
BA_ "GenSigTimeoutTime_BSM" SG_ 519 KeyAuth_Status 0;
BA_ "GenSigTimeoutTime_BCM" SG_ 519 KeyAuth_Status 0;
BA_ "GenSigTimeoutTime_AGSM" SG_ 519 KeyAuth_Status 0;
BA_ "GenSigTimeoutTime_ADCAM" SG_ 519 KeyAuth_Status 0;
BA_ "GenSigTimeoutTime_RFHM" SG_ 519 RFFobNum3 0;
BA_ "GenSigTimeoutTime_MPAD" SG_ 519 RFFobNum3 0;
BA_ "GenSigTimeoutTime_IPC" SG_ 519 RFFobNum3 0;
BA_ "GenSigTimeoutTime_GNMM" SG_ 519 RFFobNum3 0;
BA_ "GenSigTimeoutTime_EVCU2" SG_ 519 RFFobNum3 0;
BA_ "GenSigTimeoutTime_ESL" SG_ 519 RFFobNum3 0;
BA_ "GenSigTimeoutTime_ECM" SG_ 519 RFFobNum3 0;
BA_ "GenSigTimeoutTime_DTCM" SG_ 519 RFFobNum3 0;
BA_ "GenSigTimeoutTime_DMSM" SG_ 519 RFFobNum3 0;
BA_ "GenSigTimeoutTime_BSM" SG_ 519 RFFobNum3 0;
BA_ "GenSigTimeoutTime_AGSM" SG_ 519 RFFobNum3 0;
BA_ "GenSigTimeoutTime_ADCAM" SG_ 519 RFFobNum3 0;
BA_ "GenSigTimeoutTime_RFHM" SG_ 519 ValetMode_SPAAK 0;
BA_ "GenSigTimeoutTime_MPAD" SG_ 519 ValetMode_SPAAK 0;
BA_ "GenSigTimeoutTime_IPC" SG_ 519 ValetMode_SPAAK 0;
BA_ "GenSigTimeoutTime_GNMM" SG_ 519 ValetMode_SPAAK 0;
BA_ "GenSigTimeoutTime_EVCU2" SG_ 519 ValetMode_SPAAK 0;
BA_ "GenSigTimeoutTime_ESL" SG_ 519 ValetMode_SPAAK 0;
BA_ "GenSigTimeoutTime_ECM" SG_ 519 ValetMode_SPAAK 0;
BA_ "GenSigTimeoutTime_DTCM" SG_ 519 ValetMode_SPAAK 0;
BA_ "GenSigTimeoutTime_DMSM" SG_ 519 ValetMode_SPAAK 0;
BA_ "GenSigTimeoutTime_BSM" SG_ 519 ValetMode_SPAAK 0;
BA_ "GenSigTimeoutTime_BCM" SG_ 519 ValetMode_SPAAK 0;
BA_ "GenSigTimeoutTime_AGSM" SG_ 519 ValetMode_SPAAK 0;
BA_ "GenSigTimeoutTime_ADCAM" SG_ 519 ValetMode_SPAAK 0;
BA_ "GenSigTimeoutTime_SGW" SG_ 1449 MemRq_FobNum3 0;
BA_ "GenSigTimeoutTime_RFHM" SG_ 1449 MemRq_FobNum3 0;
BA_ "GenSigTimeoutTime_MPAD" SG_ 1449 MemRq_FobNum3 0;
BA_ "GenSigTimeoutTime_IPC" SG_ 1449 MemRq_FobNum3 0;
BA_ "GenSigTimeoutTime_GNMM" SG_ 1449 MemRq_FobNum3 0;
BA_ "GenSigTimeoutTime_EVCU2" SG_ 1449 MemRq_FobNum3 0;
BA_ "GenSigTimeoutTime_ESL" SG_ 1449 MemRq_FobNum3 0;
BA_ "GenSigTimeoutTime_ECM" SG_ 1449 MemRq_FobNum3 0;
BA_ "GenSigTimeoutTime_DTCM" SG_ 1449 MemRq_FobNum3 0;
BA_ "GenSigTimeoutTime_DMSM" SG_ 1449 MemRq_FobNum3 0;
BA_ "GenSigTimeoutTime_BSM" SG_ 1449 MemRq_FobNum3 0;
BA_ "GenSigTimeoutTime_AGSM" SG_ 1449 MemRq_FobNum3 0;
BA_ "GenSigTimeoutTime_ADCAM" SG_ 1449 MemRq_FobNum3 0;
BA_ "GenSigSendType" SG_ 1449 MemRq_FobNum3 3;
BA_ "GenSigTimeoutTime_SGW" SG_ 1449 KeyFob_Present 0;
BA_ "GenSigTimeoutTime_RFHM" SG_ 1449 KeyFob_Present 0;
BA_ "GenSigTimeoutTime_MPAD" SG_ 1449 KeyFob_Present 0;
BA_ "GenSigTimeoutTime_IPC" SG_ 1449 KeyFob_Present 0;
BA_ "GenSigTimeoutTime_GNMM" SG_ 1449 KeyFob_Present 0;
BA_ "GenSigTimeoutTime_EVCU2" SG_ 1449 KeyFob_Present 0;
BA_ "GenSigTimeoutTime_ESL" SG_ 1449 KeyFob_Present 0;
BA_ "GenSigTimeoutTime_ECM" SG_ 1449 KeyFob_Present 0;
BA_ "GenSigTimeoutTime_DTCM" SG_ 1449 KeyFob_Present 0;
BA_ "GenSigTimeoutTime_DMSM" SG_ 1449 KeyFob_Present 0;
BA_ "GenSigTimeoutTime_BSM" SG_ 1449 KeyFob_Present 0;
BA_ "GenSigTimeoutTime_AGSM" SG_ 1449 KeyFob_Present 0;
BA_ "GenSigTimeoutTime_ADCAM" SG_ 1449 KeyFob_Present 0;
BA_ "GenSigSendType" SG_ 1449 KeyFob_Present 3;
BA_ "GenSigTimeoutTime_SGW" SG_ 1449 FtTrPlacardPress 0;
BA_ "GenSigTimeoutTime_RFHM" SG_ 1449 FtTrPlacardPress 0;
BA_ "GenSigTimeoutTime_MPAD" SG_ 1449 FtTrPlacardPress 0;
BA_ "GenSigTimeoutTime_GNMM" SG_ 1449 FtTrPlacardPress 0;
BA_ "GenSigTimeoutTime_EVCU2" SG_ 1449 FtTrPlacardPress 0;
BA_ "GenSigTimeoutTime_ESL" SG_ 1449 FtTrPlacardPress 0;
BA_ "GenSigTimeoutTime_ECM" SG_ 1449 FtTrPlacardPress 0;
BA_ "GenSigTimeoutTime_DTCM" SG_ 1449 FtTrPlacardPress 0;
BA_ "GenSigTimeoutTime_DMSM" SG_ 1449 FtTrPlacardPress 0;
BA_ "GenSigTimeoutTime_BSM" SG_ 1449 FtTrPlacardPress 0;
BA_ "GenSigTimeoutTime_AGSM" SG_ 1449 FtTrPlacardPress 0;
BA_ "GenSigTimeoutTime_ADCAM" SG_ 1449 FtTrPlacardPress 0;
BA_ "GenSigSendType" SG_ 1449 FtTrPlacardPress 3;
BA_ "GenSigTimeoutTime_RFHM" SG_ 519 RFFuncReq 0;
BA_ "GenSigTimeoutTime_MPAD" SG_ 519 RFFuncReq 0;
BA_ "GenSigTimeoutTime_GNMM" SG_ 519 RFFuncReq 0;
BA_ "GenSigTimeoutTime_EVCU2" SG_ 519 RFFuncReq 0;
BA_ "GenSigTimeoutTime_ESL" SG_ 519 RFFuncReq 0;
BA_ "GenSigTimeoutTime_ECM" SG_ 519 RFFuncReq 0;
BA_ "GenSigTimeoutTime_DTCM" SG_ 519 RFFuncReq 0;
BA_ "GenSigTimeoutTime_DMSM" SG_ 519 RFFuncReq 0;
BA_ "GenSigTimeoutTime_BSM" SG_ 519 RFFuncReq 0;
BA_ "GenSigTimeoutTime_AGSM" SG_ 519 RFFuncReq 0;
BA_ "GenSigTimeoutTime_ADCAM" SG_ 519 RFFuncReq 0;
BA_ "GenSigSendType" SG_ 156 TSI_Offset_Kph_Req 1;
BA_ "GenSigTimeoutTime_MPAD" SG_ 1449 MsgFOBLeftVeh 0;
BA_ "GenSigTimeoutTime_GNMM" SG_ 1449 MsgFOBLeftVeh 0;
BA_ "GenSigTimeoutTime_EVCU2" SG_ 1449 MsgFOBLeftVeh 0;
BA_ "GenSigTimeoutTime_SGW" SG_ 2564430577 N_PDU 0;
BA_ "GenSigTimeoutTime_RFHM" SG_ 2564430577 N_PDU 0;
BA_ "GenSigTimeoutTime_MPAD" SG_ 2564430577 N_PDU 0;
BA_ "GenSigTimeoutTime_IPC" SG_ 2564430577 N_PDU 0;
BA_ "GenSigTimeoutTime_GNMM" SG_ 2564430577 N_PDU 0;
BA_ "GenSigTimeoutTime_EVCU2" SG_ 2564430577 N_PDU 0;
BA_ "GenSigTimeoutTime_ESL" SG_ 2564430577 N_PDU 0;
BA_ "GenSigTimeoutTime_ECM" SG_ 2564430577 N_PDU 0;
BA_ "GenSigTimeoutTime_DTCM" SG_ 2564430577 N_PDU 0;
BA_ "GenSigTimeoutTime_DMSM" SG_ 2564430577 N_PDU 0;
BA_ "GenSigTimeoutTime_BSM" SG_ 2564430577 N_PDU 0;
BA_ "GenSigTimeoutTime_BCM" SG_ 2564430577 N_PDU 0;
BA_ "GenSigTimeoutTime_AGSM" SG_ 2564430577 N_PDU 0;
BA_ "GenSigTimeoutTime_ADCAM" SG_ 2564430577 N_PDU 0;
BA_ "GenSigTimeoutTime_SGW" SG_ 2564434161 N_PDU 0;
BA_ "GenSigTimeoutTime_RFHM" SG_ 2564434161 N_PDU 0;
BA_ "GenSigTimeoutTime_MPAD" SG_ 2564434161 N_PDU 0;
BA_ "GenSigTimeoutTime_IPC" SG_ 2564434161 N_PDU 0;
BA_ "GenSigTimeoutTime_GNMM" SG_ 2564434161 N_PDU 0;
BA_ "GenSigTimeoutTime_EVCU2" SG_ 2564434161 N_PDU 0;
BA_ "GenSigTimeoutTime_ESL" SG_ 2564434161 N_PDU 0;
BA_ "GenSigTimeoutTime_ECM" SG_ 2564434161 N_PDU 0;
BA_ "GenSigTimeoutTime_DTCM" SG_ 2564434161 N_PDU 0;
BA_ "GenSigTimeoutTime_DMSM" SG_ 2564434161 N_PDU 0;
BA_ "GenSigTimeoutTime_BSM" SG_ 2564434161 N_PDU 0;
BA_ "GenSigTimeoutTime_BCM" SG_ 2564434161 N_PDU 0;
BA_ "GenSigTimeoutTime_AGSM" SG_ 2564434161 N_PDU 0;
BA_ "GenSigTimeoutTime_ADCAM" SG_ 2564434161 N_PDU 0;
BA_ "GenSigTimeoutTime_SGW" SG_ 2564440305 N_PDU 0;
BA_ "GenSigTimeoutTime_RFHM" SG_ 2564440305 N_PDU 0;
BA_ "GenSigTimeoutTime_MPAD" SG_ 2564440305 N_PDU 0;
BA_ "GenSigTimeoutTime_IPC" SG_ 2564440305 N_PDU 0;
BA_ "GenSigTimeoutTime_GNMM" SG_ 2564440305 N_PDU 0;
BA_ "GenSigTimeoutTime_EVCU2" SG_ 2564440305 N_PDU 0;
BA_ "GenSigTimeoutTime_ESL" SG_ 2564440305 N_PDU 0;
BA_ "GenSigTimeoutTime_ECM" SG_ 2564440305 N_PDU 0;
BA_ "GenSigTimeoutTime_DTCM" SG_ 2564440305 N_PDU 0;
BA_ "GenSigTimeoutTime_DMSM" SG_ 2564440305 N_PDU 0;
BA_ "GenSigTimeoutTime_BSM" SG_ 2564440305 N_PDU 0;
BA_ "GenSigTimeoutTime_BCM" SG_ 2564440305 N_PDU 0;
BA_ "GenSigTimeoutTime_AGSM" SG_ 2564440305 N_PDU 0;
BA_ "GenSigTimeoutTime_ADCAM" SG_ 2564440305 N_PDU 0;
BA_ "GenSigTimeoutTime_SGW" SG_ 2564474097 N_PDU 0;
BA_ "GenSigTimeoutTime_RFHM" SG_ 2564474097 N_PDU 0;
BA_ "GenSigTimeoutTime_MPAD" SG_ 2564474097 N_PDU 0;
BA_ "GenSigTimeoutTime_IPC" SG_ 2564474097 N_PDU 0;
BA_ "GenSigTimeoutTime_GNMM" SG_ 2564474097 N_PDU 0;
BA_ "GenSigTimeoutTime_EVCU2" SG_ 2564474097 N_PDU 0;
BA_ "GenSigTimeoutTime_ESL" SG_ 2564474097 N_PDU 0;
BA_ "GenSigTimeoutTime_ECM" SG_ 2564474097 N_PDU 0;
BA_ "GenSigTimeoutTime_DTCM" SG_ 2564474097 N_PDU 0;
BA_ "GenSigTimeoutTime_DMSM" SG_ 2564474097 N_PDU 0;
BA_ "GenSigTimeoutTime_BSM" SG_ 2564474097 N_PDU 0;
BA_ "GenSigTimeoutTime_BCM" SG_ 2564474097 N_PDU 0;
BA_ "GenSigTimeoutTime_AGSM" SG_ 2564474097 N_PDU 0;
BA_ "GenSigTimeoutTime_ADCAM" SG_ 2564474097 N_PDU 0;
BA_ "GenSigTimeoutTime_SGW" SG_ 2564428017 N_PDU 0;
BA_ "GenSigTimeoutTime_RFHM" SG_ 2564428017 N_PDU 0;
BA_ "GenSigTimeoutTime_MPAD" SG_ 2564428017 N_PDU 0;
BA_ "GenSigTimeoutTime_IPC" SG_ 2564428017 N_PDU 0;
BA_ "GenSigTimeoutTime_GNMM" SG_ 2564428017 N_PDU 0;
BA_ "GenSigTimeoutTime_EVCU2" SG_ 2564428017 N_PDU 0;
BA_ "GenSigTimeoutTime_ESL" SG_ 2564428017 N_PDU 0;
BA_ "GenSigTimeoutTime_ECM" SG_ 2564428017 N_PDU 0;
BA_ "GenSigTimeoutTime_DTCM" SG_ 2564428017 N_PDU 0;
BA_ "GenSigTimeoutTime_DMSM" SG_ 2564428017 N_PDU 0;
BA_ "GenSigTimeoutTime_BSM" SG_ 2564428017 N_PDU 0;
BA_ "GenSigTimeoutTime_BCM" SG_ 2564428017 N_PDU 0;
BA_ "GenSigTimeoutTime_AGSM" SG_ 2564428017 N_PDU 0;
BA_ "GenSigTimeoutTime_ADCAM" SG_ 2564428017 N_PDU 0;
BA_ "GenSigTimeoutTime_BCM" SG_ 1053 VIN_DATA 0;
BA_ "GenSigTimeoutTime_SGW" SG_ 156 TSI_Offset_Kph_Req 0;
BA_ "GenSigTimeoutTime_RFHM" SG_ 156 TSI_Offset_Kph_Req 0;
BA_ "GenSigTimeoutTime_MPAD" SG_ 156 TSI_Offset_Kph_Req 0;
BA_ "GenSigTimeoutTime_GNMM" SG_ 156 TSI_Offset_Kph_Req 0;
BA_ "GenSigTimeoutTime_EVCU2" SG_ 156 TSI_Offset_Kph_Req 0;
BA_ "GenSigTimeoutTime_ESL" SG_ 156 TSI_Offset_Kph_Req 0;
BA_ "GenSigTimeoutTime_ECM" SG_ 156 TSI_Offset_Kph_Req 0;
BA_ "GenSigTimeoutTime_DTCM" SG_ 156 TSI_Offset_Kph_Req 0;
BA_ "GenSigTimeoutTime_DMSM" SG_ 156 TSI_Offset_Kph_Req 0;
BA_ "GenSigTimeoutTime_BSM" SG_ 156 TSI_Offset_Kph_Req 0;
BA_ "GenSigTimeoutTime_BCM" SG_ 156 TSI_Offset_Kph_Req 0;
BA_ "GenSigTimeoutTime_AGSM" SG_ 156 TSI_Offset_Kph_Req 0;
BA_ "GenSigTimeoutTime_ADCAM" SG_ 156 TSI_Offset_Kph_Req 0;
BA_ "GenSigTimeoutTime_SGW" SG_ 156 TSI_Offset_Mph_Req 0;
BA_ "GenSigTimeoutTime_RFHM" SG_ 156 TSI_Offset_Mph_Req 0;
BA_ "GenSigTimeoutTime_MPAD" SG_ 156 TSI_Offset_Mph_Req 0;
BA_ "GenSigTimeoutTime_GNMM" SG_ 156 TSI_Offset_Mph_Req 0;
BA_ "GenSigTimeoutTime_EVCU2" SG_ 156 TSI_Offset_Mph_Req 0;
BA_ "GenSigTimeoutTime_ESL" SG_ 156 TSI_Offset_Mph_Req 0;
BA_ "GenSigTimeoutTime_ECM" SG_ 156 TSI_Offset_Mph_Req 0;
BA_ "GenSigTimeoutTime_DTCM" SG_ 156 TSI_Offset_Mph_Req 0;
BA_ "GenSigTimeoutTime_DMSM" SG_ 156 TSI_Offset_Mph_Req 0;
BA_ "GenSigTimeoutTime_BSM" SG_ 156 TSI_Offset_Mph_Req 0;
BA_ "GenSigTimeoutTime_BCM" SG_ 156 TSI_Offset_Mph_Req 0;
BA_ "GenSigTimeoutTime_AGSM" SG_ 156 TSI_Offset_Mph_Req 0;
BA_ "GenSigTimeoutTime_ADCAM" SG_ 156 TSI_Offset_Mph_Req 0;
BA_ "GenSigSendType" SG_ 156 TSI_Offset_Mph_Req 1;
BA_ "GenSigTimeoutTime_ESL" SG_ 156 TurnSignalView_Req 0;
BA_ "GenSigTimeoutTime_ECM" SG_ 156 TurnSignalView_Req 0;
BA_ "GenSigTimeoutTime_DTCM" SG_ 156 TurnSignalView_Req 0;
BA_ "GenSigTimeoutTime_DMSM" SG_ 156 TurnSignalView_Req 0;
BA_ "GenSigTimeoutTime_BSM" SG_ 156 TurnSignalView_Req 0;
BA_ "GenSigTimeoutTime_BCM" SG_ 156 TurnSignalView_Req 0;
BA_ "GenSigTimeoutTime_AGSM" SG_ 156 TurnSignalView_Req 0;
BA_ "GenSigTimeoutTime_ADCAM" SG_ 156 TurnSignalView_Req 0;
BA_ "GenSigSendType" SG_ 156 TurnSignalView_Req 4;
BA_ "GenSigTimeoutTime_SGW" SG_ 156 TurnSignalView_Req 0;
BA_ "GenSigTimeoutTime_RFHM" SG_ 156 TurnSignalView_Req 0;
BA_ "GenSigTimeoutTime_MPAD" SG_ 156 TurnSignalView_Req 0;
BA_ "GenSigTimeoutTime_GNMM" SG_ 156 TurnSignalView_Req 0;
BA_ "GenSigTimeoutTime_EVCU2" SG_ 156 TurnSignalView_Req 0;
BA_ "GenSigTimeoutTime_ESL" SG_ 156 Hour1_TLM 0;
BA_ "GenSigTimeoutTime_ECM" SG_ 156 Hour1_TLM 0;
BA_ "GenSigTimeoutTime_DTCM" SG_ 156 Hour1_TLM 0;
BA_ "GenSigTimeoutTime_DMSM" SG_ 156 Hour1_TLM 0;
BA_ "GenSigTimeoutTime_BSM" SG_ 156 Hour1_TLM 0;
BA_ "GenSigTimeoutTime_BCM" SG_ 156 Hour1_TLM 0;
BA_ "GenSigTimeoutTime_AGSM" SG_ 156 Hour1_TLM 0;
BA_ "GenSigTimeoutTime_ADCAM" SG_ 156 Hour1_TLM 0;
BA_ "GenSigTimeoutTime_SGW" SG_ 156 Hour2_TLM 0;
BA_ "GenSigTimeoutTime_MPAD" SG_ 156 Hour2_TLM 0;
BA_ "GenSigTimeoutTime_GNMM" SG_ 156 Hour2_TLM 0;
BA_ "GenSigTimeoutTime_ESL" SG_ 156 Hour2_TLM 0;
BA_ "GenSigTimeoutTime_ECM" SG_ 156 Hour2_TLM 0;
BA_ "GenSigTimeoutTime_DTCM" SG_ 156 Hour2_TLM 0;
BA_ "GenSigTimeoutTime_DMSM" SG_ 156 Hour2_TLM 0;
BA_ "GenSigTimeoutTime_BSM" SG_ 156 Hour2_TLM 0;
BA_ "GenSigTimeoutTime_BCM" SG_ 156 Hour2_TLM 0;
BA_ "GenSigTimeoutTime_AGSM" SG_ 156 Hour2_TLM 0;
BA_ "GenSigTimeoutTime_ADCAM" SG_ 156 Hour2_TLM 0;
BA_ "GenSigTimeoutTime_SGW" SG_ 156 Minute1_TLM 0;
BA_ "GenSigTimeoutTime_MPAD" SG_ 156 Minute1_TLM 0;
BA_ "GenSigTimeoutTime_GNMM" SG_ 156 Minute1_TLM 0;
BA_ "GenSigTimeoutTime_ESL" SG_ 156 Minute1_TLM 0;
BA_ "GenSigTimeoutTime_ECM" SG_ 156 Minute1_TLM 0;
BA_ "GenSigTimeoutTime_DTCM" SG_ 156 Minute1_TLM 0;
BA_ "GenSigTimeoutTime_DMSM" SG_ 156 Minute1_TLM 0;
BA_ "GenSigTimeoutTime_BSM" SG_ 156 Minute1_TLM 0;
BA_ "GenSigTimeoutTime_BCM" SG_ 156 Minute1_TLM 0;
BA_ "GenSigTimeoutTime_AGSM" SG_ 156 Minute1_TLM 0;
BA_ "GenSigTimeoutTime_ADCAM" SG_ 156 Minute1_TLM 0;
BA_ "GenSigTimeoutTime_SGW" SG_ 156 Minute2_TLM 0;
BA_ "GenSigTimeoutTime_MPAD" SG_ 156 Minute2_TLM 0;
BA_ "GenSigTimeoutTime_GNMM" SG_ 156 Minute2_TLM 0;
BA_ "GenSigTimeoutTime_ESL" SG_ 156 Minute2_TLM 0;
BA_ "GenSigTimeoutTime_ECM" SG_ 156 Minute2_TLM 0;
BA_ "GenSigTimeoutTime_DTCM" SG_ 156 Minute2_TLM 0;
BA_ "GenSigTimeoutTime_DMSM" SG_ 156 Minute2_TLM 0;
BA_ "GenSigTimeoutTime_BSM" SG_ 156 Minute2_TLM 0;
BA_ "GenSigTimeoutTime_BCM" SG_ 156 Minute2_TLM 0;
BA_ "GenSigTimeoutTime_AGSM" SG_ 156 Minute2_TLM 0;
BA_ "GenSigTimeoutTime_ADCAM" SG_ 156 Minute2_TLM 0;
BA_ "GenSigTimeoutTime_SGW" SG_ 156 Month1_TLM 0;
BA_ "GenSigTimeoutTime_MPAD" SG_ 156 Month1_TLM 0;
BA_ "GenSigTimeoutTime_IPC" SG_ 156 Month1_TLM 0;
BA_ "GenSigTimeoutTime_GNMM" SG_ 156 Month1_TLM 0;
BA_ "GenSigTimeoutTime_ESL" SG_ 156 Month1_TLM 0;
BA_ "GenSigTimeoutTime_ECM" SG_ 156 Month1_TLM 0;
BA_ "GenSigTimeoutTime_DTCM" SG_ 156 Month1_TLM 0;
BA_ "GenSigTimeoutTime_DMSM" SG_ 156 Month1_TLM 0;
BA_ "GenSigTimeoutTime_BSM" SG_ 156 Month1_TLM 0;
BA_ "GenSigTimeoutTime_BCM" SG_ 156 Month1_TLM 0;
BA_ "GenSigTimeoutTime_AGSM" SG_ 156 Month1_TLM 0;
BA_ "GenSigTimeoutTime_ADCAM" SG_ 156 Month1_TLM 0;
BA_ "GenSigTimeoutTime_SGW" SG_ 156 Day2_TLM 0;
BA_ "GenSigTimeoutTime_MPAD" SG_ 156 Day2_TLM 0;
BA_ "GenSigTimeoutTime_IPC" SG_ 156 Day2_TLM 0;
BA_ "GenSigTimeoutTime_GNMM" SG_ 156 Day2_TLM 0;
BA_ "GenSigTimeoutTime_ESL" SG_ 156 Day2_TLM 0;
BA_ "GenSigTimeoutTime_ECM" SG_ 156 Day2_TLM 0;
BA_ "GenSigTimeoutTime_DTCM" SG_ 156 Day2_TLM 0;
BA_ "GenSigTimeoutTime_DMSM" SG_ 156 Day2_TLM 0;
BA_ "GenSigTimeoutTime_BSM" SG_ 156 Day2_TLM 0;
BA_ "GenSigTimeoutTime_BCM" SG_ 156 Day2_TLM 0;
BA_ "GenSigTimeoutTime_AGSM" SG_ 156 Day2_TLM 0;
BA_ "GenSigTimeoutTime_ADCAM" SG_ 156 Day2_TLM 0;
BA_ "GenSigTimeoutTime_SGW" SG_ 156 Day1_TLM 0;
BA_ "GenSigTimeoutTime_MPAD" SG_ 156 Day1_TLM 0;
BA_ "GenSigTimeoutTime_IPC" SG_ 156 Day1_TLM 0;
BA_ "GenSigTimeoutTime_GNMM" SG_ 156 Day1_TLM 0;
BA_ "GenSigTimeoutTime_ESL" SG_ 156 Day1_TLM 0;
BA_ "GenSigTimeoutTime_ECM" SG_ 156 Day1_TLM 0;
BA_ "GenSigTimeoutTime_DTCM" SG_ 156 Day1_TLM 0;
BA_ "GenSigTimeoutTime_DMSM" SG_ 156 Day1_TLM 0;
BA_ "GenSigTimeoutTime_BSM" SG_ 156 Day1_TLM 0;
BA_ "GenSigTimeoutTime_BCM" SG_ 156 Day1_TLM 0;
BA_ "GenSigTimeoutTime_AGSM" SG_ 156 Day1_TLM 0;
BA_ "GenSigTimeoutTime_ADCAM" SG_ 156 Day1_TLM 0;
BA_ "GenSigSendType" SG_ 156 Day1_TLM 1;
BA_ "GenSigTimeoutTime_ECM" SG_ 2651930691 Digit_03_DTCM 0;
BA_ "GenSigTimeoutTime_DTCM" SG_ 2651930691 Digit_03_DTCM 0;
BA_ "GenSigTimeoutTime_DMSM" SG_ 2651930691 Digit_03_DTCM 0;
BA_ "GenSigTimeoutTime_BSM" SG_ 2651930691 Digit_03_DTCM 0;
BA_ "GenSigTimeoutTime_AGSM" SG_ 2651930691 Digit_03_DTCM 0;
BA_ "GenSigTimeoutTime_ADCAM" SG_ 2651930691 Digit_03_DTCM 0;
BA_ "GenSigTimeoutTime_SGW" SG_ 2651930691 Digit_04_DTCM 0;
BA_ "GenSigTimeoutTime_RFHM" SG_ 2651930691 Digit_04_DTCM 0;
BA_ "GenSigTimeoutTime_MPAD" SG_ 2651930691 Digit_04_DTCM 0;
BA_ "GenSigTimeoutTime_IPC" SG_ 2651930691 Digit_04_DTCM 0;
BA_ "GenSigTimeoutTime_GNMM" SG_ 2651930691 Digit_04_DTCM 0;
BA_ "GenSigTimeoutTime_EVCU2" SG_ 2651930691 Digit_04_DTCM 0;
BA_ "GenSigTimeoutTime_ESL" SG_ 2651930691 Digit_04_DTCM 0;
BA_ "GenSigTimeoutTime_ECM" SG_ 2651930691 Digit_04_DTCM 0;
BA_ "GenSigTimeoutTime_DTCM" SG_ 2651930691 Digit_04_DTCM 0;
BA_ "GenSigTimeoutTime_DMSM" SG_ 2651930691 Digit_04_DTCM 0;
BA_ "GenSigTimeoutTime_BSM" SG_ 2651930691 Digit_04_DTCM 0;
BA_ "GenSigTimeoutTime_AGSM" SG_ 2651930691 Digit_04_DTCM 0;
BA_ "GenSigTimeoutTime_ADCAM" SG_ 2651930691 Digit_04_DTCM 0;
BA_ "GenSigTimeoutTime_SGW" SG_ 2651930691 Digit_05_DTCM 0;
BA_ "GenSigTimeoutTime_RFHM" SG_ 2651930691 Digit_05_DTCM 0;
BA_ "GenSigTimeoutTime_MPAD" SG_ 2651930691 Digit_05_DTCM 0;
BA_ "GenSigTimeoutTime_IPC" SG_ 2651930691 Digit_05_DTCM 0;
BA_ "GenSigTimeoutTime_GNMM" SG_ 2651930691 Digit_05_DTCM 0;
BA_ "GenSigTimeoutTime_EVCU2" SG_ 2651930691 Digit_05_DTCM 0;
BA_ "GenSigTimeoutTime_ESL" SG_ 2651930691 Digit_05_DTCM 0;
BA_ "GenSigTimeoutTime_ECM" SG_ 2651930691 Digit_05_DTCM 0;
BA_ "GenSigTimeoutTime_DTCM" SG_ 2651930691 Digit_05_DTCM 0;
BA_ "GenSigTimeoutTime_DMSM" SG_ 2651930691 Digit_05_DTCM 0;
BA_ "GenSigTimeoutTime_BSM" SG_ 2651930691 Digit_05_DTCM 0;
BA_ "GenSigTimeoutTime_AGSM" SG_ 2651930691 Digit_05_DTCM 0;
BA_ "GenSigTimeoutTime_ADCAM" SG_ 2651930691 Digit_05_DTCM 0;
BA_ "GenSigTimeoutTime_SGW" SG_ 2651930691 Digit_06_DTCM 0;
BA_ "GenSigTimeoutTime_RFHM" SG_ 2651930691 Digit_06_DTCM 0;
BA_ "GenSigTimeoutTime_MPAD" SG_ 2651930691 Digit_06_DTCM 0;
BA_ "GenSigTimeoutTime_IPC" SG_ 2651930691 Digit_06_DTCM 0;
BA_ "GenSigTimeoutTime_GNMM" SG_ 2651930691 Digit_06_DTCM 0;
BA_ "GenSigTimeoutTime_EVCU2" SG_ 2651930691 Digit_06_DTCM 0;
BA_ "GenSigTimeoutTime_ESL" SG_ 2651930691 Digit_06_DTCM 0;
BA_ "GenSigTimeoutTime_ECM" SG_ 2651930691 Digit_06_DTCM 0;
BA_ "GenSigTimeoutTime_DTCM" SG_ 2651930691 Digit_06_DTCM 0;
BA_ "GenSigTimeoutTime_DMSM" SG_ 2651930691 Digit_06_DTCM 0;
BA_ "GenSigTimeoutTime_BSM" SG_ 2651930691 Digit_06_DTCM 0;
BA_ "GenSigTimeoutTime_AGSM" SG_ 2651930691 Digit_06_DTCM 0;
BA_ "GenSigTimeoutTime_ADCAM" SG_ 2651930691 Digit_06_DTCM 0;
BA_ "GenSigTimeoutTime_GNMM" SG_ 2651930691 Digit_07_DTCM 0;
BA_ "GenSigTimeoutTime_EVCU2" SG_ 2651930691 Digit_07_DTCM 0;
BA_ "GenSigTimeoutTime_ESL" SG_ 2651930691 Digit_07_DTCM 0;
BA_ "GenSigTimeoutTime_ECM" SG_ 2651930691 Digit_07_DTCM 0;
BA_ "GenSigTimeoutTime_DTCM" SG_ 2651930691 Digit_07_DTCM 0;
BA_ "GenSigTimeoutTime_DMSM" SG_ 2651930691 Digit_07_DTCM 0;
BA_ "GenSigTimeoutTime_BSM" SG_ 2651930691 Digit_07_DTCM 0;
BA_ "GenSigTimeoutTime_AGSM" SG_ 2651930691 Digit_07_DTCM 0;
BA_ "GenSigTimeoutTime_ADCAM" SG_ 2651930691 Digit_07_DTCM 0;
BA_ "GenSigTimeoutTime_SGW" SG_ 2651930630 Digit_01_BSM 0;
BA_ "GenSigTimeoutTime_RFHM" SG_ 2651930630 Digit_01_BSM 0;
BA_ "GenSigTimeoutTime_MPAD" SG_ 2651930630 Digit_01_BSM 0;
BA_ "GenSigTimeoutTime_IPC" SG_ 2651930630 Digit_01_BSM 0;
BA_ "GenSigTimeoutTime_GNMM" SG_ 2651930630 Digit_01_BSM 0;
BA_ "GenSigTimeoutTime_EVCU2" SG_ 2651930630 Digit_01_BSM 0;
BA_ "GenSigTimeoutTime_ESL" SG_ 2651930630 Digit_01_BSM 0;
BA_ "GenSigTimeoutTime_ECM" SG_ 2651930630 Digit_01_BSM 0;
BA_ "GenSigTimeoutTime_DTCM" SG_ 2651930630 Digit_01_BSM 0;
BA_ "GenSigTimeoutTime_DMSM" SG_ 2651930630 Digit_01_BSM 0;
BA_ "GenSigTimeoutTime_BSM" SG_ 2651930630 Digit_01_BSM 0;
BA_ "GenSigTimeoutTime_AGSM" SG_ 2651930630 Digit_01_BSM 0;
BA_ "GenSigTimeoutTime_ADCAM" SG_ 2651930630 Digit_01_BSM 0;
BA_ "GenSigSendType" SG_ 2651930630 Digit_01_BSM 1;
BA_ "GenSigTimeoutTime_SGW" SG_ 2651930630 Digit_02_BSM 0;
BA_ "GenSigTimeoutTime_RFHM" SG_ 2651930630 Digit_02_BSM 0;
BA_ "GenSigTimeoutTime_MPAD" SG_ 2651930630 Digit_02_BSM 0;
BA_ "GenSigTimeoutTime_IPC" SG_ 2651930630 Digit_02_BSM 0;
BA_ "GenSigTimeoutTime_GNMM" SG_ 2651930630 Digit_02_BSM 0;
BA_ "GenSigTimeoutTime_EVCU2" SG_ 2651930630 Digit_02_BSM 0;
BA_ "GenSigTimeoutTime_ESL" SG_ 2651930630 Digit_02_BSM 0;
BA_ "GenSigTimeoutTime_ECM" SG_ 2651930630 Digit_02_BSM 0;
BA_ "GenSigTimeoutTime_DTCM" SG_ 2651930630 Digit_02_BSM 0;
BA_ "GenSigTimeoutTime_DMSM" SG_ 2651930630 Digit_02_BSM 0;
BA_ "GenSigTimeoutTime_BSM" SG_ 2651930630 Digit_02_BSM 0;
BA_ "GenSigTimeoutTime_AGSM" SG_ 2651930630 Digit_02_BSM 0;
BA_ "GenSigTimeoutTime_ADCAM" SG_ 2651930630 Digit_02_BSM 0;
BA_ "GenSigTimeoutTime_GNMM" SG_ 2651930630 Digit_03_BSM 0;
BA_ "GenSigTimeoutTime_EVCU2" SG_ 2651930630 Digit_03_BSM 0;
BA_ "GenSigTimeoutTime_ESL" SG_ 2651930630 Digit_03_BSM 0;
BA_ "GenSigTimeoutTime_ECM" SG_ 2651930630 Digit_03_BSM 0;
BA_ "GenSigTimeoutTime_DTCM" SG_ 2651930630 Digit_03_BSM 0;
BA_ "GenSigTimeoutTime_DMSM" SG_ 2651930630 Digit_03_BSM 0;
BA_ "GenSigTimeoutTime_BSM" SG_ 2651930630 Digit_03_BSM 0;
BA_ "GenSigTimeoutTime_AGSM" SG_ 2651930630 Digit_03_BSM 0;
BA_ "GenSigTimeoutTime_ADCAM" SG_ 2651930630 Digit_03_BSM 0;
BA_ "GenSigTimeoutTime_BCM" SG_ 1053 VIN_MSG 0;
BA_ "GenSigStartValue" SG_ 1053 VIN_MSG 3;
BA_ "GenSigTimeoutTime_RFHM" SG_ 1428 HU_CMP 0;
BA_ "GenSigTimeoutTime_MPAD" SG_ 1428 HU_CMP 0;
BA_ "GenSigTimeoutTime_IPC" SG_ 1428 HU_CMP 0;
BA_ "GenSigTimeoutTime_GNMM" SG_ 1428 HU_CMP 0;
BA_ "GenSigTimeoutTime_EVCU2" SG_ 1428 HU_CMP 0;
BA_ "GenSigTimeoutTime_ESL" SG_ 1428 HU_CMP 0;
BA_ "GenSigTimeoutTime_ECM" SG_ 1428 HU_CMP 0;
BA_ "GenSigTimeoutTime_DTCM" SG_ 1428 HU_CMP 0;
BA_ "GenSigTimeoutTime_DMSM" SG_ 1428 HU_CMP 0;
BA_ "GenSigTimeoutTime_BSM" SG_ 1428 HU_CMP 0;
BA_ "GenSigTimeoutTime_AGSM" SG_ 1428 HU_CMP 0;
BA_ "GenSigTimeoutTime_ADCAM" SG_ 1428 HU_CMP 0;
BA_ "GenSigSendType" SG_ 1428 HU_CMP 3;
BA_ "GenSigStartValue" SG_ 1428 HU_CMP 15;
BA_ "GenSigTimeoutTime_SGW" SG_ 1428 HU_CMP 0;
BA_ "GenSigTimeoutTime_SGW" SG_ 1428 NAV_ARROW 0;
BA_ "GenSigTimeoutTime_RFHM" SG_ 1428 NAV_ARROW 0;
BA_ "GenSigTimeoutTime_GNMM" SG_ 1428 NAV_ARROW 0;
BA_ "GenSigTimeoutTime_EVCU2" SG_ 1428 NAV_ARROW 0;
BA_ "GenSigTimeoutTime_ESL" SG_ 1428 NAV_ARROW 0;
BA_ "GenSigTimeoutTime_ECM" SG_ 1428 NAV_ARROW 0;
BA_ "GenSigTimeoutTime_DTCM" SG_ 1428 NAV_ARROW 0;
BA_ "GenSigTimeoutTime_DMSM" SG_ 1428 NAV_ARROW 0;
BA_ "GenSigTimeoutTime_BSM" SG_ 1428 NAV_ARROW 0;
BA_ "GenSigTimeoutTime_BCM" SG_ 1428 NAV_ARROW 0;
BA_ "GenSigTimeoutTime_AGSM" SG_ 1428 NAV_ARROW 0;
BA_ "GenSigTimeoutTime_ADCAM" SG_ 1428 NAV_ARROW 0;
BA_ "GenSigSendType" SG_ 1428 NAV_ARROW 3;
BA_ "GenSigTimeoutTime_SGW" SG_ 1428 NAVPrsnt 0;
BA_ "GenSigTimeoutTime_RFHM" SG_ 1428 NAVPrsnt 0;
BA_ "GenSigTimeoutTime_MPAD" SG_ 1428 NAVPrsnt 0;
BA_ "GenSigTimeoutTime_GNMM" SG_ 1428 NAVPrsnt 0;
BA_ "GenSigTimeoutTime_EVCU2" SG_ 1428 NAVPrsnt 0;
BA_ "GenSigTimeoutTime_ESL" SG_ 1428 NAVPrsnt 0;
BA_ "GenSigTimeoutTime_ECM" SG_ 1428 NAVPrsnt 0;
BA_ "GenSigTimeoutTime_DTCM" SG_ 1428 NAVPrsnt 0;
BA_ "GenSigTimeoutTime_DMSM" SG_ 1428 NAVPrsnt 0;
BA_ "GenSigTimeoutTime_BSM" SG_ 1428 NAVPrsnt 0;
BA_ "GenSigTimeoutTime_BCM" SG_ 1428 NAVPrsnt 0;
BA_ "GenSigTimeoutTime_AGSM" SG_ 1428 NAVPrsnt 0;
BA_ "GenSigTimeoutTime_ADCAM" SG_ 1428 NAVPrsnt 0;
BA_ "GenSigSendType" SG_ 1428 NAVPrsnt 3;
BA_ "GenSigTimeoutTime_SGW" SG_ 1428 T_BY_T_ON 0;
BA_ "GenSigTimeoutTime_RFHM" SG_ 1428 T_BY_T_ON 0;
BA_ "GenSigTimeoutTime_GNMM" SG_ 1428 T_BY_T_ON 0;
BA_ "GenSigTimeoutTime_EVCU2" SG_ 1428 T_BY_T_ON 0;
BA_ "GenSigTimeoutTime_ESL" SG_ 1428 T_BY_T_ON 0;
BA_ "GenSigTimeoutTime_ECM" SG_ 1428 T_BY_T_ON 0;
BA_ "GenSigTimeoutTime_DTCM" SG_ 1428 T_BY_T_ON 0;
BA_ "GenSigTimeoutTime_DMSM" SG_ 1428 T_BY_T_ON 0;
BA_ "GenSigTimeoutTime_BSM" SG_ 1428 T_BY_T_ON 0;
BA_ "GenSigTimeoutTime_BCM" SG_ 1428 T_BY_T_ON 0;
BA_ "GenSigTimeoutTime_AGSM" SG_ 1428 T_BY_T_ON 0;
BA_ "GenSigTimeoutTime_ADCAM" SG_ 1428 T_BY_T_ON 0;
BA_ "GenSigSendType" SG_ 1428 T_BY_T_ON 3;
BA_ "GenSigTimeoutTime_SGW" SG_ 1428 TURN_COMP 0;
BA_ "GenSigTimeoutTime_RFHM" SG_ 1428 TURN_COMP 0;
BA_ "GenSigTimeoutTime_GNMM" SG_ 1428 TURN_COMP 0;
BA_ "GenSigTimeoutTime_EVCU2" SG_ 1428 TURN_COMP 0;
BA_ "GenSigTimeoutTime_ESL" SG_ 1428 TURN_COMP 0;
BA_ "GenSigTimeoutTime_ECM" SG_ 1428 TURN_COMP 0;
BA_ "GenSigTimeoutTime_DTCM" SG_ 1428 TURN_COMP 0;
BA_ "GenSigTimeoutTime_DMSM" SG_ 1428 TURN_COMP 0;
BA_ "GenSigTimeoutTime_BSM" SG_ 1428 TURN_COMP 0;
BA_ "GenSigTimeoutTime_BCM" SG_ 1428 TURN_COMP 0;
BA_ "GenSigTimeoutTime_AGSM" SG_ 1428 TURN_COMP 0;
BA_ "GenSigTimeoutTime_ADCAM" SG_ 1428 TURN_COMP 0;
BA_ "GenSigSendType" SG_ 1428 TURN_COMP 3;
BA_ "GenSigTimeoutTime_SGW" SG_ 1428 NAV_UNITS 0;
BA_ "GenSigTimeoutTime_RFHM" SG_ 1428 NAV_UNITS 0;
BA_ "GenSigTimeoutTime_MPAD" SG_ 1428 NAV_UNITS 0;
BA_ "GenSigTimeoutTime_GNMM" SG_ 1428 NAV_UNITS 0;
BA_ "GenSigTimeoutTime_EVCU2" SG_ 1428 NAV_UNITS 0;
BA_ "GenSigTimeoutTime_ESL" SG_ 1428 NAV_UNITS 0;
BA_ "GenSigTimeoutTime_ECM" SG_ 1428 NAV_UNITS 0;
BA_ "GenSigTimeoutTime_DTCM" SG_ 1428 NAV_UNITS 0;
BA_ "GenSigTimeoutTime_DMSM" SG_ 1428 NAV_UNITS 0;
BA_ "GenSigTimeoutTime_BSM" SG_ 1428 NAV_UNITS 0;
BA_ "GenSigTimeoutTime_BCM" SG_ 1428 NAV_UNITS 0;
BA_ "GenSigTimeoutTime_AGSM" SG_ 1428 NAV_UNITS 0;
BA_ "GenSigTimeoutTime_ADCAM" SG_ 1428 NAV_UNITS 0;
BA_ "GenSigSendType" SG_ 1428 NAV_UNITS 3;
BA_ "GenSigTimeoutTime_SGW" SG_ 1428 DIST_TO_TURN 0;
BA_ "GenSigTimeoutTime_RFHM" SG_ 1428 DIST_TO_TURN 0;
BA_ "GenSigTimeoutTime_GNMM" SG_ 1428 DIST_TO_TURN 0;
BA_ "GenSigTimeoutTime_EVCU2" SG_ 1428 DIST_TO_TURN 0;
BA_ "GenSigTimeoutTime_ESL" SG_ 1428 DIST_TO_TURN 0;
BA_ "GenSigTimeoutTime_ECM" SG_ 1428 DIST_TO_TURN 0;
BA_ "GenSigTimeoutTime_DTCM" SG_ 1428 DIST_TO_TURN 0;
BA_ "GenSigTimeoutTime_DMSM" SG_ 1428 DIST_TO_TURN 0;
BA_ "GenSigTimeoutTime_BSM" SG_ 1428 DIST_TO_TURN 0;
BA_ "GenSigTimeoutTime_BCM" SG_ 1428 DIST_TO_TURN 0;
BA_ "GenSigTimeoutTime_AGSM" SG_ 1428 DIST_TO_TURN 0;
BA_ "GenSigTimeoutTime_ADCAM" SG_ 1428 DIST_TO_TURN 0;
BA_ "GenSigSendType" SG_ 1428 DIST_TO_TURN 3;
BA_ "GenSigTimeoutTime_SGW" SG_ 1378 ESLSts 0;
BA_ "GenSigTimeoutTime_RFHM" SG_ 1378 ESLSts 0;
BA_ "GenSigTimeoutTime_MPAD" SG_ 1378 ESLSts 0;
BA_ "GenSigTimeoutTime_IPC" SG_ 1378 ESLSts 0;
BA_ "GenSigTimeoutTime_GNMM" SG_ 1378 ESLSts 0;
BA_ "GenSigTimeoutTime_EVCU2" SG_ 1378 ESLSts 0;
BA_ "GenSigTimeoutTime_ESL" SG_ 1378 ESLSts 0;
BA_ "GenSigTimeoutTime_ECM" SG_ 1378 ESLSts 0;
BA_ "GenSigTimeoutTime_DTCM" SG_ 1378 ESLSts 0;
BA_ "GenSigTimeoutTime_DMSM" SG_ 1378 ESLSts 0;
BA_ "GenSigTimeoutTime_BSM" SG_ 1378 ESLSts 0;
BA_ "GenSigTimeoutTime_AGSM" SG_ 1378 ESLSts 0;
BA_ "GenSigTimeoutTime_ADCAM" SG_ 1378 ESLSts 0;
BA_ "GenSigStartValue" SG_ 1378 ESLSts 6;
BA_ "GenSigTimeoutTime_SGW" SG_ 1449 MsgFOBLeftVeh 0;
BA_ "GenSigTimeoutTime_RFHM" SG_ 1449 MsgFOBLeftVeh 0;
BA_ "GenSigTimeoutTime_ADCAM" SG_ 1428 CRC_Telematic5 0;
BA_ "GenSigTimeoutTime_SGW" SG_ 2564485402 N_PDU 0;
BA_ "GenSigTimeoutTime_RFHM" SG_ 2564485402 N_PDU 0;
BA_ "GenSigTimeoutTime_MPAD" SG_ 2564485402 N_PDU 0;
BA_ "GenSigTimeoutTime_IPC" SG_ 2564485402 N_PDU 0;
BA_ "GenSigTimeoutTime_GNMM" SG_ 2564485402 N_PDU 0;
BA_ "GenSigTimeoutTime_EVCU2" SG_ 2564485402 N_PDU 0;
BA_ "GenSigTimeoutTime_ESL" SG_ 2564485402 N_PDU 0;
BA_ "GenSigTimeoutTime_ECM" SG_ 2564485402 N_PDU 0;
BA_ "GenSigTimeoutTime_DTCM" SG_ 2564485402 N_PDU 0;
BA_ "GenSigTimeoutTime_DMSM" SG_ 2564485402 N_PDU 0;
BA_ "GenSigTimeoutTime_BSM" SG_ 2564485402 N_PDU 0;
BA_ "GenSigTimeoutTime_BCM" SG_ 2564485402 N_PDU 0;
BA_ "GenSigTimeoutTime_AGSM" SG_ 2564485402 N_PDU 0;
BA_ "GenSigTimeoutTime_ADCAM" SG_ 2564485402 N_PDU 0;
BA_ "GenSigTimeoutTime_EVCU2" SG_ 2564485392 N_PDU 0;
BA_ "GenSigTimeoutTime_ESL" SG_ 2564485392 N_PDU 0;
BA_ "GenSigTimeoutTime_ECM" SG_ 2564485392 N_PDU 0;
BA_ "GenSigTimeoutTime_DTCM" SG_ 2564485392 N_PDU 0;
BA_ "GenSigTimeoutTime_DMSM" SG_ 2564485392 N_PDU 0;
BA_ "GenSigTimeoutTime_BSM" SG_ 2564485392 N_PDU 0;
BA_ "GenSigTimeoutTime_BCM" SG_ 2564485392 N_PDU 0;
BA_ "GenSigTimeoutTime_AGSM" SG_ 2564485392 N_PDU 0;
BA_ "GenSigTimeoutTime_ADCAM" SG_ 2564485392 N_PDU 0;
BA_ "GenSigTimeoutTime_SGW" SG_ 2564485392 N_PDU 0;
BA_ "GenSigTimeoutTime_RFHM" SG_ 2564485392 N_PDU 0;
BA_ "GenSigTimeoutTime_MPAD" SG_ 2564485392 N_PDU 0;
BA_ "GenSigTimeoutTime_IPC" SG_ 2564485392 N_PDU 0;
BA_ "GenSigTimeoutTime_GNMM" SG_ 2564485392 N_PDU 0;
BA_ "GenSigTimeoutTime_SGW" SG_ 2564485572 N_PDU 0;
BA_ "GenSigTimeoutTime_RFHM" SG_ 2564485572 N_PDU 0;
BA_ "GenSigTimeoutTime_MPAD" SG_ 2564485572 N_PDU 0;
BA_ "GenSigTimeoutTime_IPC" SG_ 2564485572 N_PDU 0;
BA_ "GenSigTimeoutTime_GNMM" SG_ 2564485572 N_PDU 0;
BA_ "GenSigTimeoutTime_EVCU2" SG_ 2564485572 N_PDU 0;
BA_ "GenSigTimeoutTime_ESL" SG_ 2564485572 N_PDU 0;
BA_ "GenSigTimeoutTime_ECM" SG_ 2564485572 N_PDU 0;
BA_ "GenSigTimeoutTime_DTCM" SG_ 2564485572 N_PDU 0;
BA_ "GenSigTimeoutTime_DMSM" SG_ 2564485572 N_PDU 0;
BA_ "GenSigTimeoutTime_BSM" SG_ 2564485572 N_PDU 0;
BA_ "GenSigTimeoutTime_BCM" SG_ 2564485572 N_PDU 0;
BA_ "GenSigTimeoutTime_AGSM" SG_ 2564485572 N_PDU 0;
BA_ "GenSigTimeoutTime_ADCAM" SG_ 2564485572 N_PDU 0;
BA_ "GenSigTimeoutTime_SGW" SG_ 156 STFARrAlertPress 0;
BA_ "GenSigTimeoutTime_MPAD" SG_ 156 STFARrAlertPress 0;
BA_ "GenSigTimeoutTime_IPC" SG_ 156 STFARrAlertPress 0;
BA_ "GenSigTimeoutTime_GNMM" SG_ 156 STFARrAlertPress 0;
BA_ "GenSigTimeoutTime_EVCU2" SG_ 156 STFARrAlertPress 0;
BA_ "GenSigTimeoutTime_ESL" SG_ 156 STFARrAlertPress 0;
BA_ "GenSigTimeoutTime_ECM" SG_ 156 STFARrAlertPress 0;
BA_ "GenSigTimeoutTime_DTCM" SG_ 156 STFARrAlertPress 0;
BA_ "GenSigTimeoutTime_DMSM" SG_ 156 STFARrAlertPress 0;
BA_ "GenSigTimeoutTime_BSM" SG_ 156 STFARrAlertPress 0;
BA_ "GenSigTimeoutTime_BCM" SG_ 156 STFARrAlertPress 0;
BA_ "GenSigTimeoutTime_AGSM" SG_ 156 STFARrAlertPress 0;
BA_ "GenSigTimeoutTime_ADCAM" SG_ 156 STFARrAlertPress 0;
BA_ "GenSigSendType" SG_ 156 STFARrAlertPress 3;
BA_ "GenSigTimeoutTime_SGW" SG_ 156 STFAFtAlertPress 0;
BA_ "GenSigTimeoutTime_MPAD" SG_ 156 STFAFtAlertPress 0;
BA_ "GenSigTimeoutTime_IPC" SG_ 156 STFAFtAlertPress 0;
BA_ "GenSigTimeoutTime_GNMM" SG_ 156 STFAFtAlertPress 0;
BA_ "GenSigTimeoutTime_EVCU2" SG_ 156 STFAFtAlertPress 0;
BA_ "GenSigTimeoutTime_ESL" SG_ 156 STFAFtAlertPress 0;
BA_ "GenSigTimeoutTime_ECM" SG_ 156 STFAFtAlertPress 0;
BA_ "GenSigTimeoutTime_DTCM" SG_ 156 STFAFtAlertPress 0;
BA_ "GenSigTimeoutTime_DMSM" SG_ 156 STFAFtAlertPress 0;
BA_ "GenSigTimeoutTime_BSM" SG_ 156 STFAFtAlertPress 0;
BA_ "GenSigTimeoutTime_BCM" SG_ 156 STFAFtAlertPress 0;
BA_ "GenSigTimeoutTime_AGSM" SG_ 156 STFAFtAlertPress 0;
BA_ "GenSigTimeoutTime_ADCAM" SG_ 156 STFAFtAlertPress 0;
BA_ "GenSigSendType" SG_ 156 STFAFtAlertPress 3;
BA_ "GenSigTimeoutTime_SGW" SG_ 156 ParkSenseSignalView_Req 0;
BA_ "GenSigTimeoutTime_RFHM" SG_ 156 ParkSenseSignalView_Req 0;
BA_ "GenSigTimeoutTime_MPAD" SG_ 156 ParkSenseSignalView_Req 0;
BA_ "GenSigTimeoutTime_GNMM" SG_ 156 ParkSenseSignalView_Req 0;
BA_ "GenSigTimeoutTime_EVCU2" SG_ 156 ParkSenseSignalView_Req 0;
BA_ "GenSigTimeoutTime_ESL" SG_ 156 ParkSenseSignalView_Req 0;
BA_ "GenSigTimeoutTime_ECM" SG_ 156 ParkSenseSignalView_Req 0;
BA_ "GenSigTimeoutTime_DTCM" SG_ 156 ParkSenseSignalView_Req 0;
BA_ "GenSigTimeoutTime_DMSM" SG_ 156 ParkSenseSignalView_Req 0;
BA_ "GenSigTimeoutTime_BSM" SG_ 156 ParkSenseSignalView_Req 0;
BA_ "GenSigTimeoutTime_BCM" SG_ 156 ParkSenseSignalView_Req 0;
BA_ "GenSigTimeoutTime_AGSM" SG_ 156 ParkSenseSignalView_Req 0;
BA_ "GenSigTimeoutTime_ADCAM" SG_ 156 ParkSenseSignalView_Req 0;
BA_ "GenSigSendType" SG_ 156 ParkSenseSignalView_Req 4;
BA_ "GenSigTimeoutTime_SGW" SG_ 156 GPS_UTC_Second 0;
BA_ "GenSigTimeoutTime_RFHM" SG_ 156 GPS_UTC_Second 0;
BA_ "GenSigTimeoutTime_MPAD" SG_ 156 GPS_UTC_Second 0;
BA_ "GenSigTimeoutTime_IPC" SG_ 156 GPS_UTC_Second 0;
BA_ "GenSigTimeoutTime_GNMM" SG_ 156 GPS_UTC_Second 0;
BA_ "GenSigTimeoutTime_ESL" SG_ 156 GPS_UTC_Second 0;
BA_ "GenSigTimeoutTime_ECM" SG_ 156 GPS_UTC_Second 0;
BA_ "GenSigTimeoutTime_DTCM" SG_ 156 GPS_UTC_Second 0;
BA_ "GenSigTimeoutTime_BSM" SG_ 156 GPS_UTC_Second 0;
BA_ "GenSigTimeoutTime_BCM" SG_ 156 GPS_UTC_Second 0;
BA_ "GenSigTimeoutTime_AGSM" SG_ 156 GPS_UTC_Second 0;
BA_ "GenSigTimeoutTime_ADCAM" SG_ 156 GPS_UTC_Second 0;
BA_ "GenSigStartValue" SG_ 156 GPS_UTC_Second 65535;
BA_ "GenSigTimeoutTime_SGW" SG_ 156 GPS_UTC_Hour 0;
BA_ "GenSigTimeoutTime_RFHM" SG_ 156 GPS_UTC_Hour 0;
BA_ "GenSigTimeoutTime_MPAD" SG_ 156 GPS_UTC_Hour 0;
BA_ "GenSigTimeoutTime_IPC" SG_ 156 GPS_UTC_Hour 0;
BA_ "GenSigTimeoutTime_GNMM" SG_ 156 GPS_UTC_Hour 0;
BA_ "GenSigTimeoutTime_ESL" SG_ 156 GPS_UTC_Hour 0;
BA_ "GenSigTimeoutTime_ECM" SG_ 156 GPS_UTC_Hour 0;
BA_ "GenSigTimeoutTime_DTCM" SG_ 156 GPS_UTC_Hour 0;
BA_ "GenSigTimeoutTime_BSM" SG_ 156 GPS_UTC_Hour 0;
BA_ "GenSigTimeoutTime_BCM" SG_ 156 GPS_UTC_Hour 0;
BA_ "GenSigTimeoutTime_AGSM" SG_ 156 GPS_UTC_Hour 0;
BA_ "GenSigTimeoutTime_ADCAM" SG_ 156 GPS_UTC_Hour 0;
BA_ "GenSigStartValue" SG_ 156 GPS_UTC_Hour 255;
BA_ "GenSigTimeoutTime_SGW" SG_ 156 GPS_UTC_Minute 0;
BA_ "GenSigTimeoutTime_RFHM" SG_ 156 GPS_UTC_Minute 0;
BA_ "GenSigTimeoutTime_MPAD" SG_ 156 GPS_UTC_Minute 0;
BA_ "GenSigTimeoutTime_IPC" SG_ 156 GPS_UTC_Minute 0;
BA_ "GenSigTimeoutTime_GNMM" SG_ 156 GPS_UTC_Minute 0;
BA_ "GenSigTimeoutTime_ESL" SG_ 156 GPS_UTC_Minute 0;
BA_ "GenSigTimeoutTime_ECM" SG_ 156 GPS_UTC_Minute 0;
BA_ "GenSigTimeoutTime_DTCM" SG_ 156 GPS_UTC_Minute 0;
BA_ "GenSigTimeoutTime_BSM" SG_ 156 GPS_UTC_Minute 0;
BA_ "GenSigTimeoutTime_BCM" SG_ 156 GPS_UTC_Minute 0;
BA_ "GenSigTimeoutTime_AGSM" SG_ 156 GPS_UTC_Minute 0;
BA_ "GenSigTimeoutTime_ADCAM" SG_ 156 GPS_UTC_Minute 0;
BA_ "GenSigStartValue" SG_ 156 GPS_UTC_Minute 255;
BA_ "GenSigTimeoutTime_SGW" SG_ 156 GPS_Date_Month 0;
BA_ "GenSigTimeoutTime_MPAD" SG_ 156 GPS_Date_Month 0;
BA_ "GenSigTimeoutTime_IPC" SG_ 156 GPS_Date_Month 0;
BA_ "GenSigTimeoutTime_GNMM" SG_ 156 GPS_Date_Month 0;
BA_ "GenSigTimeoutTime_ESL" SG_ 156 GPS_Date_Month 0;
BA_ "GenSigTimeoutTime_ECM" SG_ 156 GPS_Date_Month 0;
BA_ "GenSigTimeoutTime_DTCM" SG_ 156 GPS_Date_Month 0;
BA_ "GenSigTimeoutTime_BSM" SG_ 156 GPS_Date_Month 0;
BA_ "GenSigTimeoutTime_BCM" SG_ 156 GPS_Date_Month 0;
BA_ "GenSigTimeoutTime_AGSM" SG_ 156 GPS_Date_Month 0;
BA_ "GenSigTimeoutTime_ADCAM" SG_ 156 GPS_Date_Month 0;
BA_ "GenSigStartValue" SG_ 156 GPS_Date_Month 255;
BA_ "GenSigTimeoutTime_BSM" SG_ 156 GPS_Date_Year 0;
BA_ "GenSigTimeoutTime_BCM" SG_ 156 GPS_Date_Year 0;
BA_ "GenSigTimeoutTime_AGSM" SG_ 156 GPS_Date_Year 0;
BA_ "GenSigTimeoutTime_ADCAM" SG_ 156 GPS_Date_Year 0;
BA_ "GenSigStartValue" SG_ 156 GPS_Date_Year 65535;
BA_ "GenSigTimeoutTime_SGW" SG_ 156 GPS_Date_Year 0;
BA_ "GenSigTimeoutTime_MPAD" SG_ 156 GPS_Date_Year 0;
BA_ "GenSigTimeoutTime_IPC" SG_ 156 GPS_Date_Year 0;
BA_ "GenSigTimeoutTime_GNMM" SG_ 156 GPS_Date_Year 0;
BA_ "GenSigTimeoutTime_ESL" SG_ 156 GPS_Date_Year 0;
BA_ "GenSigTimeoutTime_ECM" SG_ 156 GPS_Date_Year 0;
BA_ "GenSigTimeoutTime_DTCM" SG_ 156 GPS_Date_Year 0;
BA_ "GenSigTimeoutTime_SGW" SG_ 156 GPS_Date_Day 0;
BA_ "GenSigTimeoutTime_MPAD" SG_ 156 GPS_Date_Day 0;
BA_ "GenSigTimeoutTime_IPC" SG_ 156 GPS_Date_Day 0;
BA_ "GenSigTimeoutTime_GNMM" SG_ 156 GPS_Date_Day 0;
BA_ "GenSigTimeoutTime_ESL" SG_ 156 GPS_Date_Day 0;
BA_ "GenSigTimeoutTime_ECM" SG_ 156 GPS_Date_Day 0;
BA_ "GenSigTimeoutTime_DTCM" SG_ 156 GPS_Date_Day 0;
BA_ "GenSigTimeoutTime_BSM" SG_ 156 GPS_Date_Day 0;
BA_ "GenSigTimeoutTime_BCM" SG_ 156 GPS_Date_Day 0;
BA_ "GenSigTimeoutTime_AGSM" SG_ 156 GPS_Date_Day 0;
BA_ "GenSigTimeoutTime_ADCAM" SG_ 156 GPS_Date_Day 0;
BA_ "GenSigStartValue" SG_ 156 GPS_Date_Day 255;
BA_ "GenSigTimeoutTime_SGW" SG_ 156 EPB_Service_Mode_Req 0;
BA_ "GenSigTimeoutTime_RFHM" SG_ 156 EPB_Service_Mode_Req 0;
BA_ "GenSigTimeoutTime_MPAD" SG_ 156 EPB_Service_Mode_Req 0;
BA_ "GenSigTimeoutTime_GNMM" SG_ 156 EPB_Service_Mode_Req 0;
BA_ "GenSigTimeoutTime_EVCU2" SG_ 156 EPB_Service_Mode_Req 0;
BA_ "GenSigTimeoutTime_ESL" SG_ 156 EPB_Service_Mode_Req 0;
BA_ "GenSigTimeoutTime_ECM" SG_ 156 EPB_Service_Mode_Req 0;
BA_ "GenSigTimeoutTime_DTCM" SG_ 156 EPB_Service_Mode_Req 0;
BA_ "GenSigTimeoutTime_DMSM" SG_ 156 EPB_Service_Mode_Req 0;
BA_ "GenSigTimeoutTime_BSM" SG_ 156 EPB_Service_Mode_Req 0;
BA_ "GenSigTimeoutTime_BCM" SG_ 156 EPB_Service_Mode_Req 0;
BA_ "GenSigTimeoutTime_AGSM" SG_ 156 EPB_Service_Mode_Req 0;
BA_ "GenSigTimeoutTime_ADCAM" SG_ 156 EPB_Service_Mode_Req 0;
BA_ "GenSigSendType" SG_ 156 EPB_Service_Mode_Req 4;
BA_ "GenSigTimeoutTime_SGW" SG_ 156 Fuel_Saver_Display_Req 0;
BA_ "GenSigTimeoutTime_RFHM" SG_ 156 Fuel_Saver_Display_Req 0;
BA_ "GenSigTimeoutTime_MPAD" SG_ 156 Fuel_Saver_Display_Req 0;
BA_ "GenSigTimeoutTime_GNMM" SG_ 156 Fuel_Saver_Display_Req 0;
BA_ "GenSigTimeoutTime_EVCU2" SG_ 156 Fuel_Saver_Display_Req 0;
BA_ "GenSigTimeoutTime_ESL" SG_ 156 Fuel_Saver_Display_Req 0;
BA_ "GenSigTimeoutTime_ECM" SG_ 156 Fuel_Saver_Display_Req 0;
BA_ "GenSigTimeoutTime_DTCM" SG_ 156 Fuel_Saver_Display_Req 0;
BA_ "GenSigTimeoutTime_DMSM" SG_ 156 Fuel_Saver_Display_Req 0;
BA_ "GenSigTimeoutTime_BSM" SG_ 156 Fuel_Saver_Display_Req 0;
BA_ "GenSigTimeoutTime_BCM" SG_ 156 Fuel_Saver_Display_Req 0;
BA_ "GenSigTimeoutTime_AGSM" SG_ 156 Fuel_Saver_Display_Req 0;
BA_ "GenSigTimeoutTime_ADCAM" SG_ 156 Fuel_Saver_Display_Req 0;
BA_ "GenSigSendType" SG_ 156 Fuel_Saver_Display_Req 4;
BA_ "GenSigTimeoutTime_SGW" SG_ 2651930689 Digit_01_RFHM 0;
BA_ "GenSigTimeoutTime_RFHM" SG_ 2651930689 Digit_01_RFHM 0;
BA_ "GenSigTimeoutTime_MPAD" SG_ 2651930689 Digit_01_RFHM 0;
BA_ "GenSigTimeoutTime_IPC" SG_ 2651930689 Digit_01_RFHM 0;
BA_ "GenSigTimeoutTime_SGW" SG_ 2651930689 Digit_02_RFHM 0;
BA_ "GenSigTimeoutTime_RFHM" SG_ 2651930689 Digit_02_RFHM 0;
BA_ "GenSigTimeoutTime_MPAD" SG_ 2651930689 Digit_02_RFHM 0;
BA_ "GenSigTimeoutTime_IPC" SG_ 2651930689 Digit_02_RFHM 0;
BA_ "GenSigTimeoutTime_GNMM" SG_ 2651930689 Digit_02_RFHM 0;
BA_ "GenSigTimeoutTime_EVCU2" SG_ 2651930689 Digit_02_RFHM 0;
BA_ "GenSigTimeoutTime_ESL" SG_ 2651930689 Digit_02_RFHM 0;
BA_ "GenSigTimeoutTime_ECM" SG_ 2651930689 Digit_02_RFHM 0;
BA_ "GenSigTimeoutTime_DTCM" SG_ 2651930689 Digit_02_RFHM 0;
BA_ "GenSigTimeoutTime_DMSM" SG_ 2651930689 Digit_02_RFHM 0;
BA_ "GenSigTimeoutTime_BSM" SG_ 2651930689 Digit_02_RFHM 0;
BA_ "GenSigTimeoutTime_AGSM" SG_ 2651930689 Digit_02_RFHM 0;
BA_ "GenSigTimeoutTime_ADCAM" SG_ 2651930689 Digit_02_RFHM 0;
BA_ "GenSigTimeoutTime_SGW" SG_ 2651930689 Digit_03_RFHM 0;
BA_ "GenSigTimeoutTime_RFHM" SG_ 2651930689 Digit_03_RFHM 0;
BA_ "GenSigTimeoutTime_MPAD" SG_ 2651930689 Digit_03_RFHM 0;
BA_ "GenSigTimeoutTime_IPC" SG_ 2651930689 Digit_03_RFHM 0;
BA_ "GenSigTimeoutTime_GNMM" SG_ 2651930689 Digit_03_RFHM 0;
BA_ "GenSigTimeoutTime_EVCU2" SG_ 2651930689 Digit_03_RFHM 0;
BA_ "GenSigTimeoutTime_ESL" SG_ 2651930689 Digit_03_RFHM 0;
BA_ "GenSigTimeoutTime_ECM" SG_ 2651930689 Digit_03_RFHM 0;
BA_ "GenSigTimeoutTime_DTCM" SG_ 2651930689 Digit_03_RFHM 0;
BA_ "GenSigTimeoutTime_DMSM" SG_ 2651930689 Digit_03_RFHM 0;
BA_ "GenSigTimeoutTime_BSM" SG_ 2651930689 Digit_03_RFHM 0;
BA_ "GenSigTimeoutTime_AGSM" SG_ 2651930689 Digit_03_RFHM 0;
BA_ "GenSigTimeoutTime_ADCAM" SG_ 2651930689 Digit_03_RFHM 0;
BA_ "GenSigTimeoutTime_ADCAM" SG_ 2651930689 Digit_04_RFHM 0;
BA_ "GenSigTimeoutTime_SGW" SG_ 2651930689 Digit_04_RFHM 0;
BA_ "GenSigTimeoutTime_RFHM" SG_ 2651930689 Digit_04_RFHM 0;
BA_ "GenSigTimeoutTime_MPAD" SG_ 2651930689 Digit_04_RFHM 0;
BA_ "GenSigTimeoutTime_IPC" SG_ 2651930689 Digit_04_RFHM 0;
BA_ "GenSigTimeoutTime_GNMM" SG_ 2651930689 Digit_04_RFHM 0;
BA_ "GenSigTimeoutTime_EVCU2" SG_ 2651930689 Digit_04_RFHM 0;
BA_ "GenSigTimeoutTime_ESL" SG_ 2651930689 Digit_04_RFHM 0;
BA_ "GenSigTimeoutTime_ECM" SG_ 2651930689 Digit_04_RFHM 0;
BA_ "GenSigTimeoutTime_DTCM" SG_ 2651930689 Digit_04_RFHM 0;
BA_ "GenSigTimeoutTime_DMSM" SG_ 2651930689 Digit_04_RFHM 0;
BA_ "GenSigTimeoutTime_BSM" SG_ 2651930689 Digit_04_RFHM 0;
BA_ "GenSigTimeoutTime_AGSM" SG_ 2651930689 Digit_04_RFHM 0;
BA_ "GenSigTimeoutTime_SGW" SG_ 2651930689 Digit_05_RFHM 0;
BA_ "GenSigTimeoutTime_RFHM" SG_ 2651930689 Digit_05_RFHM 0;
BA_ "GenSigTimeoutTime_MPAD" SG_ 2651930689 Digit_05_RFHM 0;
BA_ "GenSigTimeoutTime_IPC" SG_ 2651930689 Digit_05_RFHM 0;
BA_ "GenSigTimeoutTime_GNMM" SG_ 2651930689 Digit_05_RFHM 0;
BA_ "GenSigTimeoutTime_EVCU2" SG_ 2651930689 Digit_05_RFHM 0;
BA_ "GenSigTimeoutTime_ESL" SG_ 2651930689 Digit_05_RFHM 0;
BA_ "GenSigTimeoutTime_ECM" SG_ 2651930689 Digit_05_RFHM 0;
BA_ "GenSigTimeoutTime_DTCM" SG_ 2651930689 Digit_05_RFHM 0;
BA_ "GenSigTimeoutTime_DMSM" SG_ 2651930689 Digit_05_RFHM 0;
BA_ "GenSigTimeoutTime_BSM" SG_ 2651930689 Digit_05_RFHM 0;
BA_ "GenSigTimeoutTime_AGSM" SG_ 2651930689 Digit_05_RFHM 0;
BA_ "GenSigTimeoutTime_ADCAM" SG_ 2651930689 Digit_05_RFHM 0;
BA_ "GenSigTimeoutTime_SGW" SG_ 2651930689 Digit_06_RFHM 0;
BA_ "GenSigTimeoutTime_RFHM" SG_ 2651930689 Digit_06_RFHM 0;
BA_ "GenSigTimeoutTime_MPAD" SG_ 2651930689 Digit_06_RFHM 0;
BA_ "GenSigTimeoutTime_IPC" SG_ 2651930689 Digit_06_RFHM 0;
BA_ "GenSigTimeoutTime_GNMM" SG_ 2651930689 Digit_06_RFHM 0;
BA_ "GenSigTimeoutTime_EVCU2" SG_ 2651930689 Digit_06_RFHM 0;
BA_ "GenSigTimeoutTime_ESL" SG_ 2651930689 Digit_06_RFHM 0;
BA_ "GenSigTimeoutTime_ECM" SG_ 2651930689 Digit_06_RFHM 0;
BA_ "GenSigTimeoutTime_DTCM" SG_ 2651930689 Digit_06_RFHM 0;
BA_ "GenSigTimeoutTime_DMSM" SG_ 2651930689 Digit_06_RFHM 0;
BA_ "GenSigTimeoutTime_BSM" SG_ 2651930689 Digit_06_RFHM 0;
BA_ "GenSigTimeoutTime_AGSM" SG_ 2651930689 Digit_06_RFHM 0;
BA_ "GenSigTimeoutTime_ADCAM" SG_ 2651930689 Digit_06_RFHM 0;
BA_ "GenSigTimeoutTime_SGW" SG_ 2651930689 Digit_07_RFHM 0;
BA_ "GenSigTimeoutTime_RFHM" SG_ 2651930689 Digit_07_RFHM 0;
BA_ "GenSigTimeoutTime_MPAD" SG_ 2651930689 Digit_07_RFHM 0;
BA_ "GenSigTimeoutTime_IPC" SG_ 2651930689 Digit_07_RFHM 0;
BA_ "GenSigTimeoutTime_GNMM" SG_ 2651930689 Digit_07_RFHM 0;
BA_ "GenSigTimeoutTime_EVCU2" SG_ 2651930689 Digit_07_RFHM 0;
BA_ "GenSigTimeoutTime_ESL" SG_ 2651930689 Digit_07_RFHM 0;
BA_ "GenSigTimeoutTime_ECM" SG_ 2651930689 Digit_07_RFHM 0;
BA_ "GenSigTimeoutTime_DTCM" SG_ 2651930689 Digit_07_RFHM 0;
BA_ "GenSigTimeoutTime_DMSM" SG_ 2651930689 Digit_07_RFHM 0;
BA_ "GenSigTimeoutTime_BSM" SG_ 2651930689 Digit_07_RFHM 0;
BA_ "GenSigTimeoutTime_AGSM" SG_ 2651930689 Digit_07_RFHM 0;
BA_ "GenSigTimeoutTime_ADCAM" SG_ 2651930689 Digit_07_RFHM 0;
BA_ "GenSigTimeoutTime_SGW" SG_ 2651930689 Digit_08_RFHM 0;
BA_ "GenSigTimeoutTime_RFHM" SG_ 2651930689 Digit_08_RFHM 0;
BA_ "GenSigTimeoutTime_MPAD" SG_ 2651930689 Digit_08_RFHM 0;
BA_ "GenSigTimeoutTime_IPC" SG_ 2651930689 Digit_08_RFHM 0;
BA_ "GenSigTimeoutTime_GNMM" SG_ 2651930689 Digit_08_RFHM 0;
BA_ "GenSigTimeoutTime_EVCU2" SG_ 2651930689 Digit_08_RFHM 0;
BA_ "GenSigTimeoutTime_ESL" SG_ 2651930689 Digit_08_RFHM 0;
BA_ "GenSigTimeoutTime_ECM" SG_ 2651930689 Digit_08_RFHM 0;
BA_ "GenSigTimeoutTime_DTCM" SG_ 2651930689 Digit_08_RFHM 0;
BA_ "GenSigTimeoutTime_DMSM" SG_ 2651930689 Digit_08_RFHM 0;
BA_ "GenSigTimeoutTime_BSM" SG_ 2651930689 Digit_08_RFHM 0;
BA_ "GenSigTimeoutTime_AGSM" SG_ 2651930689 Digit_08_RFHM 0;
BA_ "GenSigTimeoutTime_ADCAM" SG_ 2651930689 Digit_08_RFHM 0;
BA_ "GenSigTimeoutTime_SGW" SG_ 2651930689 Digit_09_RFHM 0;
BA_ "GenSigTimeoutTime_RFHM" SG_ 2651930689 Digit_09_RFHM 0;
BA_ "GenSigTimeoutTime_MPAD" SG_ 2651930689 Digit_09_RFHM 0;
BA_ "GenSigTimeoutTime_IPC" SG_ 2651930689 Digit_09_RFHM 0;
BA_ "GenSigTimeoutTime_GNMM" SG_ 2651930689 Digit_09_RFHM 0;
BA_ "GenSigTimeoutTime_EVCU2" SG_ 2651930689 Digit_09_RFHM 0;
BA_ "GenSigTimeoutTime_ESL" SG_ 2651930689 Digit_09_RFHM 0;
BA_ "GenSigTimeoutTime_ECM" SG_ 2651930689 Digit_09_RFHM 0;
BA_ "GenSigTimeoutTime_DTCM" SG_ 2651930689 Digit_09_RFHM 0;
BA_ "GenSigTimeoutTime_DMSM" SG_ 2651930689 Digit_09_RFHM 0;
BA_ "GenSigTimeoutTime_BSM" SG_ 2651930689 Digit_09_RFHM 0;
BA_ "GenSigTimeoutTime_AGSM" SG_ 2651930689 Digit_09_RFHM 0;
BA_ "GenSigTimeoutTime_ADCAM" SG_ 2651930689 Digit_09_RFHM 0;
BA_ "GenSigTimeoutTime_SGW" SG_ 2651930689 Digit_10_RFHM 0;
BA_ "GenSigTimeoutTime_RFHM" SG_ 2651930689 Digit_10_RFHM 0;
BA_ "GenSigTimeoutTime_MPAD" SG_ 2651930689 Digit_10_RFHM 0;
BA_ "GenSigTimeoutTime_IPC" SG_ 2651930689 Digit_10_RFHM 0;
BA_ "GenSigTimeoutTime_GNMM" SG_ 2651930689 Digit_10_RFHM 0;
BA_ "GenSigTimeoutTime_EVCU2" SG_ 2651930689 Digit_10_RFHM 0;
BA_ "GenSigTimeoutTime_ESL" SG_ 2651930689 Digit_10_RFHM 0;
BA_ "GenSigTimeoutTime_ECM" SG_ 2651930689 Digit_10_RFHM 0;
BA_ "GenSigTimeoutTime_DTCM" SG_ 2651930689 Digit_10_RFHM 0;
BA_ "GenSigTimeoutTime_DMSM" SG_ 2651930689 Digit_10_RFHM 0;
BA_ "GenSigTimeoutTime_BSM" SG_ 2651930689 Digit_10_RFHM 0;
BA_ "GenSigTimeoutTime_AGSM" SG_ 2651930689 Digit_10_RFHM 0;
BA_ "GenSigTimeoutTime_ADCAM" SG_ 2651930689 Digit_10_RFHM 0;
BA_ "GenSigTimeoutTime_SGW" SG_ 2651930689 Digit_11_RFHM 0;
BA_ "GenSigTimeoutTime_RFHM" SG_ 2651930689 Digit_11_RFHM 0;
BA_ "GenSigTimeoutTime_MPAD" SG_ 2651930689 Digit_11_RFHM 0;
BA_ "GenSigTimeoutTime_IPC" SG_ 2651930689 Digit_11_RFHM 0;
BA_ "GenSigTimeoutTime_GNMM" SG_ 2651930689 Digit_11_RFHM 0;
BA_ "GenSigTimeoutTime_EVCU2" SG_ 2651930689 Digit_11_RFHM 0;
BA_ "GenSigTimeoutTime_ESL" SG_ 2651930689 Digit_11_RFHM 0;
BA_ "GenSigTimeoutTime_ECM" SG_ 2651930689 Digit_11_RFHM 0;
BA_ "GenSigTimeoutTime_DTCM" SG_ 2651930689 Digit_11_RFHM 0;
BA_ "GenSigTimeoutTime_DMSM" SG_ 2651930689 Digit_11_RFHM 0;
BA_ "GenSigTimeoutTime_BSM" SG_ 2651930689 Digit_11_RFHM 0;
BA_ "GenSigTimeoutTime_AGSM" SG_ 2651930689 Digit_11_RFHM 0;
BA_ "GenSigTimeoutTime_ADCAM" SG_ 2651930689 Digit_11_RFHM 0;
BA_ "GenSigTimeoutTime_SGW" SG_ 2651930627 Digit_10_IPC 0;
BA_ "GenSigTimeoutTime_RFHM" SG_ 2651930627 Digit_10_IPC 0;
BA_ "GenSigTimeoutTime_MPAD" SG_ 2651930627 Digit_10_IPC 0;
BA_ "GenSigTimeoutTime_IPC" SG_ 2651930627 Digit_10_IPC 0;
BA_ "GenSigTimeoutTime_GNMM" SG_ 2651930627 Digit_10_IPC 0;
BA_ "GenSigTimeoutTime_EVCU2" SG_ 2651930627 Digit_10_IPC 0;
BA_ "GenSigTimeoutTime_ESL" SG_ 2651930627 Digit_10_IPC 0;
BA_ "GenSigTimeoutTime_ECM" SG_ 2651930627 Digit_10_IPC 0;
BA_ "GenSigTimeoutTime_DTCM" SG_ 2651930627 Digit_10_IPC 0;
BA_ "GenSigTimeoutTime_DMSM" SG_ 2651930627 Digit_10_IPC 0;
BA_ "GenSigTimeoutTime_BSM" SG_ 2651930627 Digit_10_IPC 0;
BA_ "GenSigTimeoutTime_AGSM" SG_ 2651930627 Digit_10_IPC 0;
BA_ "GenSigTimeoutTime_ADCAM" SG_ 2651930627 Digit_10_IPC 0;
BA_ "GenSigTimeoutTime_SGW" SG_ 2651930627 Digit_11_IPC 0;
BA_ "GenSigTimeoutTime_RFHM" SG_ 2651930627 Digit_11_IPC 0;
BA_ "GenSigTimeoutTime_MPAD" SG_ 2651930627 Digit_11_IPC 0;
BA_ "GenSigTimeoutTime_IPC" SG_ 2651930627 Digit_11_IPC 0;
BA_ "GenSigTimeoutTime_GNMM" SG_ 2651930627 Digit_11_IPC 0;
BA_ "GenSigTimeoutTime_EVCU2" SG_ 2651930627 Digit_11_IPC 0;
BA_ "GenSigTimeoutTime_ESL" SG_ 2651930627 Digit_11_IPC 0;
BA_ "GenSigTimeoutTime_ECM" SG_ 2651930627 Digit_11_IPC 0;
BA_ "GenSigTimeoutTime_DTCM" SG_ 2651930627 Digit_11_IPC 0;
BA_ "GenSigTimeoutTime_DMSM" SG_ 2651930627 Digit_11_IPC 0;
BA_ "GenSigTimeoutTime_BSM" SG_ 2651930627 Digit_11_IPC 0;
BA_ "GenSigTimeoutTime_AGSM" SG_ 2651930627 Digit_11_IPC 0;
BA_ "GenSigTimeoutTime_ADCAM" SG_ 2651930627 Digit_11_IPC 0;
BA_ "GenSigTimeoutTime_SGW" SG_ 2651930627 Digit_06_IPC 0;
BA_ "GenSigTimeoutTime_RFHM" SG_ 2651930627 Digit_06_IPC 0;
BA_ "GenSigTimeoutTime_MPAD" SG_ 2651930627 Digit_06_IPC 0;
BA_ "GenSigTimeoutTime_IPC" SG_ 2651930627 Digit_06_IPC 0;
BA_ "GenSigTimeoutTime_GNMM" SG_ 2651930627 Digit_06_IPC 0;
BA_ "GenSigTimeoutTime_EVCU2" SG_ 2651930627 Digit_06_IPC 0;
BA_ "GenSigTimeoutTime_ESL" SG_ 2651930627 Digit_06_IPC 0;
BA_ "GenSigTimeoutTime_ECM" SG_ 2651930627 Digit_06_IPC 0;
BA_ "GenSigTimeoutTime_DTCM" SG_ 2651930627 Digit_06_IPC 0;
BA_ "GenSigTimeoutTime_DMSM" SG_ 2651930627 Digit_06_IPC 0;
BA_ "GenSigTimeoutTime_BSM" SG_ 2651930627 Digit_06_IPC 0;
BA_ "GenSigTimeoutTime_AGSM" SG_ 2651930627 Digit_06_IPC 0;
BA_ "GenSigTimeoutTime_ADCAM" SG_ 2651930627 Digit_06_IPC 0;
BA_ "GenSigTimeoutTime_SGW" SG_ 2651930627 Digit_07_IPC 0;
BA_ "GenSigTimeoutTime_RFHM" SG_ 2651930627 Digit_07_IPC 0;
BA_ "GenSigTimeoutTime_MPAD" SG_ 2651930627 Digit_07_IPC 0;
BA_ "GenSigTimeoutTime_IPC" SG_ 2651930627 Digit_07_IPC 0;
BA_ "GenSigTimeoutTime_GNMM" SG_ 2651930627 Digit_07_IPC 0;
BA_ "GenSigTimeoutTime_EVCU2" SG_ 2651930627 Digit_07_IPC 0;
BA_ "GenSigTimeoutTime_ESL" SG_ 2651930627 Digit_07_IPC 0;
BA_ "GenSigTimeoutTime_ECM" SG_ 2651930627 Digit_07_IPC 0;
BA_ "GenSigTimeoutTime_DTCM" SG_ 2651930627 Digit_07_IPC 0;
BA_ "GenSigTimeoutTime_DMSM" SG_ 2651930627 Digit_07_IPC 0;
BA_ "GenSigTimeoutTime_BSM" SG_ 2651930627 Digit_07_IPC 0;
BA_ "GenSigTimeoutTime_AGSM" SG_ 2651930627 Digit_07_IPC 0;
BA_ "GenSigTimeoutTime_ADCAM" SG_ 2651930627 Digit_07_IPC 0;
BA_ "GenSigTimeoutTime_SGW" SG_ 2651930627 Digit_08_IPC 0;
BA_ "GenSigTimeoutTime_RFHM" SG_ 2651930627 Digit_08_IPC 0;
BA_ "GenSigTimeoutTime_MPAD" SG_ 2651930627 Digit_08_IPC 0;
BA_ "GenSigTimeoutTime_IPC" SG_ 2651930627 Digit_08_IPC 0;
BA_ "GenSigTimeoutTime_GNMM" SG_ 2651930627 Digit_08_IPC 0;
BA_ "GenSigTimeoutTime_EVCU2" SG_ 2651930627 Digit_08_IPC 0;
BA_ "GenSigTimeoutTime_ESL" SG_ 2651930627 Digit_08_IPC 0;
BA_ "GenSigTimeoutTime_ECM" SG_ 2651930627 Digit_08_IPC 0;
BA_ "GenSigTimeoutTime_DTCM" SG_ 2651930627 Digit_08_IPC 0;
BA_ "GenSigTimeoutTime_DMSM" SG_ 2651930627 Digit_08_IPC 0;
BA_ "GenSigTimeoutTime_BSM" SG_ 2651930627 Digit_08_IPC 0;
BA_ "GenSigTimeoutTime_AGSM" SG_ 2651930627 Digit_08_IPC 0;
BA_ "GenSigTimeoutTime_ADCAM" SG_ 2651930627 Digit_08_IPC 0;
BA_ "GenSigTimeoutTime_SGW" SG_ 2651930627 Digit_09_IPC 0;
BA_ "GenSigTimeoutTime_RFHM" SG_ 2651930627 Digit_09_IPC 0;
BA_ "GenSigTimeoutTime_MPAD" SG_ 2651930627 Digit_09_IPC 0;
BA_ "GenSigTimeoutTime_IPC" SG_ 2651930627 Digit_09_IPC 0;
BA_ "GenSigTimeoutTime_GNMM" SG_ 2651930627 Digit_09_IPC 0;
BA_ "GenSigTimeoutTime_EVCU2" SG_ 2651930627 Digit_09_IPC 0;
BA_ "GenSigTimeoutTime_ESL" SG_ 2651930627 Digit_09_IPC 0;
BA_ "GenSigTimeoutTime_ECM" SG_ 2651930627 Digit_09_IPC 0;
BA_ "GenSigTimeoutTime_DTCM" SG_ 2651930627 Digit_09_IPC 0;
BA_ "GenSigTimeoutTime_DMSM" SG_ 2651930627 Digit_09_IPC 0;
BA_ "GenSigTimeoutTime_BSM" SG_ 2651930627 Digit_09_IPC 0;
BA_ "GenSigTimeoutTime_AGSM" SG_ 2651930627 Digit_09_IPC 0;
BA_ "GenSigTimeoutTime_ADCAM" SG_ 2651930627 Digit_09_IPC 0;
BA_ "GenSigTimeoutTime_SGW" SG_ 2651930627 Digit_01_IPC 0;
BA_ "GenSigTimeoutTime_RFHM" SG_ 2651930627 Digit_01_IPC 0;
BA_ "GenSigTimeoutTime_MPAD" SG_ 2651930627 Digit_01_IPC 0;
BA_ "GenSigTimeoutTime_IPC" SG_ 2651930627 Digit_01_IPC 0;
BA_ "GenSigTimeoutTime_GNMM" SG_ 2651930627 Digit_01_IPC 0;
BA_ "GenSigTimeoutTime_EVCU2" SG_ 2651930627 Digit_01_IPC 0;
BA_ "GenSigTimeoutTime_ESL" SG_ 2651930627 Digit_01_IPC 0;
BA_ "GenSigTimeoutTime_ECM" SG_ 2651930627 Digit_01_IPC 0;
BA_ "GenSigTimeoutTime_DTCM" SG_ 2651930627 Digit_01_IPC 0;
BA_ "GenSigTimeoutTime_DMSM" SG_ 2651930627 Digit_01_IPC 0;
BA_ "GenSigTimeoutTime_BSM" SG_ 2651930627 Digit_01_IPC 0;
BA_ "GenSigTimeoutTime_AGSM" SG_ 2651930627 Digit_01_IPC 0;
BA_ "GenSigTimeoutTime_ADCAM" SG_ 2651930627 Digit_01_IPC 0;
BA_ "GenSigSendType" SG_ 2651930627 Digit_01_IPC 1;
BA_ "GenSigTimeoutTime_SGW" SG_ 2651930627 Digit_02_IPC 0;
BA_ "GenSigTimeoutTime_RFHM" SG_ 2651930627 Digit_02_IPC 0;
BA_ "GenSigTimeoutTime_MPAD" SG_ 2651930627 Digit_02_IPC 0;
BA_ "GenSigTimeoutTime_IPC" SG_ 2651930627 Digit_02_IPC 0;
BA_ "GenSigTimeoutTime_GNMM" SG_ 2651930627 Digit_02_IPC 0;
BA_ "GenSigTimeoutTime_EVCU2" SG_ 2651930627 Digit_02_IPC 0;
BA_ "GenSigTimeoutTime_ESL" SG_ 2651930627 Digit_02_IPC 0;
BA_ "GenSigTimeoutTime_ECM" SG_ 2651930627 Digit_02_IPC 0;
BA_ "GenSigTimeoutTime_DTCM" SG_ 2651930627 Digit_02_IPC 0;
BA_ "GenSigTimeoutTime_DMSM" SG_ 2651930627 Digit_02_IPC 0;
BA_ "GenSigTimeoutTime_BSM" SG_ 2651930627 Digit_02_IPC 0;
BA_ "GenSigTimeoutTime_AGSM" SG_ 2651930627 Digit_02_IPC 0;
BA_ "GenSigTimeoutTime_ADCAM" SG_ 2651930627 Digit_02_IPC 0;
BA_ "GenSigTimeoutTime_SGW" SG_ 2651930627 Digit_03_IPC 0;
BA_ "GenSigTimeoutTime_RFHM" SG_ 2651930627 Digit_03_IPC 0;
BA_ "GenSigTimeoutTime_MPAD" SG_ 2651930627 Digit_03_IPC 0;
BA_ "GenSigTimeoutTime_IPC" SG_ 2651930627 Digit_03_IPC 0;
BA_ "GenSigTimeoutTime_GNMM" SG_ 2651930627 Digit_03_IPC 0;
BA_ "GenSigTimeoutTime_EVCU2" SG_ 2651930627 Digit_03_IPC 0;
BA_ "GenSigTimeoutTime_ESL" SG_ 2651930627 Digit_03_IPC 0;
BA_ "GenSigTimeoutTime_ECM" SG_ 2651930627 Digit_03_IPC 0;
BA_ "GenSigTimeoutTime_DTCM" SG_ 2651930627 Digit_03_IPC 0;
BA_ "GenSigTimeoutTime_DMSM" SG_ 2651930627 Digit_03_IPC 0;
BA_ "GenSigTimeoutTime_BSM" SG_ 2651930627 Digit_03_IPC 0;
BA_ "GenSigTimeoutTime_AGSM" SG_ 2651930627 Digit_03_IPC 0;
BA_ "GenSigTimeoutTime_ADCAM" SG_ 2651930627 Digit_03_IPC 0;
BA_ "GenSigTimeoutTime_SGW" SG_ 2651930627 Digit_04_IPC 0;
BA_ "GenSigTimeoutTime_RFHM" SG_ 2651930627 Digit_04_IPC 0;
BA_ "GenSigTimeoutTime_MPAD" SG_ 2651930627 Digit_04_IPC 0;
BA_ "GenSigTimeoutTime_IPC" SG_ 2651930627 Digit_04_IPC 0;
BA_ "GenSigTimeoutTime_GNMM" SG_ 2651930627 Digit_04_IPC 0;
BA_ "GenSigTimeoutTime_EVCU2" SG_ 2651930627 Digit_04_IPC 0;
BA_ "GenSigTimeoutTime_ESL" SG_ 2651930627 Digit_04_IPC 0;
BA_ "GenSigTimeoutTime_ECM" SG_ 2651930627 Digit_04_IPC 0;
BA_ "GenSigTimeoutTime_DTCM" SG_ 2651930627 Digit_04_IPC 0;
BA_ "GenSigTimeoutTime_DMSM" SG_ 2651930627 Digit_04_IPC 0;
BA_ "GenSigTimeoutTime_BSM" SG_ 2651930627 Digit_04_IPC 0;
BA_ "GenSigTimeoutTime_AGSM" SG_ 2651930627 Digit_04_IPC 0;
BA_ "GenSigTimeoutTime_ADCAM" SG_ 2651930627 Digit_04_IPC 0;
BA_ "GenSigTimeoutTime_SGW" SG_ 2651930627 Digit_05_IPC 0;
BA_ "GenSigTimeoutTime_RFHM" SG_ 2651930627 Digit_05_IPC 0;
BA_ "GenSigTimeoutTime_MPAD" SG_ 2651930627 Digit_05_IPC 0;
BA_ "GenSigTimeoutTime_IPC" SG_ 2651930627 Digit_05_IPC 0;
BA_ "GenSigTimeoutTime_GNMM" SG_ 2651930627 Digit_05_IPC 0;
BA_ "GenSigTimeoutTime_EVCU2" SG_ 2651930627 Digit_05_IPC 0;
BA_ "GenSigTimeoutTime_ESL" SG_ 2651930627 Digit_05_IPC 0;
BA_ "GenSigTimeoutTime_ECM" SG_ 2651930627 Digit_05_IPC 0;
BA_ "GenSigTimeoutTime_DTCM" SG_ 2651930627 Digit_05_IPC 0;
BA_ "GenSigTimeoutTime_DMSM" SG_ 2651930627 Digit_05_IPC 0;
BA_ "GenSigTimeoutTime_BSM" SG_ 2651930627 Digit_05_IPC 0;
BA_ "GenSigTimeoutTime_AGSM" SG_ 2651930627 Digit_05_IPC 0;
BA_ "GenSigTimeoutTime_ADCAM" SG_ 2651930627 Digit_05_IPC 0;
BA_ "GenSigTimeoutTime_SGW" SG_ 2651930645 Digit_11_ESL 0;
BA_ "GenSigTimeoutTime_RFHM" SG_ 2651930645 Digit_11_ESL 0;
BA_ "GenSigTimeoutTime_MPAD" SG_ 2651930645 Digit_11_ESL 0;
BA_ "GenSigTimeoutTime_IPC" SG_ 2651930645 Digit_11_ESL 0;
BA_ "GenSigTimeoutTime_SGW" SG_ 2651930660 Digit_01_ETM 0;
BA_ "GenSigTimeoutTime_RFHM" SG_ 2651930660 Digit_01_ETM 0;
BA_ "GenSigTimeoutTime_MPAD" SG_ 2651930660 Digit_01_ETM 0;
BA_ "GenSigTimeoutTime_IPC" SG_ 2651930660 Digit_01_ETM 0;
BA_ "GenSigTimeoutTime_GNMM" SG_ 2651930660 Digit_01_ETM 0;
BA_ "GenSigTimeoutTime_EVCU2" SG_ 2651930660 Digit_01_ETM 0;
BA_ "GenSigTimeoutTime_ESL" SG_ 2651930660 Digit_01_ETM 0;
BA_ "GenSigTimeoutTime_ECM" SG_ 2651930660 Digit_01_ETM 0;
BA_ "GenSigTimeoutTime_DTCM" SG_ 2651930660 Digit_01_ETM 0;
BA_ "GenSigTimeoutTime_DMSM" SG_ 2651930660 Digit_01_ETM 0;
BA_ "GenSigTimeoutTime_BSM" SG_ 2651930660 Digit_01_ETM 0;
BA_ "GenSigTimeoutTime_AGSM" SG_ 2651930660 Digit_01_ETM 0;
BA_ "GenSigTimeoutTime_ADCAM" SG_ 2651930660 Digit_01_ETM 0;
BA_ "GenSigSendType" SG_ 2651930660 Digit_01_ETM 1;
BA_ "GenSigTimeoutTime_SGW" SG_ 2651930660 Digit_02_ETM 0;
BA_ "GenSigTimeoutTime_RFHM" SG_ 2651930660 Digit_02_ETM 0;
BA_ "GenSigTimeoutTime_MPAD" SG_ 2651930660 Digit_02_ETM 0;
BA_ "GenSigTimeoutTime_IPC" SG_ 2651930660 Digit_02_ETM 0;
BA_ "GenSigTimeoutTime_GNMM" SG_ 2651930660 Digit_02_ETM 0;
BA_ "GenSigTimeoutTime_EVCU2" SG_ 2651930660 Digit_02_ETM 0;
BA_ "GenSigTimeoutTime_ESL" SG_ 2651930660 Digit_02_ETM 0;
BA_ "GenSigTimeoutTime_ECM" SG_ 2651930660 Digit_02_ETM 0;
BA_ "GenSigTimeoutTime_DTCM" SG_ 2651930660 Digit_02_ETM 0;
BA_ "GenSigTimeoutTime_DMSM" SG_ 2651930660 Digit_02_ETM 0;
BA_ "GenSigTimeoutTime_BSM" SG_ 2651930660 Digit_02_ETM 0;
BA_ "GenSigTimeoutTime_AGSM" SG_ 2651930660 Digit_02_ETM 0;
BA_ "GenSigTimeoutTime_ADCAM" SG_ 2651930660 Digit_02_ETM 0;
BA_ "GenSigTimeoutTime_ADCAM" SG_ 2651930660 Digit_03_ETM 0;
BA_ "GenSigTimeoutTime_SGW" SG_ 2651930660 Digit_03_ETM 0;
BA_ "GenSigTimeoutTime_RFHM" SG_ 2651930660 Digit_03_ETM 0;
BA_ "GenSigTimeoutTime_MPAD" SG_ 2651930660 Digit_03_ETM 0;
BA_ "GenSigTimeoutTime_IPC" SG_ 2651930660 Digit_03_ETM 0;
BA_ "GenSigTimeoutTime_GNMM" SG_ 2651930660 Digit_03_ETM 0;
BA_ "GenSigTimeoutTime_EVCU2" SG_ 2651930660 Digit_03_ETM 0;
BA_ "GenSigTimeoutTime_ESL" SG_ 2651930660 Digit_03_ETM 0;
BA_ "GenSigTimeoutTime_ECM" SG_ 2651930660 Digit_03_ETM 0;
BA_ "GenSigTimeoutTime_DTCM" SG_ 2651930660 Digit_03_ETM 0;
BA_ "GenSigTimeoutTime_DMSM" SG_ 2651930660 Digit_03_ETM 0;
BA_ "GenSigTimeoutTime_BSM" SG_ 2651930660 Digit_03_ETM 0;
BA_ "GenSigTimeoutTime_AGSM" SG_ 2651930660 Digit_03_ETM 0;
BA_ "GenSigTimeoutTime_SGW" SG_ 2651930660 Digit_04_ETM 0;
BA_ "GenSigTimeoutTime_RFHM" SG_ 2651930660 Digit_04_ETM 0;
BA_ "GenSigTimeoutTime_MPAD" SG_ 2651930660 Digit_04_ETM 0;
BA_ "GenSigTimeoutTime_IPC" SG_ 2651930660 Digit_04_ETM 0;
BA_ "GenSigTimeoutTime_GNMM" SG_ 2651930660 Digit_04_ETM 0;
BA_ "GenSigTimeoutTime_EVCU2" SG_ 2651930660 Digit_04_ETM 0;
BA_ "GenSigTimeoutTime_ESL" SG_ 2651930660 Digit_04_ETM 0;
BA_ "GenSigTimeoutTime_ECM" SG_ 2651930660 Digit_04_ETM 0;
BA_ "GenSigTimeoutTime_DTCM" SG_ 2651930660 Digit_04_ETM 0;
BA_ "GenSigTimeoutTime_DMSM" SG_ 2651930660 Digit_04_ETM 0;
BA_ "GenSigTimeoutTime_BSM" SG_ 2651930660 Digit_04_ETM 0;
BA_ "GenSigTimeoutTime_AGSM" SG_ 2651930660 Digit_04_ETM 0;
BA_ "GenSigTimeoutTime_ADCAM" SG_ 2651930660 Digit_04_ETM 0;
BA_ "GenSigTimeoutTime_SGW" SG_ 2651930660 Digit_05_ETM 0;
BA_ "GenSigTimeoutTime_RFHM" SG_ 2651930660 Digit_05_ETM 0;
BA_ "GenSigTimeoutTime_MPAD" SG_ 2651930660 Digit_05_ETM 0;
BA_ "GenSigTimeoutTime_IPC" SG_ 2651930660 Digit_05_ETM 0;
BA_ "GenSigTimeoutTime_GNMM" SG_ 2651930660 Digit_05_ETM 0;
BA_ "GenSigTimeoutTime_EVCU2" SG_ 2651930660 Digit_05_ETM 0;
BA_ "GenSigTimeoutTime_ESL" SG_ 2651930660 Digit_05_ETM 0;
BA_ "GenSigTimeoutTime_ECM" SG_ 2651930660 Digit_05_ETM 0;
BA_ "GenSigTimeoutTime_DTCM" SG_ 2651930660 Digit_05_ETM 0;
BA_ "GenSigTimeoutTime_DMSM" SG_ 2651930660 Digit_05_ETM 0;
BA_ "GenSigTimeoutTime_BSM" SG_ 2651930660 Digit_05_ETM 0;
BA_ "GenSigTimeoutTime_AGSM" SG_ 2651930660 Digit_05_ETM 0;
BA_ "GenSigTimeoutTime_ADCAM" SG_ 2651930660 Digit_05_ETM 0;
BA_ "GenSigTimeoutTime_SGW" SG_ 2651930660 Digit_10_ETM 0;
BA_ "GenSigTimeoutTime_RFHM" SG_ 2651930660 Digit_10_ETM 0;
BA_ "GenSigTimeoutTime_MPAD" SG_ 2651930660 Digit_10_ETM 0;
BA_ "GenSigTimeoutTime_IPC" SG_ 2651930660 Digit_10_ETM 0;
BA_ "GenSigTimeoutTime_GNMM" SG_ 2651930660 Digit_10_ETM 0;
BA_ "GenSigTimeoutTime_EVCU2" SG_ 2651930660 Digit_10_ETM 0;
BA_ "GenSigTimeoutTime_ESL" SG_ 2651930660 Digit_10_ETM 0;
BA_ "GenSigTimeoutTime_ECM" SG_ 2651930660 Digit_10_ETM 0;
BA_ "GenSigTimeoutTime_DTCM" SG_ 2651930660 Digit_10_ETM 0;
BA_ "GenSigTimeoutTime_DMSM" SG_ 2651930660 Digit_10_ETM 0;
BA_ "GenSigTimeoutTime_BSM" SG_ 2651930660 Digit_10_ETM 0;
BA_ "GenSigTimeoutTime_AGSM" SG_ 2651930660 Digit_10_ETM 0;
BA_ "GenSigTimeoutTime_ADCAM" SG_ 2651930660 Digit_10_ETM 0;
BA_ "GenSigTimeoutTime_SGW" SG_ 2651930660 Digit_11_ETM 0;
BA_ "GenSigTimeoutTime_RFHM" SG_ 2651930660 Digit_11_ETM 0;
BA_ "GenSigTimeoutTime_MPAD" SG_ 2651930660 Digit_11_ETM 0;
BA_ "GenSigTimeoutTime_IPC" SG_ 2651930660 Digit_11_ETM 0;
BA_ "GenSigTimeoutTime_GNMM" SG_ 2651930660 Digit_11_ETM 0;
BA_ "GenSigTimeoutTime_EVCU2" SG_ 2651930660 Digit_11_ETM 0;
BA_ "GenSigTimeoutTime_ESL" SG_ 2651930660 Digit_11_ETM 0;
BA_ "GenSigTimeoutTime_ECM" SG_ 2651930660 Digit_11_ETM 0;
BA_ "GenSigTimeoutTime_DTCM" SG_ 2651930660 Digit_11_ETM 0;
BA_ "GenSigTimeoutTime_DMSM" SG_ 2651930660 Digit_11_ETM 0;
BA_ "GenSigTimeoutTime_BSM" SG_ 2651930660 Digit_11_ETM 0;
BA_ "GenSigTimeoutTime_AGSM" SG_ 2651930660 Digit_11_ETM 0;
BA_ "GenSigTimeoutTime_ADCAM" SG_ 2651930660 Digit_11_ETM 0;
BA_ "GenSigTimeoutTime_SGW" SG_ 2651930660 Digit_06_ETM 0;
BA_ "GenSigTimeoutTime_RFHM" SG_ 2651930660 Digit_06_ETM 0;
BA_ "GenSigTimeoutTime_MPAD" SG_ 2651930660 Digit_06_ETM 0;
BA_ "GenSigTimeoutTime_IPC" SG_ 2651930660 Digit_06_ETM 0;
BA_ "GenSigTimeoutTime_GNMM" SG_ 2651930660 Digit_06_ETM 0;
BA_ "GenSigTimeoutTime_EVCU2" SG_ 2651930660 Digit_06_ETM 0;
BA_ "GenSigTimeoutTime_ESL" SG_ 2651930660 Digit_06_ETM 0;
BA_ "GenSigTimeoutTime_ECM" SG_ 2651930660 Digit_06_ETM 0;
BA_ "GenSigTimeoutTime_DTCM" SG_ 2651930660 Digit_06_ETM 0;
BA_ "GenSigTimeoutTime_DMSM" SG_ 2651930660 Digit_06_ETM 0;
BA_ "GenSigTimeoutTime_BSM" SG_ 2651930660 Digit_06_ETM 0;
BA_ "GenSigTimeoutTime_AGSM" SG_ 2651930660 Digit_06_ETM 0;
BA_ "GenSigTimeoutTime_ADCAM" SG_ 2651930660 Digit_06_ETM 0;
BA_ "GenSigTimeoutTime_SGW" SG_ 2651930660 Digit_07_ETM 0;
BA_ "GenSigTimeoutTime_RFHM" SG_ 2651930660 Digit_07_ETM 0;
BA_ "GenSigTimeoutTime_MPAD" SG_ 2651930660 Digit_07_ETM 0;
BA_ "GenSigTimeoutTime_IPC" SG_ 2651930660 Digit_07_ETM 0;
BA_ "GenSigTimeoutTime_GNMM" SG_ 2651930660 Digit_07_ETM 0;
BA_ "GenSigTimeoutTime_EVCU2" SG_ 2651930660 Digit_07_ETM 0;
BA_ "GenSigTimeoutTime_ESL" SG_ 2651930660 Digit_07_ETM 0;
BA_ "GenSigTimeoutTime_ECM" SG_ 2651930660 Digit_07_ETM 0;
BA_ "GenSigTimeoutTime_DTCM" SG_ 2651930660 Digit_07_ETM 0;
BA_ "GenSigTimeoutTime_DMSM" SG_ 2651930660 Digit_07_ETM 0;
BA_ "GenSigTimeoutTime_BSM" SG_ 2651930660 Digit_07_ETM 0;
BA_ "GenSigTimeoutTime_AGSM" SG_ 2651930660 Digit_07_ETM 0;
BA_ "GenSigTimeoutTime_ADCAM" SG_ 2651930660 Digit_07_ETM 0;
BA_ "GenSigTimeoutTime_SGW" SG_ 2651930660 Digit_08_ETM 0;
BA_ "GenSigTimeoutTime_RFHM" SG_ 2651930660 Digit_08_ETM 0;
BA_ "GenSigTimeoutTime_MPAD" SG_ 2651930660 Digit_08_ETM 0;
BA_ "GenSigTimeoutTime_IPC" SG_ 2651930660 Digit_08_ETM 0;
BA_ "GenSigTimeoutTime_GNMM" SG_ 2651930660 Digit_08_ETM 0;
BA_ "GenSigTimeoutTime_EVCU2" SG_ 2651930660 Digit_08_ETM 0;
BA_ "GenSigTimeoutTime_ESL" SG_ 2651930660 Digit_08_ETM 0;
BA_ "GenSigTimeoutTime_ECM" SG_ 2651930660 Digit_08_ETM 0;
BA_ "GenSigTimeoutTime_DTCM" SG_ 2651930660 Digit_08_ETM 0;
BA_ "GenSigTimeoutTime_DMSM" SG_ 2651930660 Digit_08_ETM 0;
BA_ "GenSigTimeoutTime_BSM" SG_ 2651930660 Digit_08_ETM 0;
BA_ "GenSigTimeoutTime_AGSM" SG_ 2651930660 Digit_08_ETM 0;
BA_ "GenSigTimeoutTime_ADCAM" SG_ 2651930660 Digit_08_ETM 0;
BA_ "GenSigTimeoutTime_SGW" SG_ 2651930660 Digit_09_ETM 0;
BA_ "GenSigTimeoutTime_RFHM" SG_ 2651930660 Digit_09_ETM 0;
BA_ "GenSigTimeoutTime_MPAD" SG_ 2651930660 Digit_09_ETM 0;
BA_ "GenSigTimeoutTime_IPC" SG_ 2651930660 Digit_09_ETM 0;
BA_ "GenSigTimeoutTime_GNMM" SG_ 2651930660 Digit_09_ETM 0;
BA_ "GenSigTimeoutTime_EVCU2" SG_ 2651930660 Digit_09_ETM 0;
BA_ "GenSigTimeoutTime_ESL" SG_ 2651930660 Digit_09_ETM 0;
BA_ "GenSigTimeoutTime_ECM" SG_ 2651930660 Digit_09_ETM 0;
BA_ "GenSigTimeoutTime_DTCM" SG_ 2651930660 Digit_09_ETM 0;
BA_ "GenSigTimeoutTime_DMSM" SG_ 2651930660 Digit_09_ETM 0;
BA_ "GenSigTimeoutTime_BSM" SG_ 2651930660 Digit_09_ETM 0;
BA_ "GenSigTimeoutTime_AGSM" SG_ 2651930660 Digit_09_ETM 0;
BA_ "GenSigTimeoutTime_ADCAM" SG_ 2651930660 Digit_09_ETM 0;
BA_ "GenSigTimeoutTime_GNMM" SG_ 2651930645 Digit_11_ESL 0;
BA_ "GenSigTimeoutTime_EVCU2" SG_ 2651930645 Digit_11_ESL 0;
BA_ "GenSigTimeoutTime_ESL" SG_ 2651930645 Digit_11_ESL 0;
BA_ "GenSigTimeoutTime_ECM" SG_ 2651930645 Digit_11_ESL 0;
BA_ "GenSigTimeoutTime_DTCM" SG_ 2651930645 Digit_11_ESL 0;
BA_ "GenSigTimeoutTime_DMSM" SG_ 2651930645 Digit_11_ESL 0;
BA_ "GenSigTimeoutTime_BSM" SG_ 2651930645 Digit_11_ESL 0;
BA_ "GenSigTimeoutTime_AGSM" SG_ 2651930645 Digit_11_ESL 0;
BA_ "GenSigTimeoutTime_ADCAM" SG_ 2651930645 Digit_11_ESL 0;
BA_ "GenSigTimeoutTime_SGW" SG_ 2651930645 Digit_10_ESL 0;
BA_ "GenSigTimeoutTime_RFHM" SG_ 2651930645 Digit_10_ESL 0;
BA_ "GenSigTimeoutTime_MPAD" SG_ 2651930645 Digit_10_ESL 0;
BA_ "GenSigTimeoutTime_IPC" SG_ 2651930645 Digit_10_ESL 0;
BA_ "GenSigTimeoutTime_GNMM" SG_ 2651930645 Digit_10_ESL 0;
BA_ "GenSigTimeoutTime_EVCU2" SG_ 2651930645 Digit_10_ESL 0;
BA_ "GenSigTimeoutTime_ESL" SG_ 2651930645 Digit_10_ESL 0;
BA_ "GenSigTimeoutTime_ECM" SG_ 2651930645 Digit_10_ESL 0;
BA_ "GenSigTimeoutTime_DTCM" SG_ 2651930645 Digit_10_ESL 0;
BA_ "GenSigTimeoutTime_DMSM" SG_ 2651930645 Digit_10_ESL 0;
BA_ "GenSigTimeoutTime_BSM" SG_ 2651930645 Digit_10_ESL 0;
BA_ "GenSigTimeoutTime_AGSM" SG_ 2651930645 Digit_10_ESL 0;
BA_ "GenSigTimeoutTime_ADCAM" SG_ 2651930645 Digit_10_ESL 0;
BA_ "GenSigTimeoutTime_SGW" SG_ 2651930645 Digit_08_ESL 0;
BA_ "GenSigTimeoutTime_RFHM" SG_ 2651930645 Digit_08_ESL 0;
BA_ "GenSigTimeoutTime_MPAD" SG_ 2651930645 Digit_08_ESL 0;
BA_ "GenSigTimeoutTime_IPC" SG_ 2651930645 Digit_08_ESL 0;
BA_ "GenSigTimeoutTime_GNMM" SG_ 2651930645 Digit_08_ESL 0;
BA_ "GenSigTimeoutTime_EVCU2" SG_ 2651930645 Digit_08_ESL 0;
BA_ "GenSigTimeoutTime_ESL" SG_ 2651930645 Digit_08_ESL 0;
BA_ "GenSigTimeoutTime_ECM" SG_ 2651930645 Digit_08_ESL 0;
BA_ "GenSigTimeoutTime_DTCM" SG_ 2651930645 Digit_08_ESL 0;
BA_ "GenSigTimeoutTime_DMSM" SG_ 2651930645 Digit_08_ESL 0;
BA_ "GenSigTimeoutTime_BSM" SG_ 2651930645 Digit_08_ESL 0;
BA_ "GenSigTimeoutTime_AGSM" SG_ 2651930645 Digit_08_ESL 0;
BA_ "GenSigTimeoutTime_ADCAM" SG_ 2651930645 Digit_08_ESL 0;
BA_ "GenSigTimeoutTime_SGW" SG_ 2651930645 Digit_09_ESL 0;
BA_ "GenSigTimeoutTime_RFHM" SG_ 2651930645 Digit_09_ESL 0;
BA_ "GenSigTimeoutTime_MPAD" SG_ 2651930645 Digit_09_ESL 0;
BA_ "GenSigTimeoutTime_IPC" SG_ 2651930645 Digit_09_ESL 0;
BA_ "GenSigTimeoutTime_GNMM" SG_ 2651930645 Digit_09_ESL 0;
BA_ "GenSigTimeoutTime_EVCU2" SG_ 2651930645 Digit_09_ESL 0;
BA_ "GenSigTimeoutTime_ESL" SG_ 2651930645 Digit_09_ESL 0;
BA_ "GenSigTimeoutTime_ECM" SG_ 2651930645 Digit_09_ESL 0;
BA_ "GenSigTimeoutTime_DTCM" SG_ 2651930645 Digit_09_ESL 0;
BA_ "GenSigTimeoutTime_DMSM" SG_ 2651930645 Digit_09_ESL 0;
BA_ "GenSigTimeoutTime_BSM" SG_ 2651930645 Digit_09_ESL 0;
BA_ "GenSigTimeoutTime_AGSM" SG_ 2651930645 Digit_09_ESL 0;
BA_ "GenSigTimeoutTime_ADCAM" SG_ 2651930645 Digit_09_ESL 0;
BA_ "GenSigTimeoutTime_SGW" SG_ 2651930645 Digit_04_ESL 0;
BA_ "GenSigTimeoutTime_RFHM" SG_ 2651930645 Digit_04_ESL 0;
BA_ "GenSigTimeoutTime_MPAD" SG_ 2651930645 Digit_04_ESL 0;
BA_ "GenSigTimeoutTime_IPC" SG_ 2651930645 Digit_04_ESL 0;
BA_ "GenSigTimeoutTime_GNMM" SG_ 2651930645 Digit_04_ESL 0;
BA_ "GenSigTimeoutTime_EVCU2" SG_ 2651930645 Digit_04_ESL 0;
BA_ "GenSigTimeoutTime_ESL" SG_ 2651930645 Digit_04_ESL 0;
BA_ "GenSigTimeoutTime_ECM" SG_ 2651930645 Digit_04_ESL 0;
BA_ "GenSigTimeoutTime_DTCM" SG_ 2651930645 Digit_04_ESL 0;
BA_ "GenSigTimeoutTime_DMSM" SG_ 2651930645 Digit_04_ESL 0;
BA_ "GenSigTimeoutTime_BSM" SG_ 2651930645 Digit_04_ESL 0;
BA_ "GenSigTimeoutTime_AGSM" SG_ 2651930645 Digit_04_ESL 0;
BA_ "GenSigTimeoutTime_ADCAM" SG_ 2651930645 Digit_04_ESL 0;
BA_ "GenSigTimeoutTime_SGW" SG_ 2651930645 Digit_05_ESL 0;
BA_ "GenSigTimeoutTime_RFHM" SG_ 2651930645 Digit_05_ESL 0;
BA_ "GenSigTimeoutTime_MPAD" SG_ 2651930645 Digit_05_ESL 0;
BA_ "GenSigTimeoutTime_IPC" SG_ 2651930645 Digit_05_ESL 0;
BA_ "GenSigTimeoutTime_GNMM" SG_ 2651930645 Digit_05_ESL 0;
BA_ "GenSigTimeoutTime_EVCU2" SG_ 2651930645 Digit_05_ESL 0;
BA_ "GenSigTimeoutTime_ESL" SG_ 2651930645 Digit_05_ESL 0;
BA_ "GenSigTimeoutTime_ECM" SG_ 2651930645 Digit_05_ESL 0;
BA_ "GenSigTimeoutTime_DTCM" SG_ 2651930645 Digit_05_ESL 0;
BA_ "GenSigTimeoutTime_DMSM" SG_ 2651930645 Digit_05_ESL 0;
BA_ "GenSigTimeoutTime_BSM" SG_ 2651930645 Digit_05_ESL 0;
BA_ "GenSigTimeoutTime_AGSM" SG_ 2651930645 Digit_05_ESL 0;
BA_ "GenSigTimeoutTime_ADCAM" SG_ 2651930645 Digit_05_ESL 0;
BA_ "GenSigTimeoutTime_SGW" SG_ 2651930645 Digit_06_ESL 0;
BA_ "GenSigTimeoutTime_RFHM" SG_ 2651930645 Digit_06_ESL 0;
BA_ "GenSigTimeoutTime_MPAD" SG_ 2651930645 Digit_06_ESL 0;
BA_ "GenSigTimeoutTime_IPC" SG_ 2651930645 Digit_06_ESL 0;
BA_ "GenSigTimeoutTime_GNMM" SG_ 2651930645 Digit_06_ESL 0;
BA_ "GenSigTimeoutTime_EVCU2" SG_ 2651930645 Digit_06_ESL 0;
BA_ "GenSigTimeoutTime_ESL" SG_ 2651930645 Digit_06_ESL 0;
BA_ "GenSigTimeoutTime_ECM" SG_ 2651930645 Digit_06_ESL 0;
BA_ "GenSigTimeoutTime_DTCM" SG_ 2651930645 Digit_06_ESL 0;
BA_ "GenSigTimeoutTime_DMSM" SG_ 2651930645 Digit_06_ESL 0;
BA_ "GenSigTimeoutTime_BSM" SG_ 2651930645 Digit_06_ESL 0;
BA_ "GenSigTimeoutTime_AGSM" SG_ 2651930645 Digit_06_ESL 0;
BA_ "GenSigTimeoutTime_ADCAM" SG_ 2651930645 Digit_06_ESL 0;
BA_ "GenSigTimeoutTime_SGW" SG_ 2651930645 Digit_07_ESL 0;
BA_ "GenSigTimeoutTime_RFHM" SG_ 2651930645 Digit_07_ESL 0;
BA_ "GenSigTimeoutTime_MPAD" SG_ 2651930645 Digit_07_ESL 0;
BA_ "GenSigTimeoutTime_IPC" SG_ 2651930645 Digit_07_ESL 0;
BA_ "GenSigTimeoutTime_GNMM" SG_ 2651930645 Digit_07_ESL 0;
BA_ "GenSigTimeoutTime_EVCU2" SG_ 2651930645 Digit_07_ESL 0;
BA_ "GenSigTimeoutTime_ESL" SG_ 2651930645 Digit_07_ESL 0;
BA_ "GenSigTimeoutTime_ECM" SG_ 2651930645 Digit_07_ESL 0;
BA_ "GenSigTimeoutTime_DTCM" SG_ 2651930645 Digit_07_ESL 0;
BA_ "GenSigTimeoutTime_DMSM" SG_ 2651930645 Digit_07_ESL 0;
BA_ "GenSigTimeoutTime_BSM" SG_ 2651930645 Digit_07_ESL 0;
BA_ "GenSigTimeoutTime_AGSM" SG_ 2651930645 Digit_07_ESL 0;
BA_ "GenSigTimeoutTime_ADCAM" SG_ 2651930645 Digit_07_ESL 0;
BA_ "GenSigTimeoutTime_SGW" SG_ 2651930625 Digit_11_ECM 0;
BA_ "GenSigTimeoutTime_RFHM" SG_ 2651930625 Digit_11_ECM 0;
BA_ "GenSigTimeoutTime_MPAD" SG_ 2651930625 Digit_11_ECM 0;
BA_ "GenSigTimeoutTime_IPC" SG_ 2651930625 Digit_11_ECM 0;
BA_ "GenSigTimeoutTime_GNMM" SG_ 2651930625 Digit_11_ECM 0;
BA_ "GenSigTimeoutTime_EVCU2" SG_ 2651930625 Digit_11_ECM 0;
BA_ "GenSigTimeoutTime_ESL" SG_ 2651930625 Digit_11_ECM 0;
BA_ "GenSigTimeoutTime_ECM" SG_ 2651930625 Digit_11_ECM 0;
BA_ "GenSigTimeoutTime_DTCM" SG_ 2651930625 Digit_11_ECM 0;
BA_ "GenSigTimeoutTime_DMSM" SG_ 2651930625 Digit_11_ECM 0;
BA_ "GenSigTimeoutTime_BSM" SG_ 2651930625 Digit_11_ECM 0;
BA_ "GenSigTimeoutTime_AGSM" SG_ 2651930625 Digit_11_ECM 0;
BA_ "GenSigTimeoutTime_ADCAM" SG_ 2651930625 Digit_11_ECM 0;
BA_ "GenSigTimeoutTime_SGW" SG_ 2651930625 Digit_09_ECM 0;
BA_ "GenSigTimeoutTime_RFHM" SG_ 2651930625 Digit_09_ECM 0;
BA_ "GenSigTimeoutTime_MPAD" SG_ 2651930625 Digit_09_ECM 0;
BA_ "GenSigTimeoutTime_IPC" SG_ 2651930625 Digit_09_ECM 0;
BA_ "GenSigTimeoutTime_GNMM" SG_ 2651930625 Digit_09_ECM 0;
BA_ "GenSigTimeoutTime_EVCU2" SG_ 2651930625 Digit_09_ECM 0;
BA_ "GenSigTimeoutTime_ESL" SG_ 2651930625 Digit_09_ECM 0;
BA_ "GenSigTimeoutTime_ECM" SG_ 2651930625 Digit_09_ECM 0;
BA_ "GenSigTimeoutTime_DTCM" SG_ 2651930625 Digit_09_ECM 0;
BA_ "GenSigTimeoutTime_DMSM" SG_ 2651930625 Digit_09_ECM 0;
BA_ "GenSigTimeoutTime_BSM" SG_ 2651930625 Digit_09_ECM 0;
BA_ "GenSigTimeoutTime_AGSM" SG_ 2651930625 Digit_09_ECM 0;
BA_ "GenSigTimeoutTime_ADCAM" SG_ 2651930625 Digit_09_ECM 0;
BA_ "GenSigTimeoutTime_SGW" SG_ 2651930625 Digit_10_ECM 0;
BA_ "GenSigTimeoutTime_RFHM" SG_ 2651930625 Digit_10_ECM 0;
BA_ "GenSigTimeoutTime_MPAD" SG_ 2651930625 Digit_10_ECM 0;
BA_ "GenSigTimeoutTime_IPC" SG_ 2651930625 Digit_10_ECM 0;
BA_ "GenSigTimeoutTime_GNMM" SG_ 2651930625 Digit_10_ECM 0;
BA_ "GenSigTimeoutTime_EVCU2" SG_ 2651930625 Digit_10_ECM 0;
BA_ "GenSigTimeoutTime_ESL" SG_ 2651930625 Digit_10_ECM 0;
BA_ "GenSigTimeoutTime_ECM" SG_ 2651930625 Digit_10_ECM 0;
BA_ "GenSigTimeoutTime_DTCM" SG_ 2651930625 Digit_10_ECM 0;
BA_ "GenSigTimeoutTime_DMSM" SG_ 2651930625 Digit_10_ECM 0;
BA_ "GenSigTimeoutTime_BSM" SG_ 2651930625 Digit_10_ECM 0;
BA_ "GenSigTimeoutTime_AGSM" SG_ 2651930625 Digit_10_ECM 0;
BA_ "GenSigTimeoutTime_ADCAM" SG_ 2651930625 Digit_10_ECM 0;
BA_ "GenSigTimeoutTime_SGW" SG_ 2651930625 Digit_04_ECM 0;
BA_ "GenSigTimeoutTime_RFHM" SG_ 2651930625 Digit_04_ECM 0;
BA_ "GenSigTimeoutTime_MPAD" SG_ 2651930625 Digit_04_ECM 0;
BA_ "GenSigTimeoutTime_IPC" SG_ 2651930625 Digit_04_ECM 0;
BA_ "GenSigTimeoutTime_GNMM" SG_ 2651930625 Digit_04_ECM 0;
BA_ "GenSigTimeoutTime_EVCU2" SG_ 2651930625 Digit_04_ECM 0;
BA_ "GenSigTimeoutTime_ESL" SG_ 2651930625 Digit_04_ECM 0;
BA_ "GenSigTimeoutTime_ECM" SG_ 2651930625 Digit_04_ECM 0;
BA_ "GenSigTimeoutTime_DTCM" SG_ 2651930625 Digit_04_ECM 0;
BA_ "GenSigTimeoutTime_DMSM" SG_ 2651930625 Digit_04_ECM 0;
BA_ "GenSigTimeoutTime_BSM" SG_ 2651930625 Digit_04_ECM 0;
BA_ "GenSigTimeoutTime_AGSM" SG_ 2651930625 Digit_04_ECM 0;
BA_ "GenSigTimeoutTime_SGW" SG_ 2651930625 Digit_05_ECM 0;
BA_ "GenSigTimeoutTime_RFHM" SG_ 2651930625 Digit_05_ECM 0;
BA_ "GenSigTimeoutTime_MPAD" SG_ 2651930625 Digit_05_ECM 0;
BA_ "GenSigTimeoutTime_IPC" SG_ 2651930625 Digit_05_ECM 0;
BA_ "GenSigTimeoutTime_GNMM" SG_ 2651930625 Digit_05_ECM 0;
BA_ "GenSigTimeoutTime_EVCU2" SG_ 2651930625 Digit_05_ECM 0;
BA_ "GenSigTimeoutTime_ESL" SG_ 2651930625 Digit_05_ECM 0;
BA_ "GenSigTimeoutTime_ECM" SG_ 2651930625 Digit_05_ECM 0;
BA_ "GenSigTimeoutTime_DTCM" SG_ 2651930625 Digit_05_ECM 0;
BA_ "GenSigTimeoutTime_DMSM" SG_ 2651930625 Digit_05_ECM 0;
BA_ "GenSigTimeoutTime_BSM" SG_ 2651930625 Digit_05_ECM 0;
BA_ "GenSigTimeoutTime_AGSM" SG_ 2651930625 Digit_05_ECM 0;
BA_ "GenSigTimeoutTime_ADCAM" SG_ 2651930625 Digit_05_ECM 0;
BA_ "GenSigTimeoutTime_GNMM" SG_ 2651930625 Digit_06_ECM 0;
BA_ "GenSigTimeoutTime_EVCU2" SG_ 2651930625 Digit_06_ECM 0;
BA_ "GenSigTimeoutTime_ESL" SG_ 2651930625 Digit_06_ECM 0;
BA_ "GenSigTimeoutTime_ECM" SG_ 2651930625 Digit_06_ECM 0;
BA_ "GenSigTimeoutTime_DTCM" SG_ 2651930625 Digit_06_ECM 0;
BA_ "GenSigTimeoutTime_DMSM" SG_ 2651930625 Digit_06_ECM 0;
BA_ "GenSigTimeoutTime_BSM" SG_ 2651930625 Digit_06_ECM 0;
BA_ "GenSigTimeoutTime_AGSM" SG_ 2651930625 Digit_06_ECM 0;
BA_ "GenSigTimeoutTime_ADCAM" SG_ 2651930625 Digit_06_ECM 0;
BA_ "GenSigTimeoutTime_SGW" SG_ 2651930625 Digit_06_ECM 0;
BA_ "GenSigTimeoutTime_RFHM" SG_ 2651930625 Digit_06_ECM 0;
BA_ "GenSigTimeoutTime_MPAD" SG_ 2651930625 Digit_06_ECM 0;
BA_ "GenSigTimeoutTime_IPC" SG_ 2651930625 Digit_06_ECM 0;
BA_ "GenSigTimeoutTime_SGW" SG_ 2651930625 Digit_07_ECM 0;
BA_ "GenSigTimeoutTime_RFHM" SG_ 2651930625 Digit_07_ECM 0;
BA_ "GenSigTimeoutTime_MPAD" SG_ 2651930625 Digit_07_ECM 0;
BA_ "GenSigTimeoutTime_IPC" SG_ 2651930625 Digit_07_ECM 0;
BA_ "GenSigTimeoutTime_GNMM" SG_ 2651930625 Digit_07_ECM 0;
BA_ "GenSigTimeoutTime_EVCU2" SG_ 2651930625 Digit_07_ECM 0;
BA_ "GenSigTimeoutTime_ESL" SG_ 2651930625 Digit_07_ECM 0;
BA_ "GenSigTimeoutTime_ECM" SG_ 2651930625 Digit_07_ECM 0;
BA_ "GenSigTimeoutTime_DTCM" SG_ 2651930625 Digit_07_ECM 0;
BA_ "GenSigTimeoutTime_DMSM" SG_ 2651930625 Digit_07_ECM 0;
BA_ "GenSigTimeoutTime_BSM" SG_ 2651930625 Digit_07_ECM 0;
BA_ "GenSigTimeoutTime_AGSM" SG_ 2651930625 Digit_07_ECM 0;
BA_ "GenSigTimeoutTime_ADCAM" SG_ 2651930625 Digit_07_ECM 0;
BA_ "GenSigTimeoutTime_SGW" SG_ 2651930625 Digit_08_ECM 0;
BA_ "GenSigTimeoutTime_RFHM" SG_ 2651930625 Digit_08_ECM 0;
BA_ "GenSigTimeoutTime_MPAD" SG_ 2651930625 Digit_08_ECM 0;
BA_ "GenSigTimeoutTime_IPC" SG_ 2651930625 Digit_08_ECM 0;
BA_ "GenSigTimeoutTime_GNMM" SG_ 2651930625 Digit_08_ECM 0;
BA_ "GenSigTimeoutTime_EVCU2" SG_ 2651930625 Digit_08_ECM 0;
BA_ "GenSigTimeoutTime_ESL" SG_ 2651930625 Digit_08_ECM 0;
BA_ "GenSigTimeoutTime_ECM" SG_ 2651930625 Digit_08_ECM 0;
BA_ "GenSigTimeoutTime_DTCM" SG_ 2651930625 Digit_08_ECM 0;
BA_ "GenSigTimeoutTime_DMSM" SG_ 2651930625 Digit_08_ECM 0;
BA_ "GenSigTimeoutTime_BSM" SG_ 2651930625 Digit_08_ECM 0;
BA_ "GenSigTimeoutTime_AGSM" SG_ 2651930625 Digit_08_ECM 0;
BA_ "GenSigTimeoutTime_ADCAM" SG_ 2651930625 Digit_08_ECM 0;
BA_ "GenSigTimeoutTime_SGW" SG_ 2651930645 Digit_01_ESL 0;
BA_ "GenSigTimeoutTime_RFHM" SG_ 2651930645 Digit_01_ESL 0;
BA_ "GenSigTimeoutTime_MPAD" SG_ 2651930645 Digit_01_ESL 0;
BA_ "GenSigTimeoutTime_IPC" SG_ 2651930645 Digit_01_ESL 0;
BA_ "GenSigTimeoutTime_GNMM" SG_ 2651930645 Digit_01_ESL 0;
BA_ "GenSigTimeoutTime_EVCU2" SG_ 2651930645 Digit_01_ESL 0;
BA_ "GenSigTimeoutTime_ESL" SG_ 2651930645 Digit_01_ESL 0;
BA_ "GenSigTimeoutTime_ECM" SG_ 2651930645 Digit_01_ESL 0;
BA_ "GenSigTimeoutTime_DTCM" SG_ 2651930645 Digit_01_ESL 0;
BA_ "GenSigTimeoutTime_DMSM" SG_ 2651930645 Digit_01_ESL 0;
BA_ "GenSigTimeoutTime_BSM" SG_ 2651930645 Digit_01_ESL 0;
BA_ "GenSigTimeoutTime_AGSM" SG_ 2651930645 Digit_01_ESL 0;
BA_ "GenSigTimeoutTime_ADCAM" SG_ 2651930645 Digit_01_ESL 0;
BA_ "GenSigSendType" SG_ 2651930645 Digit_01_ESL 1;
BA_ "GenSigTimeoutTime_SGW" SG_ 2651930645 Digit_02_ESL 0;
BA_ "GenSigTimeoutTime_RFHM" SG_ 2651930645 Digit_02_ESL 0;
BA_ "GenSigTimeoutTime_MPAD" SG_ 2651930645 Digit_02_ESL 0;
BA_ "GenSigTimeoutTime_IPC" SG_ 2651930645 Digit_02_ESL 0;
BA_ "GenSigTimeoutTime_GNMM" SG_ 2651930645 Digit_02_ESL 0;
BA_ "GenSigTimeoutTime_EVCU2" SG_ 2651930645 Digit_02_ESL 0;
BA_ "GenSigTimeoutTime_ESL" SG_ 2651930645 Digit_02_ESL 0;
BA_ "GenSigTimeoutTime_ECM" SG_ 2651930645 Digit_02_ESL 0;
BA_ "GenSigTimeoutTime_DTCM" SG_ 2651930645 Digit_02_ESL 0;
BA_ "GenSigTimeoutTime_DMSM" SG_ 2651930645 Digit_02_ESL 0;
BA_ "GenSigTimeoutTime_BSM" SG_ 2651930645 Digit_02_ESL 0;
BA_ "GenSigTimeoutTime_AGSM" SG_ 2651930645 Digit_02_ESL 0;
BA_ "GenSigTimeoutTime_ADCAM" SG_ 2651930645 Digit_02_ESL 0;
BA_ "GenSigTimeoutTime_SGW" SG_ 2651930645 Digit_03_ESL 0;
BA_ "GenSigTimeoutTime_RFHM" SG_ 2651930645 Digit_03_ESL 0;
BA_ "GenSigTimeoutTime_MPAD" SG_ 2651930645 Digit_03_ESL 0;
BA_ "GenSigTimeoutTime_IPC" SG_ 2651930645 Digit_03_ESL 0;
BA_ "GenSigTimeoutTime_GNMM" SG_ 2651930645 Digit_03_ESL 0;
BA_ "GenSigTimeoutTime_EVCU2" SG_ 2651930645 Digit_03_ESL 0;
BA_ "GenSigTimeoutTime_ESL" SG_ 2651930645 Digit_03_ESL 0;
BA_ "GenSigTimeoutTime_ECM" SG_ 2651930645 Digit_03_ESL 0;
BA_ "GenSigTimeoutTime_DTCM" SG_ 2651930645 Digit_03_ESL 0;
BA_ "GenSigTimeoutTime_DMSM" SG_ 2651930645 Digit_03_ESL 0;
BA_ "GenSigTimeoutTime_BSM" SG_ 2651930645 Digit_03_ESL 0;
BA_ "GenSigTimeoutTime_AGSM" SG_ 2651930645 Digit_03_ESL 0;
BA_ "GenSigTimeoutTime_ADCAM" SG_ 2651930645 Digit_03_ESL 0;
BA_ "GenSigTimeoutTime_ADCAM" SG_ 2651930625 Digit_04_ECM 0;
BA_ "GenSigTimeoutTime_SGW" SG_ 2651930625 Digit_03_ECM 0;
BA_ "GenSigTimeoutTime_RFHM" SG_ 2651930625 Digit_03_ECM 0;
BA_ "GenSigTimeoutTime_MPAD" SG_ 2651930625 Digit_03_ECM 0;
BA_ "GenSigTimeoutTime_IPC" SG_ 2651930625 Digit_03_ECM 0;
BA_ "GenSigTimeoutTime_GNMM" SG_ 2651930625 Digit_03_ECM 0;
BA_ "GenSigTimeoutTime_EVCU2" SG_ 2651930625 Digit_03_ECM 0;
BA_ "GenSigTimeoutTime_ESL" SG_ 2651930625 Digit_03_ECM 0;
BA_ "GenSigTimeoutTime_ECM" SG_ 2651930625 Digit_03_ECM 0;
BA_ "GenSigTimeoutTime_DTCM" SG_ 2651930625 Digit_03_ECM 0;
BA_ "GenSigTimeoutTime_DMSM" SG_ 2651930625 Digit_03_ECM 0;
BA_ "GenSigTimeoutTime_BSM" SG_ 2651930625 Digit_03_ECM 0;
BA_ "GenSigTimeoutTime_AGSM" SG_ 2651930625 Digit_03_ECM 0;
BA_ "GenSigTimeoutTime_ADCAM" SG_ 2651930625 Digit_03_ECM 0;
BA_ "GenSigTimeoutTime_SGW" SG_ 2651930625 Digit_01_ECM 0;
BA_ "GenSigTimeoutTime_RFHM" SG_ 2651930625 Digit_01_ECM 0;
BA_ "GenSigTimeoutTime_MPAD" SG_ 2651930625 Digit_01_ECM 0;
BA_ "GenSigTimeoutTime_IPC" SG_ 2651930625 Digit_01_ECM 0;
BA_ "GenSigTimeoutTime_GNMM" SG_ 2651930625 Digit_01_ECM 0;
BA_ "GenSigTimeoutTime_EVCU2" SG_ 2651930625 Digit_01_ECM 0;
BA_ "GenSigTimeoutTime_ESL" SG_ 2651930625 Digit_01_ECM 0;
BA_ "GenSigTimeoutTime_ECM" SG_ 2651930625 Digit_01_ECM 0;
BA_ "GenSigTimeoutTime_DTCM" SG_ 2651930625 Digit_01_ECM 0;
BA_ "GenSigTimeoutTime_DMSM" SG_ 2651930625 Digit_01_ECM 0;
BA_ "GenSigTimeoutTime_BSM" SG_ 2651930625 Digit_01_ECM 0;
BA_ "GenSigTimeoutTime_AGSM" SG_ 2651930625 Digit_01_ECM 0;
BA_ "GenSigTimeoutTime_ADCAM" SG_ 2651930625 Digit_01_ECM 0;
BA_ "GenSigSendType" SG_ 2651930625 Digit_01_ECM 1;
BA_ "GenSigTimeoutTime_SGW" SG_ 2651930625 Digit_02_ECM 0;
BA_ "GenSigTimeoutTime_RFHM" SG_ 2651930625 Digit_02_ECM 0;
BA_ "GenSigTimeoutTime_MPAD" SG_ 2651930625 Digit_02_ECM 0;
BA_ "GenSigTimeoutTime_IPC" SG_ 2651930625 Digit_02_ECM 0;
BA_ "GenSigTimeoutTime_GNMM" SG_ 2651930625 Digit_02_ECM 0;
BA_ "GenSigTimeoutTime_EVCU2" SG_ 2651930625 Digit_02_ECM 0;
BA_ "GenSigTimeoutTime_ESL" SG_ 2651930625 Digit_02_ECM 0;
BA_ "GenSigTimeoutTime_ECM" SG_ 2651930625 Digit_02_ECM 0;
BA_ "GenSigTimeoutTime_DTCM" SG_ 2651930625 Digit_02_ECM 0;
BA_ "GenSigTimeoutTime_DMSM" SG_ 2651930625 Digit_02_ECM 0;
BA_ "GenSigTimeoutTime_BSM" SG_ 2651930625 Digit_02_ECM 0;
BA_ "GenSigTimeoutTime_AGSM" SG_ 2651930625 Digit_02_ECM 0;
BA_ "GenSigTimeoutTime_ADCAM" SG_ 2651930625 Digit_02_ECM 0;
BA_ "GenSigTimeoutTime_SGW" SG_ 2651930691 Digit_07_DTCM 0;
BA_ "GenSigTimeoutTime_RFHM" SG_ 2651930691 Digit_07_DTCM 0;
BA_ "GenSigTimeoutTime_MPAD" SG_ 2651930691 Digit_07_DTCM 0;
BA_ "GenSigTimeoutTime_IPC" SG_ 2651930691 Digit_07_DTCM 0;
BA_ "GenSigTimeoutTime_SGW" SG_ 2651930691 Digit_08_DTCM 0;
BA_ "GenSigTimeoutTime_RFHM" SG_ 2651930691 Digit_08_DTCM 0;
BA_ "GenSigTimeoutTime_MPAD" SG_ 2651930691 Digit_08_DTCM 0;
BA_ "GenSigTimeoutTime_IPC" SG_ 2651930691 Digit_08_DTCM 0;
BA_ "GenSigTimeoutTime_GNMM" SG_ 2651930691 Digit_08_DTCM 0;
BA_ "GenSigTimeoutTime_EVCU2" SG_ 2651930691 Digit_08_DTCM 0;
BA_ "GenSigTimeoutTime_ESL" SG_ 2651930691 Digit_08_DTCM 0;
BA_ "GenSigTimeoutTime_ECM" SG_ 2651930691 Digit_08_DTCM 0;
BA_ "GenSigTimeoutTime_DTCM" SG_ 2651930691 Digit_08_DTCM 0;
BA_ "GenSigTimeoutTime_DMSM" SG_ 2651930691 Digit_08_DTCM 0;
BA_ "GenSigTimeoutTime_BSM" SG_ 2651930691 Digit_08_DTCM 0;
BA_ "GenSigTimeoutTime_AGSM" SG_ 2651930691 Digit_08_DTCM 0;
BA_ "GenSigTimeoutTime_ADCAM" SG_ 2651930691 Digit_08_DTCM 0;
BA_ "GenSigTimeoutTime_SGW" SG_ 2651930691 Digit_09_DTCM 0;
BA_ "GenSigTimeoutTime_RFHM" SG_ 2651930691 Digit_09_DTCM 0;
BA_ "GenSigTimeoutTime_MPAD" SG_ 2651930691 Digit_09_DTCM 0;
BA_ "GenSigTimeoutTime_IPC" SG_ 2651930691 Digit_09_DTCM 0;
BA_ "GenSigTimeoutTime_GNMM" SG_ 2651930691 Digit_09_DTCM 0;
BA_ "GenSigTimeoutTime_EVCU2" SG_ 2651930691 Digit_09_DTCM 0;
BA_ "GenSigTimeoutTime_ESL" SG_ 2651930691 Digit_09_DTCM 0;
BA_ "GenSigTimeoutTime_ECM" SG_ 2651930691 Digit_09_DTCM 0;
BA_ "GenSigTimeoutTime_DTCM" SG_ 2651930691 Digit_09_DTCM 0;
BA_ "GenSigTimeoutTime_DMSM" SG_ 2651930691 Digit_09_DTCM 0;
BA_ "GenSigTimeoutTime_BSM" SG_ 2651930691 Digit_09_DTCM 0;
BA_ "GenSigTimeoutTime_AGSM" SG_ 2651930691 Digit_09_DTCM 0;
BA_ "GenSigTimeoutTime_ADCAM" SG_ 2651930691 Digit_09_DTCM 0;
BA_ "GenSigTimeoutTime_ADCAM" SG_ 2651930691 Digit_10_DTCM 0;
BA_ "GenSigTimeoutTime_SGW" SG_ 2651930691 Digit_10_DTCM 0;
BA_ "GenSigTimeoutTime_RFHM" SG_ 2651930691 Digit_10_DTCM 0;
BA_ "GenSigTimeoutTime_MPAD" SG_ 2651930691 Digit_10_DTCM 0;
BA_ "GenSigTimeoutTime_IPC" SG_ 2651930691 Digit_10_DTCM 0;
BA_ "GenSigTimeoutTime_GNMM" SG_ 2651930691 Digit_10_DTCM 0;
BA_ "GenSigTimeoutTime_EVCU2" SG_ 2651930691 Digit_10_DTCM 0;
BA_ "GenSigTimeoutTime_ESL" SG_ 2651930691 Digit_10_DTCM 0;
BA_ "GenSigTimeoutTime_ECM" SG_ 2651930691 Digit_10_DTCM 0;
BA_ "GenSigTimeoutTime_DTCM" SG_ 2651930691 Digit_10_DTCM 0;
BA_ "GenSigTimeoutTime_DMSM" SG_ 2651930691 Digit_10_DTCM 0;
BA_ "GenSigTimeoutTime_BSM" SG_ 2651930691 Digit_10_DTCM 0;
BA_ "GenSigTimeoutTime_AGSM" SG_ 2651930691 Digit_10_DTCM 0;
BA_ "GenSigTimeoutTime_SGW" SG_ 2651930691 Digit_11_DTCM 0;
BA_ "GenSigTimeoutTime_RFHM" SG_ 2651930691 Digit_11_DTCM 0;
BA_ "GenSigTimeoutTime_MPAD" SG_ 2651930691 Digit_11_DTCM 0;
BA_ "GenSigTimeoutTime_IPC" SG_ 2651930691 Digit_11_DTCM 0;
BA_ "GenSigTimeoutTime_GNMM" SG_ 2651930691 Digit_11_DTCM 0;
BA_ "GenSigTimeoutTime_EVCU2" SG_ 2651930691 Digit_11_DTCM 0;
BA_ "GenSigTimeoutTime_ESL" SG_ 2651930691 Digit_11_DTCM 0;
BA_ "GenSigTimeoutTime_ECM" SG_ 2651930691 Digit_11_DTCM 0;
BA_ "GenSigTimeoutTime_DTCM" SG_ 2651930691 Digit_11_DTCM 0;
BA_ "GenSigTimeoutTime_DMSM" SG_ 2651930691 Digit_11_DTCM 0;
BA_ "GenSigTimeoutTime_BSM" SG_ 2651930691 Digit_11_DTCM 0;
BA_ "GenSigTimeoutTime_AGSM" SG_ 2651930691 Digit_11_DTCM 0;
BA_ "GenSigTimeoutTime_ADCAM" SG_ 2651930691 Digit_11_DTCM 0;
BA_ "GenSigTimeoutTime_SGW" SG_ 2651930630 Digit_08_BSM 0;
BA_ "GenSigTimeoutTime_RFHM" SG_ 2651930630 Digit_08_BSM 0;
BA_ "GenSigTimeoutTime_MPAD" SG_ 2651930630 Digit_08_BSM 0;
BA_ "GenSigTimeoutTime_IPC" SG_ 2651930630 Digit_08_BSM 0;
BA_ "GenSigTimeoutTime_GNMM" SG_ 2651930630 Digit_08_BSM 0;
BA_ "GenSigTimeoutTime_EVCU2" SG_ 2651930630 Digit_08_BSM 0;
BA_ "GenSigTimeoutTime_ESL" SG_ 2651930630 Digit_08_BSM 0;
BA_ "GenSigTimeoutTime_ECM" SG_ 2651930630 Digit_08_BSM 0;
BA_ "GenSigTimeoutTime_DTCM" SG_ 2651930630 Digit_08_BSM 0;
BA_ "GenSigTimeoutTime_DMSM" SG_ 2651930630 Digit_08_BSM 0;
BA_ "GenSigTimeoutTime_BSM" SG_ 2651930630 Digit_08_BSM 0;
BA_ "GenSigTimeoutTime_AGSM" SG_ 2651930630 Digit_08_BSM 0;
BA_ "GenSigTimeoutTime_ADCAM" SG_ 2651930630 Digit_08_BSM 0;
BA_ "GenSigTimeoutTime_SGW" SG_ 2651930630 Digit_09_BSM 0;
BA_ "GenSigTimeoutTime_RFHM" SG_ 2651930630 Digit_09_BSM 0;
BA_ "GenSigTimeoutTime_MPAD" SG_ 2651930630 Digit_09_BSM 0;
BA_ "GenSigTimeoutTime_IPC" SG_ 2651930630 Digit_09_BSM 0;
BA_ "GenSigTimeoutTime_GNMM" SG_ 2651930630 Digit_09_BSM 0;
BA_ "GenSigTimeoutTime_EVCU2" SG_ 2651930630 Digit_09_BSM 0;
BA_ "GenSigTimeoutTime_ESL" SG_ 2651930630 Digit_09_BSM 0;
BA_ "GenSigTimeoutTime_ECM" SG_ 2651930630 Digit_09_BSM 0;
BA_ "GenSigTimeoutTime_DTCM" SG_ 2651930630 Digit_09_BSM 0;
BA_ "GenSigTimeoutTime_DMSM" SG_ 2651930630 Digit_09_BSM 0;
BA_ "GenSigTimeoutTime_BSM" SG_ 2651930630 Digit_09_BSM 0;
BA_ "GenSigTimeoutTime_AGSM" SG_ 2651930630 Digit_09_BSM 0;
BA_ "GenSigTimeoutTime_ADCAM" SG_ 2651930630 Digit_09_BSM 0;
BA_ "GenSigTimeoutTime_SGW" SG_ 2651930630 Digit_10_BSM 0;
BA_ "GenSigTimeoutTime_RFHM" SG_ 2651930630 Digit_10_BSM 0;
BA_ "GenSigTimeoutTime_MPAD" SG_ 2651930630 Digit_10_BSM 0;
BA_ "GenSigTimeoutTime_IPC" SG_ 2651930630 Digit_10_BSM 0;
BA_ "GenSigTimeoutTime_GNMM" SG_ 2651930630 Digit_10_BSM 0;
BA_ "GenSigTimeoutTime_EVCU2" SG_ 2651930630 Digit_10_BSM 0;
BA_ "GenSigTimeoutTime_ESL" SG_ 2651930630 Digit_10_BSM 0;
BA_ "GenSigTimeoutTime_ECM" SG_ 2651930630 Digit_10_BSM 0;
BA_ "GenSigTimeoutTime_DTCM" SG_ 2651930630 Digit_10_BSM 0;
BA_ "GenSigTimeoutTime_DMSM" SG_ 2651930630 Digit_10_BSM 0;
BA_ "GenSigTimeoutTime_BSM" SG_ 2651930630 Digit_10_BSM 0;
BA_ "GenSigTimeoutTime_AGSM" SG_ 2651930630 Digit_10_BSM 0;
BA_ "GenSigTimeoutTime_ADCAM" SG_ 2651930630 Digit_10_BSM 0;
BA_ "GenSigTimeoutTime_SGW" SG_ 2651930630 Digit_11_BSM 0;
BA_ "GenSigTimeoutTime_RFHM" SG_ 2651930630 Digit_11_BSM 0;
BA_ "GenSigTimeoutTime_MPAD" SG_ 2651930630 Digit_11_BSM 0;
BA_ "GenSigTimeoutTime_IPC" SG_ 2651930630 Digit_11_BSM 0;
BA_ "GenSigTimeoutTime_GNMM" SG_ 2651930630 Digit_11_BSM 0;
BA_ "GenSigTimeoutTime_EVCU2" SG_ 2651930630 Digit_11_BSM 0;
BA_ "GenSigTimeoutTime_ESL" SG_ 2651930630 Digit_11_BSM 0;
BA_ "GenSigTimeoutTime_ECM" SG_ 2651930630 Digit_11_BSM 0;
BA_ "GenSigTimeoutTime_DTCM" SG_ 2651930630 Digit_11_BSM 0;
BA_ "GenSigTimeoutTime_DMSM" SG_ 2651930630 Digit_11_BSM 0;
BA_ "GenSigTimeoutTime_BSM" SG_ 2651930630 Digit_11_BSM 0;
BA_ "GenSigTimeoutTime_AGSM" SG_ 2651930630 Digit_11_BSM 0;
BA_ "GenSigTimeoutTime_ADCAM" SG_ 2651930630 Digit_11_BSM 0;
BA_ "GenSigTimeoutTime_SGW" SG_ 2651930630 Digit_03_BSM 0;
BA_ "GenSigTimeoutTime_RFHM" SG_ 2651930630 Digit_03_BSM 0;
BA_ "GenSigTimeoutTime_MPAD" SG_ 2651930630 Digit_03_BSM 0;
BA_ "GenSigTimeoutTime_IPC" SG_ 2651930630 Digit_03_BSM 0;
BA_ "GenSigTimeoutTime_SGW" SG_ 2651930630 Digit_04_BSM 0;
BA_ "GenSigTimeoutTime_RFHM" SG_ 2651930630 Digit_04_BSM 0;
BA_ "GenSigTimeoutTime_MPAD" SG_ 2651930630 Digit_04_BSM 0;
BA_ "GenSigTimeoutTime_IPC" SG_ 2651930630 Digit_04_BSM 0;
BA_ "GenSigTimeoutTime_GNMM" SG_ 2651930630 Digit_04_BSM 0;
BA_ "GenSigTimeoutTime_EVCU2" SG_ 2651930630 Digit_04_BSM 0;
BA_ "GenSigTimeoutTime_ESL" SG_ 2651930630 Digit_04_BSM 0;
BA_ "GenSigTimeoutTime_ECM" SG_ 2651930630 Digit_04_BSM 0;
BA_ "GenSigTimeoutTime_DTCM" SG_ 2651930630 Digit_04_BSM 0;
BA_ "GenSigTimeoutTime_DMSM" SG_ 2651930630 Digit_04_BSM 0;
BA_ "GenSigTimeoutTime_BSM" SG_ 2651930630 Digit_04_BSM 0;
BA_ "GenSigTimeoutTime_AGSM" SG_ 2651930630 Digit_04_BSM 0;
BA_ "GenSigTimeoutTime_ADCAM" SG_ 2651930630 Digit_04_BSM 0;
BA_ "GenSigTimeoutTime_SGW" SG_ 2651930630 Digit_05_BSM 0;
BA_ "GenSigTimeoutTime_RFHM" SG_ 2651930630 Digit_05_BSM 0;
BA_ "GenSigTimeoutTime_MPAD" SG_ 2651930630 Digit_05_BSM 0;
BA_ "GenSigTimeoutTime_IPC" SG_ 2651930630 Digit_05_BSM 0;
BA_ "GenSigTimeoutTime_GNMM" SG_ 2651930630 Digit_05_BSM 0;
BA_ "GenSigTimeoutTime_EVCU2" SG_ 2651930630 Digit_05_BSM 0;
BA_ "GenSigTimeoutTime_ESL" SG_ 2651930630 Digit_05_BSM 0;
BA_ "GenSigTimeoutTime_ECM" SG_ 2651930630 Digit_05_BSM 0;
BA_ "GenSigTimeoutTime_DTCM" SG_ 2651930630 Digit_05_BSM 0;
BA_ "GenSigTimeoutTime_DMSM" SG_ 2651930630 Digit_05_BSM 0;
BA_ "GenSigTimeoutTime_BSM" SG_ 2651930630 Digit_05_BSM 0;
BA_ "GenSigTimeoutTime_AGSM" SG_ 2651930630 Digit_05_BSM 0;
BA_ "GenSigTimeoutTime_ADCAM" SG_ 2651930630 Digit_05_BSM 0;
BA_ "GenSigTimeoutTime_ADCAM" SG_ 2651930630 Digit_06_BSM 0;
BA_ "GenSigTimeoutTime_SGW" SG_ 2651930630 Digit_06_BSM 0;
BA_ "GenSigTimeoutTime_RFHM" SG_ 2651930630 Digit_06_BSM 0;
BA_ "GenSigTimeoutTime_MPAD" SG_ 2651930630 Digit_06_BSM 0;
BA_ "GenSigTimeoutTime_IPC" SG_ 2651930630 Digit_06_BSM 0;
BA_ "GenSigTimeoutTime_GNMM" SG_ 2651930630 Digit_06_BSM 0;
BA_ "GenSigTimeoutTime_EVCU2" SG_ 2651930630 Digit_06_BSM 0;
BA_ "GenSigTimeoutTime_ESL" SG_ 2651930630 Digit_06_BSM 0;
BA_ "GenSigTimeoutTime_ECM" SG_ 2651930630 Digit_06_BSM 0;
BA_ "GenSigTimeoutTime_DTCM" SG_ 2651930630 Digit_06_BSM 0;
BA_ "GenSigTimeoutTime_DMSM" SG_ 2651930630 Digit_06_BSM 0;
BA_ "GenSigTimeoutTime_BSM" SG_ 2651930630 Digit_06_BSM 0;
BA_ "GenSigTimeoutTime_AGSM" SG_ 2651930630 Digit_06_BSM 0;
BA_ "GenSigTimeoutTime_SGW" SG_ 2651930630 Digit_07_BSM 0;
BA_ "GenSigTimeoutTime_RFHM" SG_ 2651930630 Digit_07_BSM 0;
BA_ "GenSigTimeoutTime_MPAD" SG_ 2651930630 Digit_07_BSM 0;
BA_ "GenSigTimeoutTime_IPC" SG_ 2651930630 Digit_07_BSM 0;
BA_ "GenSigTimeoutTime_GNMM" SG_ 2651930630 Digit_07_BSM 0;
BA_ "GenSigTimeoutTime_EVCU2" SG_ 2651930630 Digit_07_BSM 0;
BA_ "GenSigTimeoutTime_ESL" SG_ 2651930630 Digit_07_BSM 0;
BA_ "GenSigTimeoutTime_ECM" SG_ 2651930630 Digit_07_BSM 0;
BA_ "GenSigTimeoutTime_DTCM" SG_ 2651930630 Digit_07_BSM 0;
BA_ "GenSigTimeoutTime_DMSM" SG_ 2651930630 Digit_07_BSM 0;
BA_ "GenSigTimeoutTime_BSM" SG_ 2651930630 Digit_07_BSM 0;
BA_ "GenSigTimeoutTime_AGSM" SG_ 2651930630 Digit_07_BSM 0;
BA_ "GenSigTimeoutTime_ADCAM" SG_ 2651930630 Digit_07_BSM 0;
BA_ "GenSigTimeoutTime_SGW" SG_ 1059 TxpID3 0;
BA_ "GenSigTimeoutTime_RFHM" SG_ 1059 TxpID3 0;
BA_ "GenSigTimeoutTime_MPAD" SG_ 1059 TxpID3 0;
BA_ "GenSigTimeoutTime_IPC" SG_ 1059 TxpID3 0;
BA_ "GenSigTimeoutTime_GNMM" SG_ 1059 TxpID3 0;
BA_ "GenSigTimeoutTime_EVCU2" SG_ 1059 TxpID3 0;
BA_ "GenSigTimeoutTime_ESL" SG_ 1059 TxpID3 0;
BA_ "GenSigTimeoutTime_ECM" SG_ 1059 TxpID3 0;
BA_ "GenSigTimeoutTime_DTCM" SG_ 1059 TxpID3 0;
BA_ "GenSigTimeoutTime_DMSM" SG_ 1059 TxpID3 0;
BA_ "GenSigTimeoutTime_BSM" SG_ 1059 TxpID3 0;
BA_ "GenSigTimeoutTime_AGSM" SG_ 1059 TxpID3 0;
BA_ "GenSigTimeoutTime_ADCAM" SG_ 1059 TxpID3 0;
BA_ "GenSigSendType" SG_ 1059 TxpID3 3;
BA_ "GenSigTimeoutTime_SGW" SG_ 254 TotalFrameNumber 0;
BA_ "GenSigTimeoutTime_RFHM" SG_ 254 TotalFrameNumber 0;
BA_ "GenSigTimeoutTime_MPAD" SG_ 254 TotalFrameNumber 0;
BA_ "GenSigTimeoutTime_IPC" SG_ 254 TotalFrameNumber 0;
BA_ "GenSigTimeoutTime_GNMM" SG_ 254 TotalFrameNumber 0;
BA_ "GenSigTimeoutTime_EVCU2" SG_ 254 TotalFrameNumber 0;
BA_ "GenSigTimeoutTime_ESL" SG_ 254 TotalFrameNumber 0;
BA_ "GenSigTimeoutTime_ECM" SG_ 254 TotalFrameNumber 0;
BA_ "GenSigTimeoutTime_DTCM" SG_ 254 TotalFrameNumber 0;
BA_ "GenSigTimeoutTime_DMSM" SG_ 254 TotalFrameNumber 0;
BA_ "GenSigTimeoutTime_BSM" SG_ 254 TotalFrameNumber 0;
BA_ "GenSigTimeoutTime_AGSM" SG_ 254 TotalFrameNumber 0;
BA_ "GenSigTimeoutTime_ADCAM" SG_ 254 TotalFrameNumber 0;
BA_ "GenSigTimeoutTime_SGW" SG_ 254 FrameNumber 0;
BA_ "GenSigTimeoutTime_RFHM" SG_ 254 FrameNumber 0;
BA_ "GenSigTimeoutTime_MPAD" SG_ 254 FrameNumber 0;
BA_ "GenSigTimeoutTime_IPC" SG_ 254 FrameNumber 0;
BA_ "GenSigTimeoutTime_GNMM" SG_ 254 FrameNumber 0;
BA_ "GenSigTimeoutTime_EVCU2" SG_ 254 FrameNumber 0;
BA_ "GenSigTimeoutTime_ESL" SG_ 254 FrameNumber 0;
BA_ "GenSigTimeoutTime_ECM" SG_ 254 FrameNumber 0;
BA_ "GenSigTimeoutTime_DTCM" SG_ 254 FrameNumber 0;
BA_ "GenSigTimeoutTime_DMSM" SG_ 254 FrameNumber 0;
BA_ "GenSigTimeoutTime_BSM" SG_ 254 FrameNumber 0;
BA_ "GenSigTimeoutTime_AGSM" SG_ 254 FrameNumber 0;
BA_ "GenSigTimeoutTime_ADCAM" SG_ 254 FrameNumber 0;
BA_ "GenSigSendType" SG_ 254 FrameNumber 1;
BA_ "GenSigTimeoutTime_SGW" SG_ 254 DATA7 0;
BA_ "GenSigTimeoutTime_RFHM" SG_ 254 DATA7 0;
BA_ "GenSigTimeoutTime_MPAD" SG_ 254 DATA7 0;
BA_ "GenSigTimeoutTime_IPC" SG_ 254 DATA7 0;
BA_ "GenSigTimeoutTime_GNMM" SG_ 254 DATA7 0;
BA_ "GenSigTimeoutTime_EVCU2" SG_ 254 DATA7 0;
BA_ "GenSigTimeoutTime_ESL" SG_ 254 DATA7 0;
BA_ "GenSigTimeoutTime_ECM" SG_ 254 DATA7 0;
BA_ "GenSigTimeoutTime_DTCM" SG_ 254 DATA7 0;
BA_ "GenSigTimeoutTime_DMSM" SG_ 254 DATA7 0;
BA_ "GenSigTimeoutTime_BSM" SG_ 254 DATA7 0;
BA_ "GenSigTimeoutTime_AGSM" SG_ 254 DATA7 0;
BA_ "GenSigTimeoutTime_ADCAM" SG_ 254 DATA7 0;
BA_ "GenSigTimeoutTime_SGW" SG_ 254 DATA6 0;
BA_ "GenSigTimeoutTime_RFHM" SG_ 254 DATA6 0;
BA_ "GenSigTimeoutTime_MPAD" SG_ 254 DATA6 0;
BA_ "GenSigTimeoutTime_IPC" SG_ 254 DATA6 0;
BA_ "GenSigTimeoutTime_GNMM" SG_ 254 DATA6 0;
BA_ "GenSigTimeoutTime_EVCU2" SG_ 254 DATA6 0;
BA_ "GenSigTimeoutTime_ESL" SG_ 254 DATA6 0;
BA_ "GenSigTimeoutTime_ECM" SG_ 254 DATA6 0;
BA_ "GenSigTimeoutTime_DTCM" SG_ 254 DATA6 0;
BA_ "GenSigTimeoutTime_DMSM" SG_ 254 DATA6 0;
BA_ "GenSigTimeoutTime_BSM" SG_ 254 DATA6 0;
BA_ "GenSigTimeoutTime_AGSM" SG_ 254 DATA6 0;
BA_ "GenSigTimeoutTime_ADCAM" SG_ 254 DATA6 0;
BA_ "GenSigTimeoutTime_SGW" SG_ 254 DATA5 0;
BA_ "GenSigTimeoutTime_RFHM" SG_ 254 DATA5 0;
BA_ "GenSigTimeoutTime_MPAD" SG_ 254 DATA5 0;
BA_ "GenSigTimeoutTime_IPC" SG_ 254 DATA5 0;
BA_ "GenSigTimeoutTime_GNMM" SG_ 254 DATA5 0;
BA_ "GenSigTimeoutTime_EVCU2" SG_ 254 DATA5 0;
BA_ "GenSigTimeoutTime_ESL" SG_ 254 DATA5 0;
BA_ "GenSigTimeoutTime_ECM" SG_ 254 DATA5 0;
BA_ "GenSigTimeoutTime_DTCM" SG_ 254 DATA5 0;
BA_ "GenSigTimeoutTime_DMSM" SG_ 254 DATA5 0;
BA_ "GenSigTimeoutTime_BSM" SG_ 254 DATA5 0;
BA_ "GenSigTimeoutTime_AGSM" SG_ 254 DATA5 0;
BA_ "GenSigTimeoutTime_ADCAM" SG_ 254 DATA5 0;
BA_ "GenSigTimeoutTime_SGW" SG_ 1059 ControlEncoding_TRM_Rsp 0;
BA_ "GenSigTimeoutTime_RFHM" SG_ 1059 ControlEncoding_TRM_Rsp 0;
BA_ "GenSigTimeoutTime_MPAD" SG_ 1059 ControlEncoding_TRM_Rsp 0;
BA_ "GenSigTimeoutTime_IPC" SG_ 1059 ControlEncoding_TRM_Rsp 0;
BA_ "GenSigTimeoutTime_GNMM" SG_ 1059 ControlEncoding_TRM_Rsp 0;
BA_ "GenSigTimeoutTime_EVCU2" SG_ 1059 ControlEncoding_TRM_Rsp 0;
BA_ "GenSigTimeoutTime_ESL" SG_ 1059 ControlEncoding_TRM_Rsp 0;
BA_ "GenSigTimeoutTime_ECM" SG_ 1059 ControlEncoding_TRM_Rsp 0;
BA_ "GenSigTimeoutTime_DTCM" SG_ 1059 ControlEncoding_TRM_Rsp 0;
BA_ "GenSigTimeoutTime_DMSM" SG_ 1059 ControlEncoding_TRM_Rsp 0;
BA_ "GenSigTimeoutTime_BSM" SG_ 1059 ControlEncoding_TRM_Rsp 0;
BA_ "GenSigTimeoutTime_AGSM" SG_ 1059 ControlEncoding_TRM_Rsp 0;
BA_ "GenSigTimeoutTime_ADCAM" SG_ 1059 ControlEncoding_TRM_Rsp 0;
BA_ "GenSigSendType" SG_ 1059 ControlEncoding_TRM_Rsp 3;
BA_ "GenSigTimeoutTime_SGW" SG_ 1059 MiniCryptGCode_TRM_Rsp 0;
BA_ "GenSigTimeoutTime_RFHM" SG_ 1059 MiniCryptGCode_TRM_Rsp 0;
BA_ "GenSigTimeoutTime_MPAD" SG_ 1059 MiniCryptGCode_TRM_Rsp 0;
BA_ "GenSigTimeoutTime_IPC" SG_ 1059 MiniCryptGCode_TRM_Rsp 0;
BA_ "GenSigTimeoutTime_GNMM" SG_ 1059 MiniCryptGCode_TRM_Rsp 0;
BA_ "GenSigTimeoutTime_EVCU2" SG_ 1059 MiniCryptGCode_TRM_Rsp 0;
BA_ "GenSigTimeoutTime_ESL" SG_ 1059 MiniCryptGCode_TRM_Rsp 0;
BA_ "GenSigTimeoutTime_ECM" SG_ 1059 MiniCryptGCode_TRM_Rsp 0;
BA_ "GenSigTimeoutTime_DTCM" SG_ 1059 MiniCryptGCode_TRM_Rsp 0;
BA_ "GenSigTimeoutTime_DMSM" SG_ 1059 MiniCryptGCode_TRM_Rsp 0;
BA_ "GenSigTimeoutTime_BSM" SG_ 1059 MiniCryptGCode_TRM_Rsp 0;
BA_ "GenSigTimeoutTime_AGSM" SG_ 1059 MiniCryptGCode_TRM_Rsp 0;
BA_ "GenSigTimeoutTime_ADCAM" SG_ 1059 MiniCryptGCode_TRM_Rsp 0;
BA_ "GenSigTimeoutTime_SGW" SG_ 1059 TxpFound 0;
BA_ "GenSigTimeoutTime_RFHM" SG_ 1059 TxpFound 0;
BA_ "GenSigTimeoutTime_MPAD" SG_ 1059 TxpFound 0;
BA_ "GenSigTimeoutTime_IPC" SG_ 1059 TxpFound 0;
BA_ "GenSigTimeoutTime_GNMM" SG_ 1059 TxpFound 0;
BA_ "GenSigTimeoutTime_EVCU2" SG_ 1059 TxpFound 0;
BA_ "GenSigTimeoutTime_ESL" SG_ 1059 TxpFound 0;
BA_ "GenSigTimeoutTime_ECM" SG_ 1059 TxpFound 0;
BA_ "GenSigTimeoutTime_DTCM" SG_ 1059 TxpFound 0;
BA_ "GenSigTimeoutTime_DMSM" SG_ 1059 TxpFound 0;
BA_ "GenSigTimeoutTime_BSM" SG_ 1059 TxpFound 0;
BA_ "GenSigTimeoutTime_AGSM" SG_ 1059 TxpFound 0;
BA_ "GenSigTimeoutTime_ADCAM" SG_ 1059 TxpFound 0;
BA_ "GenSigStartValue" SG_ 1059 TxpFound 1;
BA_ "GenSigTimeoutTime_SGW" SG_ 1059 ProgrammedSts_TRM 0;
BA_ "GenSigTimeoutTime_RFHM" SG_ 1059 ProgrammedSts_TRM 0;
BA_ "GenSigTimeoutTime_MPAD" SG_ 1059 ProgrammedSts_TRM 0;
BA_ "GenSigTimeoutTime_IPC" SG_ 1059 ProgrammedSts_TRM 0;
BA_ "GenSigTimeoutTime_GNMM" SG_ 1059 ProgrammedSts_TRM 0;
BA_ "GenSigTimeoutTime_EVCU2" SG_ 1059 ProgrammedSts_TRM 0;
BA_ "GenSigTimeoutTime_ESL" SG_ 1059 ProgrammedSts_TRM 0;
BA_ "GenSigTimeoutTime_ECM" SG_ 1059 ProgrammedSts_TRM 0;
BA_ "GenSigTimeoutTime_DTCM" SG_ 1059 ProgrammedSts_TRM 0;
BA_ "GenSigTimeoutTime_DMSM" SG_ 1059 ProgrammedSts_TRM 0;
BA_ "GenSigTimeoutTime_BSM" SG_ 1059 ProgrammedSts_TRM 0;
BA_ "GenSigTimeoutTime_AGSM" SG_ 1059 ProgrammedSts_TRM 0;
BA_ "GenSigTimeoutTime_ADCAM" SG_ 1059 ProgrammedSts_TRM 0;
BA_ "GenSigTimeoutTime_SGW" SG_ 254 DATA4 0;
BA_ "GenSigTimeoutTime_RFHM" SG_ 254 DATA4 0;
BA_ "GenSigTimeoutTime_MPAD" SG_ 254 DATA4 0;
BA_ "GenSigTimeoutTime_IPC" SG_ 254 DATA4 0;
BA_ "GenSigTimeoutTime_GNMM" SG_ 254 DATA4 0;
BA_ "GenSigTimeoutTime_EVCU2" SG_ 254 DATA4 0;
BA_ "GenSigTimeoutTime_ESL" SG_ 254 DATA4 0;
BA_ "GenSigTimeoutTime_ECM" SG_ 254 DATA4 0;
BA_ "GenSigTimeoutTime_DTCM" SG_ 254 DATA4 0;
BA_ "GenSigTimeoutTime_DMSM" SG_ 254 DATA4 0;
BA_ "GenSigTimeoutTime_BSM" SG_ 254 DATA4 0;
BA_ "GenSigTimeoutTime_AGSM" SG_ 254 DATA4 0;
BA_ "GenSigTimeoutTime_ADCAM" SG_ 254 DATA4 0;
BA_ "GenSigTimeoutTime_SGW" SG_ 254 DATA3 0;
BA_ "GenSigTimeoutTime_RFHM" SG_ 254 DATA3 0;
BA_ "GenSigTimeoutTime_MPAD" SG_ 254 DATA3 0;
BA_ "GenSigTimeoutTime_IPC" SG_ 254 DATA3 0;
BA_ "GenSigTimeoutTime_GNMM" SG_ 254 DATA3 0;
BA_ "GenSigTimeoutTime_EVCU2" SG_ 254 DATA3 0;
BA_ "GenSigTimeoutTime_ESL" SG_ 254 DATA3 0;
BA_ "GenSigTimeoutTime_ECM" SG_ 254 DATA3 0;
BA_ "GenSigTimeoutTime_DTCM" SG_ 254 DATA3 0;
BA_ "GenSigTimeoutTime_DMSM" SG_ 254 DATA3 0;
BA_ "GenSigTimeoutTime_BSM" SG_ 254 DATA3 0;
BA_ "GenSigTimeoutTime_AGSM" SG_ 254 DATA3 0;
BA_ "GenSigTimeoutTime_ADCAM" SG_ 254 DATA3 0;
BA_ "GenSigTimeoutTime_SGW" SG_ 254 DATA2 0;
BA_ "GenSigTimeoutTime_RFHM" SG_ 254 DATA2 0;
BA_ "GenSigTimeoutTime_MPAD" SG_ 254 DATA2 0;
BA_ "GenSigTimeoutTime_IPC" SG_ 254 DATA2 0;
BA_ "GenSigTimeoutTime_GNMM" SG_ 254 DATA2 0;
BA_ "GenSigTimeoutTime_EVCU2" SG_ 254 DATA2 0;
BA_ "GenSigTimeoutTime_ESL" SG_ 254 DATA2 0;
BA_ "GenSigTimeoutTime_ECM" SG_ 254 DATA2 0;
BA_ "GenSigTimeoutTime_DTCM" SG_ 254 DATA2 0;
BA_ "GenSigTimeoutTime_DMSM" SG_ 254 DATA2 0;
BA_ "GenSigTimeoutTime_BSM" SG_ 254 DATA2 0;
BA_ "GenSigTimeoutTime_AGSM" SG_ 254 DATA2 0;
BA_ "GenSigTimeoutTime_ADCAM" SG_ 254 DATA2 0;
BA_ "GenSigTimeoutTime_SGW" SG_ 254 DATA1 0;
BA_ "GenSigTimeoutTime_RFHM" SG_ 254 DATA1 0;
BA_ "GenSigTimeoutTime_MPAD" SG_ 254 DATA1 0;
BA_ "GenSigTimeoutTime_IPC" SG_ 254 DATA1 0;
BA_ "GenSigTimeoutTime_GNMM" SG_ 254 DATA1 0;
BA_ "GenSigTimeoutTime_EVCU2" SG_ 254 DATA1 0;
BA_ "GenSigTimeoutTime_ESL" SG_ 254 DATA1 0;
BA_ "GenSigTimeoutTime_ECM" SG_ 254 DATA1 0;
BA_ "GenSigTimeoutTime_DTCM" SG_ 254 DATA1 0;
BA_ "GenSigTimeoutTime_DMSM" SG_ 254 DATA1 0;
BA_ "GenSigTimeoutTime_BSM" SG_ 254 DATA1 0;
BA_ "GenSigTimeoutTime_AGSM" SG_ 254 DATA1 0;
BA_ "GenSigTimeoutTime_ADCAM" SG_ 254 DATA1 0;
BA_ "GenSigTimeoutTime_RFHM" SG_ 1450 OilTemperatureSts 0;
BA_ "GenSigTimeoutTime_MPAD" SG_ 1450 OilTemperatureSts 0;
BA_ "GenSigTimeoutTime_GNMM" SG_ 1450 OilTemperatureSts 0;
BA_ "GenSigTimeoutTime_EVCU2" SG_ 1450 OilTemperatureSts 0;
BA_ "GenSigTimeoutTime_ESL" SG_ 1450 OilTemperatureSts 0;
BA_ "GenSigTimeoutTime_ECM" SG_ 1450 OilTemperatureSts 0;
BA_ "GenSigTimeoutTime_DTCM" SG_ 1450 OilTemperatureSts 0;
BA_ "GenSigTimeoutTime_DMSM" SG_ 1450 OilTemperatureSts 0;
BA_ "GenSigTimeoutTime_BSM" SG_ 1450 OilTemperatureSts 0;
BA_ "GenSigTimeoutTime_BCM" SG_ 1450 OilTemperatureSts 0;
BA_ "GenSigTimeoutTime_AGSM" SG_ 1450 OilTemperatureSts 0;
BA_ "GenSigTimeoutTime_ADCAM" SG_ 1450 OilTemperatureSts 0;
BA_ "GenSigSendType" SG_ 1450 OilTemperatureSts 3;
BA_ "GenSigTimeoutTime_SGW" SG_ 1059 CodeCheckSts_TRM 0;
BA_ "GenSigTimeoutTime_RFHM" SG_ 1059 CodeCheckSts_TRM 0;
BA_ "GenSigTimeoutTime_MPAD" SG_ 1059 CodeCheckSts_TRM 0;
BA_ "GenSigTimeoutTime_IPC" SG_ 1059 CodeCheckSts_TRM 0;
BA_ "GenSigTimeoutTime_GNMM" SG_ 1059 CodeCheckSts_TRM 0;
BA_ "GenSigTimeoutTime_EVCU2" SG_ 1059 CodeCheckSts_TRM 0;
BA_ "GenSigTimeoutTime_ESL" SG_ 1059 CodeCheckSts_TRM 0;
BA_ "GenSigTimeoutTime_ECM" SG_ 1059 CodeCheckSts_TRM 0;
BA_ "GenSigTimeoutTime_DTCM" SG_ 1059 CodeCheckSts_TRM 0;
BA_ "GenSigTimeoutTime_DMSM" SG_ 1059 CodeCheckSts_TRM 0;
BA_ "GenSigTimeoutTime_BSM" SG_ 1059 CodeCheckSts_TRM 0;
BA_ "GenSigTimeoutTime_AGSM" SG_ 1059 CodeCheckSts_TRM 0;
BA_ "GenSigTimeoutTime_ADCAM" SG_ 1059 CodeCheckSts_TRM 0;
BA_ "GenSigTimeoutTime_SGW" SG_ 1876 TyrePressureSysProgrammedSts 0;
BA_ "GenSigTimeoutTime_RFHM" SG_ 1876 TyrePressureSysProgrammedSts 0;
BA_ "GenSigTimeoutTime_MPAD" SG_ 1876 TyrePressureSysProgrammedSts 0;
BA_ "GenSigTimeoutTime_GNMM" SG_ 1876 TyrePressureSysProgrammedSts 0;
BA_ "GenSigTimeoutTime_EVCU2" SG_ 1876 TyrePressureSysProgrammedSts 0;
BA_ "GenSigTimeoutTime_RFHM" SG_ 1876 TyrePressureSystemFailSts 0;
BA_ "GenSigTimeoutTime_GNMM" SG_ 1876 TyrePressureSystemFailSts 0;
BA_ "GenSigTimeoutTime_EVCU2" SG_ 1876 TyrePressureSystemFailSts 0;
BA_ "GenSigTimeoutTime_ESL" SG_ 1876 TyrePressureSystemFailSts 0;
BA_ "GenSigTimeoutTime_ECM" SG_ 1876 TyrePressureSystemFailSts 0;
BA_ "GenSigTimeoutTime_DTCM" SG_ 1876 TyrePressureSystemFailSts 0;
BA_ "GenSigTimeoutTime_DMSM" SG_ 1876 TyrePressureSystemFailSts 0;
BA_ "GenSigTimeoutTime_BSM" SG_ 1876 TyrePressureSystemFailSts 0;
BA_ "GenSigTimeoutTime_AGSM" SG_ 1876 TyrePressureSystemFailSts 0;
BA_ "GenSigTimeoutTime_ADCAM" SG_ 1876 TyrePressureSystemFailSts 0;
BA_ "GenSigSendType" SG_ 1876 TyrePressureSystemFailSts 4;
BA_ "GenSigTimeoutTime_BCM" SG_ 2651930624 Digit_11 0;
BA_ "GenSigTimeoutTime_BCM" SG_ 2651930624 Digit_09 0;
BA_ "GenSigTimeoutTime_BCM" SG_ 2651930624 Digit_10 0;
BA_ "GenSigTimeoutTime_BCM" SG_ 2651930624 Digit_07 0;
BA_ "GenSigTimeoutTime_BCM" SG_ 2651930624 Digit_08 0;
BA_ "GenSigTimeoutTime_BCM" SG_ 2651930624 Digit_05 0;
BA_ "GenSigTimeoutTime_BCM" SG_ 2651930624 Digit_06 0;
BA_ "GenSigTimeoutTime_BCM" SG_ 2651930624 Digit_02 0;
BA_ "GenSigTimeoutTime_BCM" SG_ 2651930624 Digit_03 0;
BA_ "GenSigTimeoutTime_BCM" SG_ 2651930624 Digit_04 0;
BA_ "GenSigTimeoutTime_BCM" SG_ 2651930624 Digit_01 0;
BA_ "GenSigTimeoutTime_RFHM" SG_ 1876 PressureValue_RHR_Tyre 0;
BA_ "GenSigTimeoutTime_GNMM" SG_ 1876 PressureValue_RHR_Tyre 0;
BA_ "GenSigTimeoutTime_EVCU2" SG_ 1876 PressureValue_RHR_Tyre 0;
BA_ "GenSigTimeoutTime_ESL" SG_ 1876 PressureValue_RHR_Tyre 0;
BA_ "GenSigTimeoutTime_ECM" SG_ 1876 PressureValue_RHR_Tyre 0;
BA_ "GenSigTimeoutTime_DTCM" SG_ 1876 PressureValue_RHR_Tyre 0;
BA_ "GenSigTimeoutTime_DMSM" SG_ 1876 PressureValue_RHR_Tyre 0;
BA_ "GenSigTimeoutTime_BSM" SG_ 1876 PressureValue_RHR_Tyre 0;
BA_ "GenSigTimeoutTime_AGSM" SG_ 1876 PressureValue_RHR_Tyre 0;
BA_ "GenSigTimeoutTime_ADCAM" SG_ 1876 PressureValue_RHR_Tyre 0;
BA_ "GenSigTimeoutTime_RFHM" SG_ 1876 PressureValue_LHR_Tyre 0;
BA_ "GenSigTimeoutTime_GNMM" SG_ 1876 PressureValue_LHR_Tyre 0;
BA_ "GenSigTimeoutTime_EVCU2" SG_ 1876 PressureValue_LHR_Tyre 0;
BA_ "GenSigTimeoutTime_ESL" SG_ 1876 PressureValue_LHR_Tyre 0;
BA_ "GenSigTimeoutTime_ECM" SG_ 1876 PressureValue_LHR_Tyre 0;
BA_ "GenSigTimeoutTime_DTCM" SG_ 1876 PressureValue_LHR_Tyre 0;
BA_ "GenSigTimeoutTime_DMSM" SG_ 1876 PressureValue_LHR_Tyre 0;
BA_ "GenSigTimeoutTime_BSM" SG_ 1876 PressureValue_LHR_Tyre 0;
BA_ "GenSigTimeoutTime_AGSM" SG_ 1876 PressureValue_LHR_Tyre 0;
BA_ "GenSigTimeoutTime_ADCAM" SG_ 1876 PressureValue_LHR_Tyre 0;
BA_ "GenSigTimeoutTime_RFHM" SG_ 1876 PressureValue_RHF_Tyre 0;
BA_ "GenSigTimeoutTime_GNMM" SG_ 1876 PressureValue_RHF_Tyre 0;
BA_ "GenSigTimeoutTime_EVCU2" SG_ 1876 PressureValue_RHF_Tyre 0;
BA_ "GenSigTimeoutTime_ESL" SG_ 1876 PressureValue_RHF_Tyre 0;
BA_ "GenSigTimeoutTime_ECM" SG_ 1876 PressureValue_RHF_Tyre 0;
BA_ "GenSigTimeoutTime_DTCM" SG_ 1876 PressureValue_RHF_Tyre 0;
BA_ "GenSigTimeoutTime_DMSM" SG_ 1876 PressureValue_RHF_Tyre 0;
BA_ "GenSigTimeoutTime_BSM" SG_ 1876 PressureValue_RHF_Tyre 0;
BA_ "GenSigTimeoutTime_AGSM" SG_ 1876 PressureValue_RHF_Tyre 0;
BA_ "GenSigTimeoutTime_ADCAM" SG_ 1876 PressureValue_RHF_Tyre 0;
BA_ "GenSigTimeoutTime_SGW" SG_ 1449 MsgPushBtnKey 0;
BA_ "GenSigTimeoutTime_RFHM" SG_ 1449 MsgPushBtnKey 0;
BA_ "GenSigTimeoutTime_MPAD" SG_ 1449 MsgPushBtnKey 0;
BA_ "GenSigTimeoutTime_GNMM" SG_ 1449 MsgPushBtnKey 0;
BA_ "GenSigTimeoutTime_EVCU2" SG_ 1449 MsgPushBtnKey 0;
BA_ "GenSigTimeoutTime_ESL" SG_ 1449 MsgPushBtnKey 0;
BA_ "GenSigTimeoutTime_ECM" SG_ 1449 MsgPushBtnKey 0;
BA_ "GenSigTimeoutTime_DTCM" SG_ 1449 MsgPushBtnKey 0;
BA_ "GenSigTimeoutTime_DMSM" SG_ 1449 MsgPushBtnKey 0;
BA_ "GenSigTimeoutTime_BSM" SG_ 1449 MsgPushBtnKey 0;
BA_ "GenSigTimeoutTime_BCM" SG_ 1449 MsgPushBtnKey 0;
BA_ "GenSigTimeoutTime_AGSM" SG_ 1449 MsgPushBtnKey 0;
BA_ "GenSigTimeoutTime_ADCAM" SG_ 1449 MsgPushBtnKey 0;
BA_ "GenSigSendType" SG_ 1449 MsgPushBtnKey 3;
BA_ "GenSigTimeoutTime_RFHM" SG_ 1876 PressureValue_LHF_Tyre 0;
BA_ "GenSigTimeoutTime_GNMM" SG_ 1876 PressureValue_LHF_Tyre 0;
BA_ "GenSigTimeoutTime_EVCU2" SG_ 1876 PressureValue_LHF_Tyre 0;
BA_ "GenSigTimeoutTime_ESL" SG_ 1876 PressureValue_LHF_Tyre 0;
BA_ "GenSigTimeoutTime_ECM" SG_ 1876 PressureValue_LHF_Tyre 0;
BA_ "GenSigTimeoutTime_DTCM" SG_ 1876 PressureValue_LHF_Tyre 0;
BA_ "GenSigTimeoutTime_DMSM" SG_ 1876 PressureValue_LHF_Tyre 0;
BA_ "GenSigTimeoutTime_BSM" SG_ 1876 PressureValue_LHF_Tyre 0;
BA_ "GenSigTimeoutTime_AGSM" SG_ 1876 PressureValue_LHF_Tyre 0;
BA_ "GenSigTimeoutTime_ADCAM" SG_ 1876 PressureValue_LHF_Tyre 0;
BA_ "GenSigTimeoutTime_SGW" SG_ 1449 TPMHazardFlash 0;
BA_ "GenSigTimeoutTime_RFHM" SG_ 1449 TPMHazardFlash 0;
BA_ "GenSigTimeoutTime_MPAD" SG_ 1449 TPMHazardFlash 0;
BA_ "GenSigTimeoutTime_GNMM" SG_ 1449 TPMHazardFlash 0;
BA_ "GenSigTimeoutTime_EVCU2" SG_ 1449 TPMHazardFlash 0;
BA_ "GenSigTimeoutTime_ESL" SG_ 1449 TPMHazardFlash 0;
BA_ "GenSigTimeoutTime_ECM" SG_ 1449 TPMHazardFlash 0;
BA_ "GenSigTimeoutTime_DTCM" SG_ 1449 TPMHazardFlash 0;
BA_ "GenSigTimeoutTime_DMSM" SG_ 1449 TPMHazardFlash 0;
BA_ "GenSigTimeoutTime_BSM" SG_ 1449 TPMHazardFlash 0;
BA_ "GenSigTimeoutTime_AGSM" SG_ 1449 TPMHazardFlash 0;
BA_ "GenSigTimeoutTime_ADCAM" SG_ 1449 TPMHazardFlash 0;
BA_ "GenSigSendType" SG_ 1449 TPMHazardFlash 3;
BA_ "GenSigTimeoutTime_SGW" SG_ 1449 TPMHornChirp 0;
BA_ "GenSigTimeoutTime_RFHM" SG_ 1449 TPMHornChirp 0;
BA_ "GenSigTimeoutTime_MPAD" SG_ 1449 TPMHornChirp 0;
BA_ "GenSigTimeoutTime_IPC" SG_ 1449 TPMHornChirp 0;
BA_ "GenSigTimeoutTime_GNMM" SG_ 1449 TPMHornChirp 0;
BA_ "GenSigTimeoutTime_EVCU2" SG_ 1449 TPMHornChirp 0;
BA_ "GenSigTimeoutTime_ESL" SG_ 1449 TPMHornChirp 0;
BA_ "GenSigTimeoutTime_ECM" SG_ 1449 TPMHornChirp 0;
BA_ "GenSigTimeoutTime_DTCM" SG_ 1449 TPMHornChirp 0;
BA_ "GenSigTimeoutTime_DMSM" SG_ 1449 TPMHornChirp 0;
BA_ "GenSigTimeoutTime_BSM" SG_ 1449 TPMHornChirp 0;
BA_ "GenSigTimeoutTime_AGSM" SG_ 1449 TPMHornChirp 0;
BA_ "GenSigTimeoutTime_ADCAM" SG_ 1449 TPMHornChirp 0;
BA_ "GenSigSendType" SG_ 1449 TPMHornChirp 3;
BA_ "GenSigTimeoutTime_SGW" SG_ 1449 STFASysEnableFault 0;
BA_ "GenSigTimeoutTime_RFHM" SG_ 1449 STFASysEnableFault 0;
BA_ "GenSigTimeoutTime_MPAD" SG_ 1449 STFASysEnableFault 0;
BA_ "GenSigTimeoutTime_IPC" SG_ 1449 STFASysEnableFault 0;
BA_ "GenSigTimeoutTime_GNMM" SG_ 1449 STFASysEnableFault 0;
BA_ "GenSigTimeoutTime_EVCU2" SG_ 1449 STFASysEnableFault 0;
BA_ "GenSigTimeoutTime_ESL" SG_ 1449 STFASysEnableFault 0;
BA_ "GenSigTimeoutTime_ECM" SG_ 1449 STFASysEnableFault 0;
BA_ "GenSigTimeoutTime_DTCM" SG_ 1449 STFASysEnableFault 0;
BA_ "GenSigTimeoutTime_DMSM" SG_ 1449 STFASysEnableFault 0;
BA_ "GenSigTimeoutTime_BSM" SG_ 1449 STFASysEnableFault 0;
BA_ "GenSigTimeoutTime_AGSM" SG_ 1449 STFASysEnableFault 0;
BA_ "GenSigTimeoutTime_ADCAM" SG_ 1449 STFASysEnableFault 0;
BA_ "GenSigSendType" SG_ 1449 STFASysEnableFault 3;
BA_ "GenSigTimeoutTime_SGW" SG_ 1449 RrTrPlacardPress 0;
BA_ "GenSigTimeoutTime_RFHM" SG_ 1449 RrTrPlacardPress 0;
BA_ "GenSigTimeoutTime_MPAD" SG_ 1449 RrTrPlacardPress 0;
BA_ "GenSigTimeoutTime_GNMM" SG_ 1449 RrTrPlacardPress 0;
BA_ "GenSigTimeoutTime_EVCU2" SG_ 1449 RrTrPlacardPress 0;
BA_ "GenSigTimeoutTime_ESL" SG_ 1449 RrTrPlacardPress 0;
BA_ "GenSigTimeoutTime_ECM" SG_ 1449 RrTrPlacardPress 0;
BA_ "GenSigTimeoutTime_DTCM" SG_ 1449 RrTrPlacardPress 0;
BA_ "GenSigTimeoutTime_DMSM" SG_ 1449 RrTrPlacardPress 0;
BA_ "GenSigTimeoutTime_BSM" SG_ 1449 RrTrPlacardPress 0;
BA_ "GenSigTimeoutTime_AGSM" SG_ 1449 RrTrPlacardPress 0;
BA_ "GenSigTimeoutTime_ADCAM" SG_ 1449 RrTrPlacardPress 0;
BA_ "GenSigSendType" SG_ 1449 RrTrPlacardPress 3;
BA_ "GenSigTimeoutTime_SGW" SG_ 1449 MsgKeyNotFnd 0;
BA_ "GenSigTimeoutTime_RFHM" SG_ 1449 MsgKeyNotFnd 0;
BA_ "GenSigTimeoutTime_MPAD" SG_ 1449 MsgKeyNotFnd 0;
BA_ "GenSigTimeoutTime_GNMM" SG_ 1449 MsgKeyNotFnd 0;
BA_ "GenSigTimeoutTime_EVCU2" SG_ 1449 MsgKeyNotFnd 0;
BA_ "GenSigTimeoutTime_ESL" SG_ 1449 MsgKeyNotFnd 0;
BA_ "GenSigTimeoutTime_ECM" SG_ 1449 MsgKeyNotFnd 0;
BA_ "GenSigTimeoutTime_DTCM" SG_ 1449 MsgKeyNotFnd 0;
BA_ "GenSigTimeoutTime_DMSM" SG_ 1449 MsgKeyNotFnd 0;
BA_ "GenSigTimeoutTime_BSM" SG_ 1449 MsgKeyNotFnd 0;
BA_ "GenSigTimeoutTime_BCM" SG_ 1449 MsgKeyNotFnd 0;
BA_ "GenSigTimeoutTime_AGSM" SG_ 1449 MsgKeyNotFnd 0;
BA_ "GenSigTimeoutTime_ADCAM" SG_ 1449 MsgKeyNotFnd 0;
BA_ "GenSigSendType" SG_ 1449 MsgKeyNotFnd 3;
BA_ "GenSigTimeoutTime_RFHM" SG_ 1876 CRC_RFHUB3 0;
BA_ "GenSigTimeoutTime_GNMM" SG_ 1876 CRC_RFHUB3 0;
BA_ "GenSigTimeoutTime_ESL" SG_ 1876 CRC_RFHUB3 0;
BA_ "GenSigTimeoutTime_ECM" SG_ 1876 CRC_RFHUB3 0;
BA_ "GenSigTimeoutTime_DTCM" SG_ 1876 CRC_RFHUB3 0;
BA_ "GenSigTimeoutTime_DMSM" SG_ 1876 CRC_RFHUB3 0;
BA_ "GenSigTimeoutTime_BSM" SG_ 1876 CRC_RFHUB3 0;
BA_ "GenSigTimeoutTime_BCM" SG_ 1876 CRC_RFHUB3 0;
BA_ "GenSigTimeoutTime_AGSM" SG_ 1876 CRC_RFHUB3 0;
BA_ "GenSigTimeoutTime_ADCAM" SG_ 1876 CRC_RFHUB3 0;
BA_ "GenSigTimeoutTime_RFHM" SG_ 1876 MessageCounter_RFHUB3 0;
BA_ "GenSigTimeoutTime_GNMM" SG_ 1876 MessageCounter_RFHUB3 0;
BA_ "GenSigTimeoutTime_ESL" SG_ 1876 MessageCounter_RFHUB3 0;
BA_ "GenSigTimeoutTime_ECM" SG_ 1876 MessageCounter_RFHUB3 0;
BA_ "GenSigTimeoutTime_DTCM" SG_ 1876 MessageCounter_RFHUB3 0;
BA_ "GenSigTimeoutTime_DMSM" SG_ 1876 MessageCounter_RFHUB3 0;
BA_ "GenSigTimeoutTime_BSM" SG_ 1876 MessageCounter_RFHUB3 0;
BA_ "GenSigTimeoutTime_BCM" SG_ 1876 MessageCounter_RFHUB3 0;
BA_ "GenSigTimeoutTime_AGSM" SG_ 1876 MessageCounter_RFHUB3 0;
BA_ "GenSigTimeoutTime_ADCAM" SG_ 1876 MessageCounter_RFHUB3 0;
BA_ "GenSigTimeoutTime_ESL" SG_ 1449 MsgFOBLeftVeh 0;
BA_ "GenSigTimeoutTime_SGW" SG_ 1449 FOBSearchActive 0;
BA_ "GenSigTimeoutTime_RFHM" SG_ 1449 FOBSearchActive 0;
BA_ "GenSigTimeoutTime_MPAD" SG_ 1449 FOBSearchActive 0;
BA_ "GenSigTimeoutTime_IPC" SG_ 1449 FOBSearchActive 0;
BA_ "GenSigTimeoutTime_GNMM" SG_ 1449 FOBSearchActive 0;
BA_ "GenSigTimeoutTime_EVCU2" SG_ 1449 FOBSearchActive 0;
BA_ "GenSigTimeoutTime_ESL" SG_ 1449 FOBSearchActive 0;
BA_ "GenSigTimeoutTime_ECM" SG_ 1449 FOBSearchActive 0;
BA_ "GenSigTimeoutTime_DTCM" SG_ 1449 FOBSearchActive 0;
BA_ "GenSigTimeoutTime_DMSM" SG_ 1449 FOBSearchActive 0;
BA_ "GenSigTimeoutTime_BSM" SG_ 1449 FOBSearchActive 0;
BA_ "GenSigTimeoutTime_BCM" SG_ 1449 FOBSearchActive 0;
BA_ "GenSigTimeoutTime_AGSM" SG_ 1449 FOBSearchActive 0;
BA_ "GenSigTimeoutTime_ADCAM" SG_ 1449 FOBSearchActive 0;
BA_ "GenSigSendType" SG_ 1449 FOBSearchActive 3;
BA_ "GenSigTimeoutTime_SGW" SG_ 519 MessageCounter_RFHUB1 0;
BA_ "GenSigTimeoutTime_RFHM" SG_ 519 MessageCounter_RFHUB1 0;
BA_ "GenSigTimeoutTime_MPAD" SG_ 519 MessageCounter_RFHUB1 0;
BA_ "GenSigTimeoutTime_IPC" SG_ 519 MessageCounter_RFHUB1 0;
BA_ "GenSigTimeoutTime_GNMM" SG_ 519 MessageCounter_RFHUB1 0;
BA_ "GenSigTimeoutTime_EVCU2" SG_ 519 MessageCounter_RFHUB1 0;
BA_ "GenSigTimeoutTime_ESL" SG_ 519 MessageCounter_RFHUB1 0;
BA_ "GenSigTimeoutTime_ECM" SG_ 519 MessageCounter_RFHUB1 0;
BA_ "GenSigTimeoutTime_DTCM" SG_ 519 MessageCounter_RFHUB1 0;
BA_ "GenSigTimeoutTime_DMSM" SG_ 519 MessageCounter_RFHUB1 0;
BA_ "GenSigTimeoutTime_BSM" SG_ 519 MessageCounter_RFHUB1 0;
BA_ "GenSigTimeoutTime_BCM" SG_ 519 MessageCounter_RFHUB1 0;
BA_ "GenSigTimeoutTime_AGSM" SG_ 519 MessageCounter_RFHUB1 0;
BA_ "GenSigTimeoutTime_ADCAM" SG_ 519 MessageCounter_RFHUB1 0;
BA_ "GenSigTimeoutTime_ADCAM" SG_ 519 CRC_RFHUB1 0;
BA_ "GenSigTimeoutTime_SGW" SG_ 519 CRC_RFHUB1 0;
BA_ "GenSigTimeoutTime_RFHM" SG_ 519 CRC_RFHUB1 0;
BA_ "GenSigTimeoutTime_MPAD" SG_ 519 CRC_RFHUB1 0;
BA_ "GenSigTimeoutTime_IPC" SG_ 519 CRC_RFHUB1 0;
BA_ "GenSigTimeoutTime_GNMM" SG_ 519 CRC_RFHUB1 0;
BA_ "GenSigTimeoutTime_EVCU2" SG_ 519 CRC_RFHUB1 0;
BA_ "GenSigTimeoutTime_ESL" SG_ 519 CRC_RFHUB1 0;
BA_ "GenSigTimeoutTime_ECM" SG_ 519 CRC_RFHUB1 0;
BA_ "GenSigTimeoutTime_DTCM" SG_ 519 CRC_RFHUB1 0;
BA_ "GenSigTimeoutTime_DMSM" SG_ 519 CRC_RFHUB1 0;
BA_ "GenSigTimeoutTime_BSM" SG_ 519 CRC_RFHUB1 0;
BA_ "GenSigTimeoutTime_BCM" SG_ 519 CRC_RFHUB1 0;
BA_ "GenSigTimeoutTime_AGSM" SG_ 519 CRC_RFHUB1 0;
BA_ "GenSigTimeoutTime_ECM" SG_ 1449 MsgFOBLeftVeh 0;
BA_ "GenSigTimeoutTime_DTCM" SG_ 1449 MsgFOBLeftVeh 0;
BA_ "GenSigTimeoutTime_DMSM" SG_ 1449 MsgFOBLeftVeh 0;
BA_ "GenSigTimeoutTime_BSM" SG_ 1449 MsgFOBLeftVeh 0;
BA_ "GenSigTimeoutTime_AGSM" SG_ 1449 MsgFOBLeftVeh 0;
BA_ "GenSigTimeoutTime_ADCAM" SG_ 1449 MsgFOBLeftVeh 0;
BA_ "GenSigSendType" SG_ 1449 MsgFOBLeftVeh 3;
BA_ "GenSigTimeoutTime_SGW" SG_ 519 DriverEngineOffRequest 0;
BA_ "GenSigTimeoutTime_RFHM" SG_ 519 DriverEngineOffRequest 0;
BA_ "GenSigTimeoutTime_MPAD" SG_ 519 DriverEngineOffRequest 0;
BA_ "GenSigTimeoutTime_IPC" SG_ 519 DriverEngineOffRequest 0;
BA_ "GenSigTimeoutTime_GNMM" SG_ 519 DriverEngineOffRequest 0;
BA_ "GenSigTimeoutTime_ESL" SG_ 519 DriverEngineOffRequest 0;
BA_ "GenSigTimeoutTime_ECM" SG_ 519 DriverEngineOffRequest 0;
BA_ "GenSigTimeoutTime_DTCM" SG_ 519 DriverEngineOffRequest 0;
BA_ "GenSigTimeoutTime_DMSM" SG_ 519 DriverEngineOffRequest 0;
BA_ "GenSigTimeoutTime_BSM" SG_ 519 DriverEngineOffRequest 0;
BA_ "GenSigTimeoutTime_AGSM" SG_ 519 DriverEngineOffRequest 0;
BA_ "GenSigTimeoutTime_ADCAM" SG_ 519 DriverEngineOffRequest 0;
BA_ "GenSigTimeoutTime_SGW" SG_ 519 FobSearchResult 0;
BA_ "GenSigTimeoutTime_RFHM" SG_ 519 FobSearchResult 0;
BA_ "GenSigTimeoutTime_MPAD" SG_ 519 FobSearchResult 0;
BA_ "GenSigTimeoutTime_IPC" SG_ 519 FobSearchResult 0;
BA_ "GenSigTimeoutTime_GNMM" SG_ 519 FobSearchResult 0;
BA_ "GenSigTimeoutTime_EVCU2" SG_ 519 FobSearchResult 0;
BA_ "GenSigTimeoutTime_ESL" SG_ 519 FobSearchResult 0;
BA_ "GenSigTimeoutTime_ECM" SG_ 519 FobSearchResult 0;
BA_ "GenSigTimeoutTime_DTCM" SG_ 519 FobSearchResult 0;
BA_ "GenSigTimeoutTime_DMSM" SG_ 519 FobSearchResult 0;
BA_ "GenSigTimeoutTime_BSM" SG_ 519 FobSearchResult 0;
BA_ "GenSigTimeoutTime_AGSM" SG_ 519 FobSearchResult 0;
BA_ "GenSigTimeoutTime_ADCAM" SG_ 519 FobSearchResult 0;
BA_ "GenSigTimeoutTime_RFHM" SG_ 519 IgnPosSts 0;
BA_ "GenSigTimeoutTime_MPAD" SG_ 519 IgnPosSts 0;
BA_ "GenSigTimeoutTime_IPC" SG_ 519 IgnPosSts 0;
BA_ "GenSigTimeoutTime_GNMM" SG_ 519 IgnPosSts 0;
BA_ "GenSigTimeoutTime_EVCU2" SG_ 519 IgnPosSts 0;
BA_ "GenSigTimeoutTime_ESL" SG_ 519 IgnPosSts 0;
BA_ "GenSigTimeoutTime_ECM" SG_ 519 IgnPosSts 0;
BA_ "GenSigTimeoutTime_DTCM" SG_ 519 IgnPosSts 0;
BA_ "GenSigTimeoutTime_DMSM" SG_ 519 IgnPosSts 0;
BA_ "GenSigTimeoutTime_BSM" SG_ 519 IgnPosSts 0;
BA_ "GenSigTimeoutTime_AGSM" SG_ 519 IgnPosSts 0;
BA_ "GenSigTimeoutTime_ADCAM" SG_ 519 IgnPosSts 0;
BA_ "GenSigTimeoutTime_SGW" SG_ 1449 KeyProgramSts 0;
BA_ "GenSigTimeoutTime_RFHM" SG_ 1449 KeyProgramSts 0;
BA_ "GenSigTimeoutTime_MPAD" SG_ 1449 KeyProgramSts 0;
BA_ "GenSigTimeoutTime_GNMM" SG_ 1449 KeyProgramSts 0;
BA_ "GenSigTimeoutTime_EVCU2" SG_ 1449 KeyProgramSts 0;
BA_ "GenSigTimeoutTime_ESL" SG_ 1449 KeyProgramSts 0;
BA_ "GenSigTimeoutTime_ECM" SG_ 1449 KeyProgramSts 0;
BA_ "GenSigTimeoutTime_DTCM" SG_ 1449 KeyProgramSts 0;
BA_ "GenSigTimeoutTime_DMSM" SG_ 1449 KeyProgramSts 0;
BA_ "GenSigTimeoutTime_BSM" SG_ 1449 KeyProgramSts 0;
BA_ "GenSigTimeoutTime_BCM" SG_ 1449 KeyProgramSts 0;
BA_ "GenSigTimeoutTime_AGSM" SG_ 1449 KeyProgramSts 0;
BA_ "GenSigTimeoutTime_ADCAM" SG_ 1449 KeyProgramSts 0;
BA_ "GenSigSendType" SG_ 1449 KeyProgramSts 3;
BA_ "GenSigTimeoutTime_RFHM" SG_ 519 RFReq 0;
BA_ "GenSigTimeoutTime_MPAD" SG_ 519 RFReq 0;
BA_ "GenSigTimeoutTime_GNMM" SG_ 519 RFReq 0;
BA_ "GenSigTimeoutTime_EVCU2" SG_ 519 RFReq 0;
BA_ "GenSigTimeoutTime_ESL" SG_ 519 RFReq 0;
BA_ "GenSigTimeoutTime_ECM" SG_ 519 RFReq 0;
BA_ "GenSigTimeoutTime_DTCM" SG_ 519 RFReq 0;
BA_ "GenSigTimeoutTime_DMSM" SG_ 519 RFReq 0;
BA_ "GenSigTimeoutTime_BSM" SG_ 519 RFReq 0;
BA_ "GenSigTimeoutTime_AGSM" SG_ 519 RFReq 0;
BA_ "GenSigTimeoutTime_ADCAM" SG_ 519 RFReq 0;
BA_ "GenSigTimeoutTime_RFHM" SG_ 519 CustKeyInIgnSts 0;
BA_ "GenSigTimeoutTime_MPAD" SG_ 519 CustKeyInIgnSts 0;
BA_ "GenSigTimeoutTime_IPC" SG_ 519 CustKeyInIgnSts 0;
BA_ "GenSigTimeoutTime_GNMM" SG_ 519 CustKeyInIgnSts 0;
BA_ "GenSigTimeoutTime_EVCU2" SG_ 519 CustKeyInIgnSts 0;
BA_ "GenSigTimeoutTime_ESL" SG_ 519 CustKeyInIgnSts 0;
BA_ "GenSigTimeoutTime_ECM" SG_ 519 CustKeyInIgnSts 0;
BA_ "GenSigTimeoutTime_DTCM" SG_ 519 CustKeyInIgnSts 0;
BA_ "GenSigTimeoutTime_DMSM" SG_ 519 CustKeyInIgnSts 0;
BA_ "GenSigTimeoutTime_BSM" SG_ 519 CustKeyInIgnSts 0;
BA_ "GenSigTimeoutTime_AGSM" SG_ 519 CustKeyInIgnSts 0;
BA_ "GenSigTimeoutTime_ADCAM" SG_ 519 CustKeyInIgnSts 0;
BA_ "GenSigTimeoutTime_SGW" SG_ 156 Year4_TLM 0;
BA_ "GenSigTimeoutTime_MPAD" SG_ 156 Year4_TLM 0;
BA_ "GenSigTimeoutTime_IPC" SG_ 156 Year4_TLM 0;
BA_ "GenSigTimeoutTime_GNMM" SG_ 156 Year4_TLM 0;
BA_ "GenSigTimeoutTime_ESL" SG_ 156 Year4_TLM 0;
BA_ "GenSigTimeoutTime_ECM" SG_ 156 Year4_TLM 0;
BA_ "GenSigTimeoutTime_DTCM" SG_ 156 Year4_TLM 0;
BA_ "GenSigTimeoutTime_DMSM" SG_ 156 Year4_TLM 0;
BA_ "GenSigTimeoutTime_BSM" SG_ 156 Year4_TLM 0;
BA_ "GenSigTimeoutTime_BCM" SG_ 156 Year4_TLM 0;
BA_ "GenSigTimeoutTime_AGSM" SG_ 156 Year4_TLM 0;
BA_ "GenSigTimeoutTime_ADCAM" SG_ 156 Year4_TLM 0;
BA_ "GenSigTimeoutTime_SGW" SG_ 156 Year1_TLM 0;
BA_ "GenSigTimeoutTime_MPAD" SG_ 156 Year1_TLM 0;
BA_ "GenSigTimeoutTime_IPC" SG_ 156 Year1_TLM 0;
BA_ "GenSigTimeoutTime_GNMM" SG_ 156 Year1_TLM 0;
BA_ "GenSigTimeoutTime_ESL" SG_ 156 Year1_TLM 0;
BA_ "GenSigTimeoutTime_ECM" SG_ 156 Year1_TLM 0;
BA_ "GenSigTimeoutTime_DTCM" SG_ 156 Year1_TLM 0;
BA_ "GenSigTimeoutTime_DMSM" SG_ 156 Year1_TLM 0;
BA_ "GenSigTimeoutTime_BSM" SG_ 156 Year1_TLM 0;
BA_ "GenSigTimeoutTime_BCM" SG_ 156 Year1_TLM 0;
BA_ "GenSigTimeoutTime_AGSM" SG_ 156 Year1_TLM 0;
BA_ "GenSigTimeoutTime_ADCAM" SG_ 156 Year1_TLM 0;
BA_ "GenSigTimeoutTime_SGW" SG_ 156 Year2_TLM 0;
BA_ "GenSigTimeoutTime_MPAD" SG_ 156 Year2_TLM 0;
BA_ "GenSigTimeoutTime_IPC" SG_ 156 Year2_TLM 0;
BA_ "GenSigTimeoutTime_GNMM" SG_ 156 Year2_TLM 0;
BA_ "GenSigTimeoutTime_ESL" SG_ 156 Year2_TLM 0;
BA_ "GenSigTimeoutTime_ECM" SG_ 156 Year2_TLM 0;
BA_ "GenSigTimeoutTime_DTCM" SG_ 156 Year2_TLM 0;
BA_ "GenSigTimeoutTime_DMSM" SG_ 156 Year2_TLM 0;
BA_ "GenSigTimeoutTime_BSM" SG_ 156 Year2_TLM 0;
BA_ "GenSigTimeoutTime_BCM" SG_ 156 Year2_TLM 0;
BA_ "GenSigTimeoutTime_AGSM" SG_ 156 Year2_TLM 0;
BA_ "GenSigTimeoutTime_ADCAM" SG_ 156 Year2_TLM 0;
BA_ "GenSigTimeoutTime_SGW" SG_ 156 Year3_TLM 0;
BA_ "GenSigTimeoutTime_MPAD" SG_ 156 Year3_TLM 0;
BA_ "GenSigTimeoutTime_IPC" SG_ 156 Year3_TLM 0;
BA_ "GenSigTimeoutTime_GNMM" SG_ 156 Year3_TLM 0;
BA_ "GenSigTimeoutTime_ESL" SG_ 156 Year3_TLM 0;
BA_ "GenSigTimeoutTime_ECM" SG_ 156 Year3_TLM 0;
BA_ "GenSigTimeoutTime_DTCM" SG_ 156 Year3_TLM 0;
BA_ "GenSigTimeoutTime_DMSM" SG_ 156 Year3_TLM 0;
BA_ "GenSigTimeoutTime_BSM" SG_ 156 Year3_TLM 0;
BA_ "GenSigTimeoutTime_BCM" SG_ 156 Year3_TLM 0;
BA_ "GenSigTimeoutTime_AGSM" SG_ 156 Year3_TLM 0;
BA_ "GenSigTimeoutTime_ADCAM" SG_ 156 Year3_TLM 0;
BA_ "GenSigTimeoutTime_SGW" SG_ 1428 MessageCounter_Telematic5 0;
BA_ "GenSigTimeoutTime_RFHM" SG_ 1428 MessageCounter_Telematic5 0;
BA_ "GenSigTimeoutTime_GNMM" SG_ 1428 MessageCounter_Telematic5 0;
BA_ "GenSigTimeoutTime_EVCU2" SG_ 1428 MessageCounter_Telematic5 0;
BA_ "GenSigTimeoutTime_ESL" SG_ 1428 MessageCounter_Telematic5 0;
BA_ "GenSigTimeoutTime_ECM" SG_ 1428 MessageCounter_Telematic5 0;
BA_ "GenSigTimeoutTime_DTCM" SG_ 1428 MessageCounter_Telematic5 0;
BA_ "GenSigTimeoutTime_DMSM" SG_ 1428 MessageCounter_Telematic5 0;
BA_ "GenSigTimeoutTime_BSM" SG_ 1428 MessageCounter_Telematic5 0;
BA_ "GenSigTimeoutTime_AGSM" SG_ 1428 MessageCounter_Telematic5 0;
BA_ "GenSigTimeoutTime_ADCAM" SG_ 1428 MessageCounter_Telematic5 0;
BA_ "GenSigTimeoutTime_SGW" SG_ 1428 CRC_Telematic5 0;
BA_ "GenSigTimeoutTime_RFHM" SG_ 1428 CRC_Telematic5 0;
BA_ "GenSigTimeoutTime_GNMM" SG_ 1428 CRC_Telematic5 0;
BA_ "GenSigTimeoutTime_EVCU2" SG_ 1428 CRC_Telematic5 0;
BA_ "GenSigTimeoutTime_ESL" SG_ 1428 CRC_Telematic5 0;
BA_ "GenSigTimeoutTime_ECM" SG_ 1428 CRC_Telematic5 0;
BA_ "GenSigTimeoutTime_DTCM" SG_ 1428 CRC_Telematic5 0;
BA_ "GenSigTimeoutTime_DMSM" SG_ 1428 CRC_Telematic5 0;
BA_ "GenSigTimeoutTime_BSM" SG_ 1428 CRC_Telematic5 0;
BA_ "GenSigTimeoutTime_AGSM" SG_ 1428 CRC_Telematic5 0;
VAL_ 1053 VIN_MSG 0 "VIN_LO" 1 "VIN_MID" 2 "VIN_HI" 3 "SNA";
VAL_ 254 TotalFrameNumber 0 "One_Frame" 1 "Two_Frames" 2 "Three_Frames" 3 "Four_Frames" 4 "Five_Frames" 5 "Six_Frames" 6 "Seven_Frames" 7 "Eight_Frame" 8 "Nine_Frames" 9 "Ten_Frames" 10 "Eleven_Frames" 11 "Twelve_Frames" 12 "Thirteen_Frames" 13 "Fourteen_Frames" 14 "Fifteen_Frames" 15 "Sixteen_Frames";
VAL_ 254 FrameNumber 0 "Frame_1" 1 "Frame_2" 2 "Frame_3" 3 "Frame_4" 4 "Frame_5" 5 "Frame_6" 6 "Frame_7" 7 "Frame_8" 8 "Frame_9" 9 "Frame_10" 10 "Frame_11" 11 "Frame_12" 12 "Frame_13" 13 "Frame_14" 14 "Frame_15" 15 "Frame_16";
VAL_ 1059 TxpFound 0 "Transponder_Read" 1 "Transponder_Absent";
VAL_ 1059 ProgrammedSts_TRM 0 "Not_Programmed" 1 "Programmed";
VAL_ 1059 CodeCheckSts_TRM 0 "No_Code" 1 "CodeCheck_OK" 2 "CodeCheck_Fault" 3 "Not_Used";
VAL_ 1450 OilTemperatureSts 0 "Normal" 1 "High";
VAL_ 1428 HU_CMP 0 "CMP_N" 1 "CMP_N_E" 2 "CMP_E" 3 "CMP_S_E" 4 "CMP_S" 5 "CMP_S_W" 6 "CMP_W" 7 "CMP_N_W" 8 "NONE" 15 "SNA";
VAL_ 1378 ESLSts 0 "Undefined_Position" 1 "Not_Used" 2 "Not_Used" 3 "Lock" 4 "Not_Used" 5 "Unlock" 6 "SNA" 7 "Not_Used";
VAL_ 1876 TyrePressureSystemFailSts 0 "Fail_Not_Present" 1 "Fail_Present";
VAL_ 1876 TyrePressureSysProgrammedSts 0 "System_Programmed" 1 "System_Not_Programmed";
VAL_ 1876 TPMActivitySts 0 "TPM_Enabled" 1 "TPM_Disabled";
VAL_ 1876 InflationState_RHR_Tyre 0 "Normal_Tyre_Pressure" 1 "Under_Inflated_Tyre" 2 "SignificantlyUnderInflatedTyre" 3 "Over_Inflated_Tyre" 4 "Sensor_Missing";
VAL_ 1876 InflationState_RHF_Tyre 0 "Normal_Tyre_Pressure" 1 "Under_Inflated_Tyre" 2 "SignificantlyUnderInflatedTyre" 3 "Over_Inflated_Tyre" 4 "Sensor_Missing";
VAL_ 1876 InflationState_LHR_Tyre 0 "Normal_Tyre_Pressure" 1 "Under_Inflated_Tyre" 2 "SignificantlyUnderInflatedTyre" 3 "Over_Inflated_Tyre" 4 "Sensor_Missing";
VAL_ 1876 InflationState_LHF_Tyre 0 "Normal_Tyre_Pressure" 1 "Under_Inflated_Tyre" 2 "SignificantlyUnderInflatedTyre" 3 "Over_Inflated_Tyre" 4 "Sensor_Missing";
VAL_ 1449 MsgNotInPark 0 "MSG_DEFAULT" 1 "MSG_ACTIVE" 3 "SNA";
VAL_ 1449 MsgFOBNotFnd 0 "MSG_DEFAULT" 1 "MSG_ACTIVE" 3 "SNA";
VAL_ 1449 MsgFOBLeftVeh 0 "MSG_DEFAULT" 1 "MSG_ACTIVE" 3 "SNA";
VAL_ 1449 KeyProgramSts 0 "RKE_NORM_STAT" 1 "EN_KEY_PROG" 2 "PROG_ACT" 3 "EX_KEY_PROG" 4 "KEY_PROG" 5 "DMG_KEY" 6 "INV_KEY" 7 "EXCD_KEY" 8 "RKE_BATT_LO" 9 "SRV_SKREEM" 10 "BTN_DLY_ACT" 11 "BTN_DLY_INACT" 12 "KEY_NOT_PROG" 15 "SNA";
VAL_ 519 RFReq 0 "REQUESTOR_DEFAULT" 1 "REQUESTOR_RKE" 2 "REQUESTOR_PE" 3 "REQUESTOR_REMOTESTART" 4 "REQUESTOR_UCONNECT" 5 "REQUESTOR_PE_HANDSFREE" 6 "REQUESTOR_PROXIMITY" 7 "SNA";
VAL_ 519 IgnPosSts 0 "Initialization" 1 "IGN_LK" 3 "ACC" 4 "RUN" 5 "START" 7 "SNA";
VAL_ 519 DriverEngineOffRequest 0 "Not_Active" 1 "Active";
VAL_ 519 CustKeyInIgnSts 0 "CUST_KEY_DEFAULT" 1 "CUST_KEY_NOT_IN_IGNITION" 2 "CUST_KEY_IN_IGNITION" 3 "SNA";
VAL_ 1428 NAV_UNITS 0 "NO_UNITS" 1 "MILE" 2 "FEET" 3 "KM" 4 "METER" 5 "YARD" 7 "SNA";
VAL_ 1428 DIST_TO_TURN 65535 "SNA";
VAL_ 1449 RFMemRq 0 "Not_Active" 1 "Active";
VAL_ 1449 FOBSearchActive 0 "not_active" 1 "active";
VAL_ 1428 TURN_COMP 0 "turn_not_complete" 1 "complete";
VAL_ 1428 T_BY_T_ON 0 "Off" 1 "On";
VAL_ 1428 NAVPrsnt 0 "Absent" 1 "Present";
VAL_ 1428 NAV_ARROW 0 "NAV_NOT_ACT";
VAL_ 156 GPS_UTC_Second 65535 "SNA";
VAL_ 156 GPS_UTC_Minute 255 "SNA";
VAL_ 156 GPS_UTC_Hour 255 "SNA";
VAL_ 156 GPS_Date_Year 65535 "SNA";
VAL_ 156 GPS_Date_Month 255 "SNA";
VAL_ 156 GPS_Date_Day 255 "SNA";
VAL_ 1876 PressureValue_RHR_Tyre 255 "SNA";
VAL_ 1876 PressureValue_RHF_Tyre 255 "SNA";
VAL_ 1876 PressureValue_LHR_Tyre 255 "SNA";
VAL_ 1876 PressureValue_LHF_Tyre 255 "SNA";
VAL_ 1449 MsgPushBtnKey 0 "MSG_DEFAULT" 1 "MSG_ACTIVE" 3 "SNA";
VAL_ 1449 TPMHornChirp 0 "HORN_CHIRP_OFF" 1 "SINGLE_HORN_CHIRP" 2 "MULTIPLE_HORN_CHIRP" 3 "SNA";
VAL_ 1449 TPMHazardFlash 0 "False" 1 "TRUE";
VAL_ 1449 STFASysEnableFault 0 "Absent" 1 "Present";
VAL_ 1449 KeyFob_Present 0 "Not_Present" 1 "Present";
VAL_ 156 STFARrAlertPress 255 "SNA";
VAL_ 156 STFAFtAlertPress 255 "SNA";
VAL_ 519 RFFuncReq 0 "NO_BASIC_REQUEST" 1 "LOCK_REQUEST" 2 "RELOCK_REQUEST" 3 "DRIVER_UNLOCK_REQUEST" 4 "ALL_UNLOCK_REQUEST" 5 "TRUNK_PLG_TOGGLE_REQUEST" 6 "LEFT_SLIDER_TOGGLE_REQUEST" 7 "RIGHT_SLIDER_TOGGLE_REQUEST" 8 "FLIPPER_GLASS_REQUEST" 9 "REMOTE_START_ON" 10 "REMOTE_START_OFF" 11 "GLOBAL_WINDOW_DOWN_REQUEST" 12 "OPEN_CONVERTIBLE_TOP" 13 "CLOSE_CONVERTIBLE_TOP" 14 "PANIC_TOGGLE_REQUEST" 15 "DEAD_LOCK_REQUEST" 16 "GLOBAL_WINDOWS_UP_REQUEST" 17 "HEADLIGHTS_OFF_DELAY" 18 "TRUNK_PLG_STOP_REQUEST" 19 "ABORT_CRANKING_ON_REQUEST" 20 "ABORT_CRANKING_OFF_REQUEST" 21 "PRE_COND_ON" 22 "PRE_COND_OFF" 23 "AUTHENTICATION_REQUEST" 24 "CAR_FINDER_REQUEST" 25 "AirSuspReq" 26 "AirSuspCancel" 27 "ExtLightReq" 28 "Remote_Headlights" 30 "HOOD_TOGGLE_REQUEST" 31 "SNA";
VAL_ 156 TSI_Offset_Mph_Req 0 "0" 1 "1" 2 "2" 3 "3" 4 "4" 5 "5" 6 "6" 7 "7" 8 "8" 9 "9" 10 "10";
VAL_ 156 TSI_Offset_Kph_Req 0 "0" 1 "1" 2 "2" 3 "3" 4 "4" 5 "5" 6 "6" 7 "7" 8 "8" 9 "9" 10 "10" 11 "11" 12 "12" 13 "13" 14 "14" 15 "15";
VAL_ 156 ParkSenseSignalView_Req 0 "Disable" 1 "Enable";
VAL_ 156 TurnSignalView_Req 0 "Disable" 1 "Enable" 2 "Only_with_Trailer";
VAL_ 156 Fuel_Saver_Display_Req 0 "Disable" 1 "Enable";
VAL_ 156 EPB_Service_Mode_Req 0 "Disable" 1 "Enable";
VAL_ 1449 MsgKeyNotFnd 0 "MSG_DEFAULT" 1 "MSG_ACTIVE" 2 "MSG_ACCESS_DENIED" 3 "SNA";
VAL_ 1059 TxpID3 0 "Transponder_Not_Authenticated" 1 "Transponder_1_Authenticated" 2 "Transponder_2_Authenticated" 3 "Transponder_3_Authenticated" 4 "Transponder_4_Authenticated" 5 "Transponder_5_Authenticated" 6 "Transponder_6_Authenticated" 7 "Transponder_7_Authenticated" 8 "Transponder_8_Authenticated" 9 "Transponder_9_Authenticated" 10 "Transponder_10_Authenticated" 11 "Transponder_11_Authenticated" 12 "Transponder_12_Authenticated" 13 "Transponder_13_Authenticated" 14 "Transponder_14_Authenticated" 15 "Transponder_15_Authenticated" 16 "Transponder_16_Authenticated" 17 "Transponder_17_Authenticated" 18 "Transponder_18_Authenticated" 19 "Transponder_19_Authenticated" 20 "Transponder_20_Authenticated" 21 "Transponder_21_Authenticated" 22 "Transponder_22_Authenticated" 23 "Transponder_23_Authenticated" 24 "Transponder_24_Authenticated" 25 "Transponder_25_Authenticated" 26 "Transponder_26_Authenticated" 27 "Transponder_27_Authenticated" 28 "Transponder_28_Authenticated" 29 "Transponder_29_Authenticated" 30 "Transponder_30_Authenticated" 31 "Transponder_31_Authenticated" 32 "Transponder_32_Authenticated" 33 "Transponder_33_Authenticated" 34 "Transponder_34_Authenticated" 35 "Transponder_35_Authenticated" 36 "Transponder_36_Authenticated" 37 "Transponder_37_Authenticated" 38 "Transponder_38_Authenticated" 39 "Transponder_39_Authenticated" 40 "Transponder_40_Authenticated" 41 "Transponder_41_Authenticated" 42 "Transponder_42_Authenticated" 43 "Transponder_43_Authenticated" 44 "Transponder_44_Authenticated" 45 "Transponder_45_Authenticated" 46 "Transponder_46_Authenticated" 47 "Transponder_47_Authenticated" 48 "Transponder_48_Authenticated" 49 "Transponder_49_Authenticated" 50 "Transponder_50_Authenticated" 51 "Transponder_51_Authenticated" 52 "Transponder_52_Authenticated" 53 "Transponder_53_Authenticated" 54 "Transponder_54_Authenticated" 55 "Transponder_55_Authenticated" 56 "Transponder_56_Authenticated" 57 "Transponder_57_Authenticated" 58 "Transponder_58_Authenticated" 59 "Transponder_59_Authenticated" 60 "Transponder_60_Authenticated" 61 "Transponder_61_Authenticated" 62 "Transponder_62_Authenticated" 63 "Transponder_63_Authenticated" 64 "Transponder_64_Authenticated" 65 "Transponder_65_Authenticated" 66 "Transponder_66_Authenticated" 67 "Transponder_67_Authenticated" 68 "Transponder_68_Authenticated" 69 "Transponder_69_Authenticated" 70 "Transponder_70_Authenticated" 71 "Transponder_71_Authenticated" 72 "Transponder_72_Authenticated" 73 "Transponder_73_Authenticated" 74 "Transponder_74_Authenticated" 75 "Transponder_75_Authenticated" 76 "Transponder_76_Authenticated" 77 "Transponder_77_Authenticated" 78 "Transponder_78_Authenticated" 79 "Transponder_79_Authenticated" 80 "Transponder_80_Authenticated" 81 "Transponder_81_Authenticated" 82 "Transponder_82_Authenticated" 83 "Transponder_83_Authenticated" 84 "Transponder_84_Authenticated" 85 "Transponder_85_Authenticated" 86 "Transponder_86_Authenticated" 87 "Transponder_87_Authenticated" 88 "Transponder_88_Authenticated" 89 "Transponder_89_Authenticated" 90 "Transponder_90_Authenticated" 91 "Transponder_91_Authenticated" 92 "Transponder_92_Authenticated" 93 "Transponder_93_Authenticated" 94 "Transponder_94_Authenticated" 95 "Transponder_95_Authenticated" 96 "Transponder_96_Authenticated" 97 "Transponder_97_Authenticated" 98 "Transponder_98_Authenticated" 99 "Transponder_99_Authenticated" 100 "Transponder_100_Authenticated" 101 "Transponder_101_Authenticated";
VAL_ 1449 MemRq_FobNum3 0 "FOB_DEFAULT" 1 "FOB_1" 2 "FOB_2" 3 "FOB_3" 4 "FOB_4" 5 "FOB_5" 6 "FOB_6" 7 "FOB_7" 8 "FOB_8" 9 "PHONEDEVICE_9" 10 "PHONEDEVICE_10" 11 "PHONEDEVICE_11" 12 "PHONEDEVICE_12" 13 "PHONEDEVICE_13" 14 "PHONEDEVICE_14" 15 "PHONEDEVICE_15" 16 "PHONEDEVICE_16" 17 "PHONEDEVICE_17" 18 "PHONEDEVICE_18" 19 "PHONEDEVICE_19" 20 "PHONEDEVICE_20" 21 "PHONEDEVICE_21" 22 "PHONEDEVICE_22" 23 "PHONEDEVICE_23" 24 "PHONEDEVICE_24" 25 "PHONEDEVICE_25" 26 "PHONEDEVICE_26" 27 "PHONEDEVICE_27" 28 "PHONEDEVICE_28" 29 "PHONEDEVICE_29" 30 "PHONEDEVICE_30" 31 "PHONEDEVICE_31" 32 "PHONEDEVICE_32" 33 "PHONEDEVICE_33" 34 "PHONEDEVICE_34" 35 "PHONEDEVICE_35" 36 "PHONEDEVICE_36" 37 "PHONEDEVICE_37" 38 "PHONEDEVICE_38" 39 "PHONEDEVICE_39" 40 "PHONEDEVICE_40" 41 "PHONEDEVICE_41" 42 "PHONEDEVICE_42" 43 "PHONEDEVICE_43" 44 "PHONEDEVICE_44" 45 "PHONEDEVICE_45" 46 "PHONEDEVICE_46" 47 "PHONEDEVICE_47" 48 "PHONEDEVICE_48" 49 "PHONEDEVICE_49" 50 "PHONEDEVICE_50" 51 "PHONEDEVICE_51" 52 "PHONEDEVICE_52" 53 "PHONEDEVICE_53" 54 "PHONEDEVICE_54" 55 "PHONEDEVICE_55" 56 "PHONEDEVICE_56" 57 "PHONEDEVICE_57" 58 "PHONEDEVICE_58" 59 "PHONEDEVICE_59" 60 "PHONEDEVICE_60" 61 "PHONEDEVICE_61" 62 "PHONEDEVICE_62" 63 "PHONEDEVICE_63" 64 "PHONEDEVICE_64" 65 "PHONEDEVICE_65" 66 "PHONEDEVICE_66" 67 "PHONEDEVICE_67" 68 "PHONEDEVICE_68" 69 "PHONEDEVICE_69" 70 "PHONEDEVICE_70" 71 "PHONEDEVICE_71" 72 "PHONEDEVICE_72" 73 "PHONEDEVICE_73" 74 "PHONEDEVICE_74" 75 "PHONEDEVICE_75" 76 "PHONEDEVICE_76" 77 "PHONEDEVICE_77" 78 "PHONEDEVICE_78" 79 "PHONEDEVICE_79" 80 "PHONEDEVICE_80" 81 "PHONEDEVICE_81" 82 "PHONEDEVICE_82" 83 "PHONEDEVICE_83" 84 "PHONEDEVICE_84" 85 "PHONEDEVICE_85" 86 "PHONEDEVICE_86" 87 "PHONEDEVICE_87" 88 "PHONEDEVICE_88" 89 "PHONEDEVICE_89" 90 "PHONEDEVICE_90" 91 "PHONEDEVICE_91" 92 "PHONEDEVICE_92" 93 "PHONEDEVICE_93" 94 "PHONEDEVICE_94" 95 "PHONEDEVICE_95" 96 "PHONEDEVICE_96" 97 "PHONEDEVICE_97" 98 "PHONEDEVICE_98" 99 "PHONEDEVICE_99" 100 "PHONEDEVICE_100" 101 "PHONEDEVICE_101" 127 "SNA";
VAL_ 519 ValetMode_SPAAK 0 "False" 1 "True";
VAL_ 519 RFFobNum3 0 "FOB_DEFAULT" 1 "FOB_1" 2 "FOB_2" 3 "FOB_3" 4 "FOB_4" 5 "FOB_5" 6 "FOB_6" 7 "FOB_7" 8 "FOB_8" 9 "KeySlotID_09" 10 "KeySlotID_10" 11 "KeySlotID_11" 12 "KeySlotID_12" 13 "KeySlotID_13" 14 "KeySlotID_14" 15 "KeySlotID_15" 16 "KeySlotID_16" 17 "KeySlotID_17" 18 "KeySlotID_18" 19 "KeySlotID_19" 20 "KeySlotID_20" 21 "KeySlotID_21" 22 "KeySlotID_22" 23 "KeySlotID_23" 24 "KeySlotID_24" 25 "KeySlotID_25" 26 "KeySlotID_26" 27 "KeySlotID_27" 28 "KeySlotID_28" 29 "KeySlotID_29" 30 "KeySlotID_30" 31 "KeySlotID_31" 32 "KeySlotID_32" 33 "KeySlotID_33" 34 "KeySlotID_34" 35 "KeySlotID_35" 36 "KeySlotID_36" 37 "KeySlotID_37" 38 "KeySlotID_38" 39 "KeySlotID_39" 40 "KeySlotID_40" 41 "KeySlotID_41" 42 "KeySlotID_42" 43 "KeySlotID_43" 44 "KeySlotID_44" 45 "KeySlotID_45" 46 "KeySlotID_46" 47 "KeySlotID_47" 48 "KeySlotID_48" 49 "KeySlotID_49" 50 "KeySlotID_50" 51 "KeySlotID_51" 52 "KeySlotID_52" 53 "KeySlotID_53" 54 "KeySlotID_54" 55 "KeySlotID_55" 56 "KeySlotID_56" 57 "KeySlotID_57" 58 "KeySlotID_58" 59 "KeySlotID_59" 60 "KeySlotID_60" 61 "KeySlotID_61" 62 "KeySlotID_62" 63 "KeySlotID_63" 64 "KeySlotID_64" 65 "KeySlotID_65" 66 "KeySlotID_66" 67 "KeySlotID_67" 68 "KeySlotID_68" 69 "KeySlotID_69" 70 "KeySlotID_70" 71 "KeySlotID_71" 72 "KeySlotID_72" 73 "KeySlotID_73" 74 "KeySlotID_74" 75 "KeySlotID_75" 76 "KeySlotID_76" 77 "KeySlotID_77" 78 "KeySlotID_78" 79 "KeySlotID_79" 80 "KeySlotID_80" 81 "KeySlotID_81" 82 "KeySlotID_82" 83 "KeySlotID_83" 84 "KeySlotID_84" 85 "KeySlotID_85" 86 "KeySlotID_86" 87 "KeySlotID_87" 88 "KeySlotID_88" 89 "KeySlotID_89" 90 "KeySlotID_90" 91 "KeySlotID_91" 92 "KeySlotID_92" 93 "KeySlotID_93" 94 "KeySlotID_94" 95 "KeySlotID_95" 96 "KeySlotID_96" 97 "KeySlotID_97" 98 "KeySlotID_98" 99 "KeySlotID_99" 100 "KeySlotID_100" 101 "KeySlotID_101";
VAL_ 519 KeyAuth_Status 0 "NONE" 1 "Auth_InProgress" 2 "Auth_CompletedSNA" 3 "Auth_Failed";
SIG_GROUP_ 1876 RFHUB_FD_3_Pkt 1 : TyrePressureSystemFailSts TyrePressureSysProgrammedSts TPMActivitySts InflationState_RHR_Tyre InflationState_RHF_Tyre InflationState_LHR_Tyre InflationState_LHF_Tyre PressureValue_RHR_Tyre PressureValue_RHF_Tyre PressureValue_LHR_Tyre PressureValue_LHF_Tyre MessageCounter_RFHUB3 CRC_RFHUB3;
SIG_GROUP_ 519 RFHUB_FD_1_Pkt 1 : RFReq IgnPosSts FobSearchResult DriverEngineOffRequest CustKeyInIgnSts MessageCounter_RFHUB1 CRC_RFHUB1 RFFuncReq ValetMode_SPAAK RFFobNum3 KeyAuth_Status;
